VERSION ""

NS_ :

BS_:

BU_: CAM TESTER RS VCU GW ESC ACU TCM
VAL_TABLE_ RS_Sts_Failure 1 "Sensor Failure Occurred" 0 "No Sensor Failure Occured" ;

BO_ 482 PEPS_Message_Sts: 8 GW
 SG_ PEPS_PowerModeValidity : 1|2@0+ (1,0) [0|3] "bit"  RS
 SG_ PEPS_Message_Sts_Checksum : 63|8@0+ (1,0) [0|255] "bit"  RS
 SG_ PEPS_Message_Sts_AliveCounter : 51|4@0+ (1,0) [0|15] "bit"  RS
 SG_ PEPS_PowerMode : 4|3@0+ (1,0) [0|7] "bit"  RS

BO_ 644 BCM_StateUpdate: 8 GW
 SG_ BCM_ATWS_St : 31|3@0+ (1,0) [0|7] "bit"  RS

BO_ 646 BCM_RDoorWindowState: 8 GW
 SG_ BCM_DoorLockStatusRR : 35|2@0+ (1,0) [0|3] "bit"  RS
 SG_ BCM_DoorLockStatusPass : 37|2@0+ (1,0) [0|3] "bit"  RS
 SG_ BCM_RearRightDoorAjarStatus : 33|1@0+ (1,0) [0|1] "bit"  RS
 SG_ BCM_FrontRightDoorAjarStatus : 32|1@0+ (1,0) [0|1] "bit"  RS

BO_ 645 BCM_LDoorWindowState: 8 GW
 SG_ BCM_DoorLockStatusRL : 35|2@0+ (1,0) [0|3] "bit"  RS
 SG_ BCM_DoorLockStatusDrv : 37|2@0+ (1,0) [0|3] "bit"  RS
 SG_ BCM_RearLeftDoorAjarStatus : 33|1@0+ (1,0) [0|1] "bit"  RS
 SG_ BCM_FrontLeftDoorAjarStatus : 32|1@0+ (1,0) [0|1] "bit"  RS

BO_ 496 BCM_LightChimeReq: 8 GW
 SG_ BCM_LightChimeReq_AliveCounter : 51|4@0+ (1,0) [0|15] "bit"  RS
 SG_ BCM_LightChimeReq_CheckSum : 63|8@0+ (1,0) [0|255] "bit"  RS
 SG_ BCM_TurnLeverSts : 5|2@0+ (1,0) [0|3] "bit"  RS

BO_ 1518 RS_Detn_14_Part02: 8 RS
 SG_ RS_Detn14_Elev : 28|5@0+ (1,-15) [-15|15] "Deg"  CAM
 SG_ RS_Detn14_YVelRel : 39|11@0+ (0.1,-102.4) [-102.4|102.3] "m/s"  CAM
 SG_ RS_Detn14_XVelRel : 23|11@0+ (0.1,-102.4) [-102.4|102.3] "m/s"  CAM
 SG_ RS_Detn14_Msg02_CheckSum : 63|8@0+ (1,0) [0|255] "bit"  CAM
 SG_ RS_Detn14_Msg02_AliveCounter : 51|4@0+ (1,0) [0|15] "bit"  CAM
 SG_ RS_Detn14_Qly : 7|16@0+ (1,0) [0|65535] "bit"  CAM
 SG_ RS_Detn14_MotnSts : 55|2@0+ (1,0) [0|3] "bit"  CAM

BO_ 1501 RS_Detn_13_Part01: 8 RS
 SG_ RS_Detn13_Magn : 47|10@0+ (0.1,0) [0|102.3] "dB"  CAM
 SG_ RS_Detn13_Msg01_CheckSum : 63|8@0+ (1,0) [0|255] "bit"  CAM
 SG_ RS_Detn13_Msg01_AliveCounter : 51|4@0+ (1,0) [0|15] "bit"  CAM
 SG_ RS_Detn13_PosY : 31|14@0+ (0.02441,-200) [-200|199.90903] "m"  CAM
 SG_ RS_Detn13_ID : 7|8@0+ (1,0) [0|255] "bit"  CAM
 SG_ RS_Detn13_PosX : 15|14@0+ (0.02441,-200) [-200|199.90903] "m"  CAM

BO_ 1515 RS_Detn_11_Part02: 8 RS
 SG_ RS_Detn11_Elev : 28|5@0+ (1,-15) [-15|15] "Deg"  CAM
 SG_ RS_Detn11_YVelRel : 39|11@0+ (0.1,-102.4) [-102.4|102.3] "m/s"  CAM
 SG_ RS_Detn11_XVelRel : 23|11@0+ (0.1,-102.4) [-102.4|102.3] "m/s"  CAM
 SG_ RS_Detn11_Msg02_CheckSum : 63|8@0+ (1,0) [0|255] "bit"  CAM
 SG_ RS_Detn11_Msg02_AliveCounter : 51|4@0+ (1,0) [0|15] "bit"  CAM
 SG_ RS_Detn11_Qly : 7|16@0+ (1,0) [0|65535] "bit"  CAM
 SG_ RS_Detn11_MotnSts : 55|2@0+ (1,0) [0|3] "bit"  CAM

BO_ 1498 RS_Detn_10_Part01: 8 RS
 SG_ RS_Detn10_Magn : 47|10@0+ (0.1,0) [0|102.3] "dB"  CAM
 SG_ RS_Detn10_Msg01_CheckSum : 63|8@0+ (1,0) [0|255] "bit"  CAM
 SG_ RS_Detn10_Msg01_AliveCounter : 51|4@0+ (1,0) [0|15] "bit"  CAM
 SG_ RS_Detn10_PosY : 31|14@0+ (0.02441,-200) [-200|199.90903] "m"  CAM
 SG_ RS_Detn10_ID : 7|8@0+ (1,0) [0|255] "bit"  CAM
 SG_ RS_Detn10_PosX : 15|14@0+ (0.02441,-200) [-200|199.90903] "m"  CAM

BO_ 1512 RS_Detn_08_Part02: 8 RS
 SG_ RS_Detn08_Elev : 28|5@0+ (1,-15) [-15|15] "Deg"  CAM
 SG_ RS_Detn08_YVelRel : 39|11@0+ (0.1,-102.4) [-102.4|102.3] "m/s"  CAM
 SG_ RS_Detn08_XVelRel : 23|11@0+ (0.1,-102.4) [-102.4|102.3] "m/s"  CAM
 SG_ RS_Detn08_Msg02_CheckSum : 63|8@0+ (1,0) [0|255] "bit"  CAM
 SG_ RS_Detn08_Msg02_AliveCounter : 51|4@0+ (1,0) [0|15] "bit"  CAM
 SG_ RS_Detn08_Qly : 7|16@0+ (1,0) [0|65535] "bit"  CAM
 SG_ RS_Detn08_MotnSts : 55|2@0+ (1,0) [0|3] "bit"  CAM

BO_ 1495 RS_Detn_07_Part01: 8 RS
 SG_ RS_Detn07_Magn : 47|10@0+ (0.1,0) [0|102.3] "dB"  CAM
 SG_ RS_Detn07_Msg01_CheckSum : 63|8@0+ (1,0) [0|255] "bit"  CAM
 SG_ RS_Detn07_Msg01_AliveCounter : 51|4@0+ (1,0) [0|15] "bit"  CAM
 SG_ RS_Detn07_PosY : 15|14@0+ (0.02441,-200) [-200|199.90903] "m"  CAM
 SG_ RS_Detn07_ID : 7|8@0+ (1,0) [0|255] "bit"  CAM
 SG_ RS_Detn07_PosX : 31|14@0+ (0.02441,-200) [-200|199.90903] "m"  CAM

BO_ 1509 RS_Detn_05_Part02: 8 RS
 SG_ RS_Detn05_Elev : 28|5@0+ (1,-15) [-15|15] "Deg"  CAM
 SG_ RS_Detn05_YVelRel : 39|11@0+ (0.1,-102.4) [-102.4|102.3] "m/s"  CAM
 SG_ RS_Detn05_XVelRel : 23|11@0+ (0.1,-102.4) [-102.4|102.3] "m/s"  CAM
 SG_ RS_Detn05_Msg02_CheckSum : 63|8@0+ (1,0) [0|255] "bit"  CAM
 SG_ RS_Detn05_Msg02_AliveCounter : 51|4@0+ (1,0) [0|15] "bit"  CAM
 SG_ RS_Detn05_Qly : 7|16@0+ (1,0) [0|65535] "bit"  CAM
 SG_ RS_Detn05_MotnSts : 55|2@0+ (1,0) [0|3] "bit"  CAM

BO_ 1492 RS_Detn_04_Part01: 8 RS
 SG_ RS_Detn04_Magn : 47|10@0+ (0.1,0) [0|102.3] "dB"  CAM
 SG_ RS_Detn04_Msg01_CheckSum : 63|8@0+ (1,0) [0|255] "bit"  CAM
 SG_ RS_Detn04_Msg01_AliveCounter : 51|4@0+ (1,0) [0|15] "bit"  CAM
 SG_ RS_Detn04_PosY : 31|14@0+ (0.02441,-200) [-200|199.90903] "m"  CAM
 SG_ RS_Detn04_ID : 7|8@0+ (1,0) [0|255] "bit"  CAM
 SG_ RS_Detn04_PosX : 15|14@0+ (0.02441,-200) [-200|199.90903] "m"  CAM

BO_ 1506 RS_Detn_02_Part02: 8 RS
 SG_ RS_Detn02_Elev : 28|5@0+ (1,-15) [-15|15] "Deg"  CAM
 SG_ RS_Detn02_YVelRel : 39|11@0+ (0.1,-102.4) [-102.4|102.3] "m/s"  CAM
 SG_ RS_Detn02_XVelRel : 23|11@0+ (0.1,-102.4) [-102.4|102.3] "m/s"  CAM
 SG_ RS_Detn02_Msg02_CheckSum : 63|8@0+ (1,0) [0|255] "bit"  CAM
 SG_ RS_Detn02_Msg02_AliveCounter : 51|4@0+ (1,0) [0|15] "bit"  CAM
 SG_ RS_Detn02_Qly : 7|16@0+ (1,0) [0|65535] "bit"  CAM
 SG_ RS_Detn02_MotnSts : 55|2@0+ (1,0) [0|3] "bit"  CAM

BO_ 1489 RS_Detn_01_Part01: 8 RS
 SG_ RS_Detn01_Magn : 47|10@0+ (0.1,0) [0|102.3] "dB"  CAM
 SG_ RS_Detn01_Msg01_CheckSum : 63|8@0+ (1,0) [0|255] "bit"  CAM
 SG_ RS_Detn01_Msg01_AliveCounter : 51|4@0+ (1,0) [0|15] "bit"  CAM
 SG_ RS_Detn01_PosY : 31|14@0+ (0.02441,-200) [-200|199.90903] "m"  CAM
 SG_ RS_Detn01_ID : 7|8@0+ (1,0) [0|255] "bit"  CAM
 SG_ RS_Detn01_PosX : 15|14@0+ (0.02441,-200) [-200|199.90903] "m"  CAM

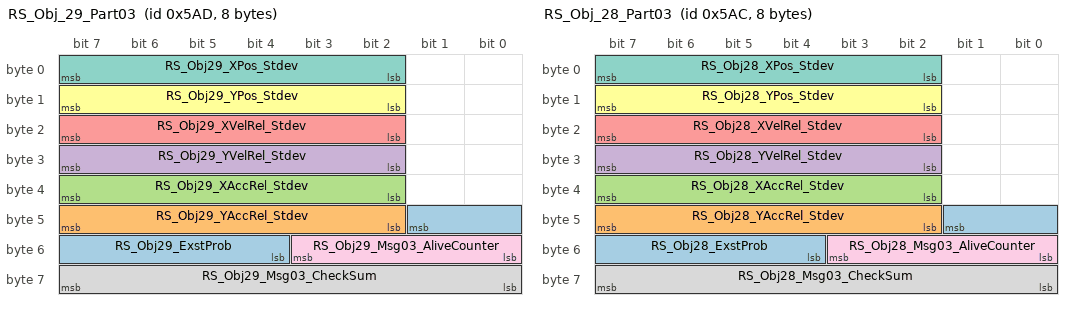
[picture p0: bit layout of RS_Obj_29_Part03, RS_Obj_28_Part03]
BO_ 1453 RS_Obj_29_Part03: 8 RS
 SG_ RS_Obj29_ExstProb : 41|6@0+ (1,0) [0|63] "bit"  CAM
 SG_ RS_Obj29_YAccRel_Stdev : 47|6@0+ (0.2,0) [0|12.6] "m/s2"  CAM
 SG_ RS_Obj29_XAccRel_Stdev : 39|6@0+ (0.2,0) [0|12.6] "m/s2"  CAM
 SG_ RS_Obj29_YVelRel_Stdev : 31|6@0+ (0.2,0) [0|12.6] "m/s"  CAM
 SG_ RS_Obj29_XVelRel_Stdev : 23|6@0+ (0.2,0) [0|12.6] "m/s"  CAM
 SG_ RS_Obj29_YPos_Stdev : 15|6@0+ (0.2,0) [0|12.6] "m"  CAM
 SG_ RS_Obj29_XPos_Stdev : 7|6@0+ (0.2,0) [0|12.6] "m"  CAM
 SG_ RS_Obj29_Msg03_CheckSum : 63|8@0+ (1,0) [0|255] "bit"  CAM
 SG_ RS_Obj29_Msg03_AliveCounter : 51|4@0+ (1,0) [0|15] "bit"  CAM

BO_ 1452 RS_Obj_28_Part03: 8 RS
 SG_ RS_Obj28_ExstProb : 41|6@0+ (1,0) [0|63] "bit"  CAM
 SG_ RS_Obj28_YAccRel_Stdev : 47|6@0+ (0.2,0) [0|12.6] "m/s2"  CAM
 SG_ RS_Obj28_XAccRel_Stdev : 39|6@0+ (0.2,0) [0|12.6] "m/s2"  CAM
 SG_ RS_Obj28_YVelRel_Stdev : 31|6@0+ (0.2,0) [0|12.6] "m/s"  CAM
 SG_ RS_Obj28_XVelRel_Stdev : 23|6@0+ (0.2,0) [0|12.6] "m/s"  CAM
 SG_ RS_Obj28_YPos_Stdev : 15|6@0+ (0.2,0) [0|12.6] "m"  CAM
 SG_ RS_Obj28_XPos_Stdev : 7|6@0+ (0.2,0) [0|12.6] "m"  CAM
 SG_ RS_Obj28_Msg03_CheckSum : 63|8@0+ (1,0) [0|255] "bit"  CAM
 SG_ RS_Obj28_Msg03_AliveCounter : 51|4@0+ (1,0) [0|15] "bit"  CAM

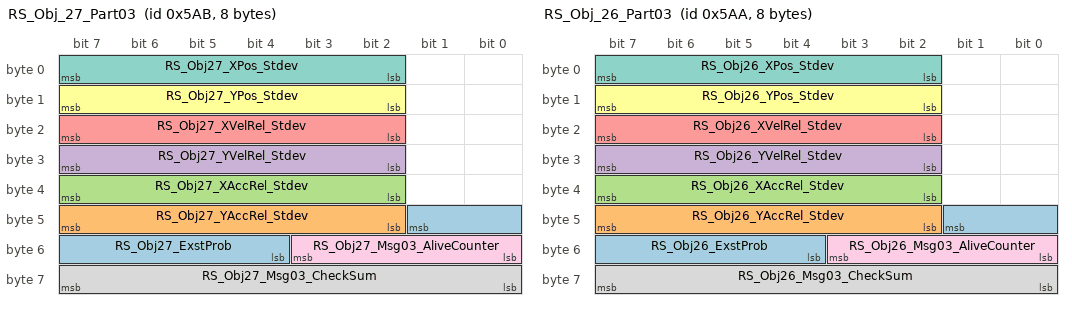
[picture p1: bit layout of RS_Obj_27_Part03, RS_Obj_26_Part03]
BO_ 1451 RS_Obj_27_Part03: 8 RS
 SG_ RS_Obj27_ExstProb : 41|6@0+ (1,0) [0|63] "bit"  CAM
 SG_ RS_Obj27_YAccRel_Stdev : 47|6@0+ (0.2,0) [0|12.6] "m/s2"  CAM
 SG_ RS_Obj27_XAccRel_Stdev : 39|6@0+ (0.2,0) [0|12.6] "m/s2"  CAM
 SG_ RS_Obj27_YVelRel_Stdev : 31|6@0+ (0.2,0) [0|12.6] "m/s"  CAM
 SG_ RS_Obj27_XVelRel_Stdev : 23|6@0+ (0.2,0) [0|12.6] "m/s"  CAM
 SG_ RS_Obj27_YPos_Stdev : 15|6@0+ (0.2,0) [0|12.6] "m"  CAM
 SG_ RS_Obj27_XPos_Stdev : 7|6@0+ (0.2,0) [0|12.6] "m"  CAM
 SG_ RS_Obj27_Msg03_CheckSum : 63|8@0+ (1,0) [0|255] "bit"  CAM
 SG_ RS_Obj27_Msg03_AliveCounter : 51|4@0+ (1,0) [0|15] "bit"  CAM

BO_ 1450 RS_Obj_26_Part03: 8 RS
 SG_ RS_Obj26_ExstProb : 41|6@0+ (1,0) [0|63] "bit"  CAM
 SG_ RS_Obj26_YAccRel_Stdev : 47|6@0+ (0.2,0) [0|12.6] "m/s2"  CAM
 SG_ RS_Obj26_XAccRel_Stdev : 39|6@0+ (0.2,0) [0|12.6] "m/s2"  CAM
 SG_ RS_Obj26_YVelRel_Stdev : 31|6@0+ (0.2,0) [0|12.6] "m/s"  CAM
 SG_ RS_Obj26_XVelRel_Stdev : 23|6@0+ (0.2,0) [0|12.6] "m/s"  CAM
 SG_ RS_Obj26_YPos_Stdev : 15|6@0+ (0.2,0) [0|12.6] "m"  CAM
 SG_ RS_Obj26_XPos_Stdev : 7|6@0+ (0.2,0) [0|12.6] "m"  CAM
 SG_ RS_Obj26_Msg03_CheckSum : 63|8@0+ (1,0) [0|255] "bit"  CAM
 SG_ RS_Obj26_Msg03_AliveCounter : 51|4@0+ (1,0) [0|15] "bit"  CAM

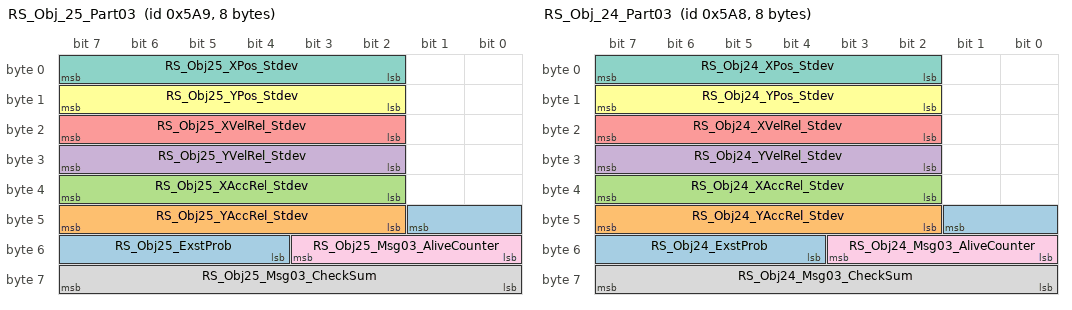
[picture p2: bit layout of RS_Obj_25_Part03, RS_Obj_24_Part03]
BO_ 1449 RS_Obj_25_Part03: 8 RS
 SG_ RS_Obj25_ExstProb : 41|6@0+ (1,0) [0|63] "bit"  CAM
 SG_ RS_Obj25_YAccRel_Stdev : 47|6@0+ (0.2,0) [0|12.6] "m/s2"  CAM
 SG_ RS_Obj25_XAccRel_Stdev : 39|6@0+ (0.2,0) [0|12.6] "m/s2"  CAM
 SG_ RS_Obj25_YVelRel_Stdev : 31|6@0+ (0.2,0) [0|12.6] "m/s"  CAM
 SG_ RS_Obj25_XVelRel_Stdev : 23|6@0+ (0.2,0) [0|12.6] "m/s"  CAM
 SG_ RS_Obj25_YPos_Stdev : 15|6@0+ (0.2,0) [0|12.6] "m"  CAM
 SG_ RS_Obj25_XPos_Stdev : 7|6@0+ (0.2,0) [0|12.6] "m"  CAM
 SG_ RS_Obj25_Msg03_CheckSum : 63|8@0+ (1,0) [0|255] "bit"  CAM
 SG_ RS_Obj25_Msg03_AliveCounter : 51|4@0+ (1,0) [0|15] "bit"  CAM

BO_ 1448 RS_Obj_24_Part03: 8 RS
 SG_ RS_Obj24_ExstProb : 41|6@0+ (1,0) [0|63] "bit"  CAM
 SG_ RS_Obj24_YAccRel_Stdev : 47|6@0+ (0.2,0) [0|12.6] "m/s2"  CAM
 SG_ RS_Obj24_XAccRel_Stdev : 39|6@0+ (0.2,0) [0|12.6] "m/s2"  CAM
 SG_ RS_Obj24_YVelRel_Stdev : 31|6@0+ (0.2,0) [0|12.6] "m/s"  CAM
 SG_ RS_Obj24_XVelRel_Stdev : 23|6@0+ (0.2,0) [0|12.6] "m/s"  CAM
 SG_ RS_Obj24_YPos_Stdev : 15|6@0+ (0.2,0) [0|12.6] "m"  CAM
 SG_ RS_Obj24_XPos_Stdev : 7|6@0+ (0.2,0) [0|12.6] "m"  CAM
 SG_ RS_Obj24_Msg03_CheckSum : 63|8@0+ (1,0) [0|255] "bit"  CAM
 SG_ RS_Obj24_Msg03_AliveCounter : 51|4@0+ (1,0) [0|15] "bit"  CAM

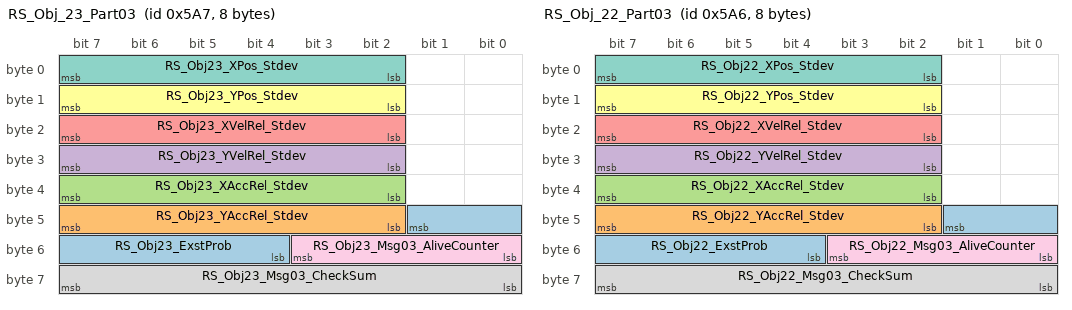
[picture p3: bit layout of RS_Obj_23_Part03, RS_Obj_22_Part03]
BO_ 1447 RS_Obj_23_Part03: 8 RS
 SG_ RS_Obj23_ExstProb : 41|6@0+ (1,0) [0|63] "bit"  CAM
 SG_ RS_Obj23_YAccRel_Stdev : 47|6@0+ (0.2,0) [0|12.6] "m/s2"  CAM
 SG_ RS_Obj23_XAccRel_Stdev : 39|6@0+ (0.2,0) [0|12.6] "m/s2"  CAM
 SG_ RS_Obj23_YVelRel_Stdev : 31|6@0+ (0.2,0) [0|12.6] "m/s"  CAM
 SG_ RS_Obj23_XVelRel_Stdev : 23|6@0+ (0.2,0) [0|12.6] "m/s"  CAM
 SG_ RS_Obj23_YPos_Stdev : 15|6@0+ (0.2,0) [0|12.6] "m"  CAM
 SG_ RS_Obj23_XPos_Stdev : 7|6@0+ (0.2,0) [0|12.6] "m"  CAM
 SG_ RS_Obj23_Msg03_CheckSum : 63|8@0+ (1,0) [0|255] "bit"  CAM
 SG_ RS_Obj23_Msg03_AliveCounter : 51|4@0+ (1,0) [0|15] "bit"  CAM

BO_ 1446 RS_Obj_22_Part03: 8 RS
 SG_ RS_Obj22_ExstProb : 41|6@0+ (1,0) [0|63] "bit"  CAM
 SG_ RS_Obj22_YAccRel_Stdev : 47|6@0+ (0.2,0) [0|12.6] "m/s2"  CAM
 SG_ RS_Obj22_XAccRel_Stdev : 39|6@0+ (0.2,0) [0|12.6] "m/s2"  CAM
 SG_ RS_Obj22_YVelRel_Stdev : 31|6@0+ (0.2,0) [0|12.6] "m/s"  CAM
 SG_ RS_Obj22_XVelRel_Stdev : 23|6@0+ (0.2,0) [0|12.6] "m/s"  CAM
 SG_ RS_Obj22_YPos_Stdev : 15|6@0+ (0.2,0) [0|12.6] "m"  CAM
 SG_ RS_Obj22_XPos_Stdev : 7|6@0+ (0.2,0) [0|12.6] "m"  CAM
 SG_ RS_Obj22_Msg03_CheckSum : 63|8@0+ (1,0) [0|255] "bit"  CAM
 SG_ RS_Obj22_Msg03_AliveCounter : 51|4@0+ (1,0) [0|15] "bit"  CAM

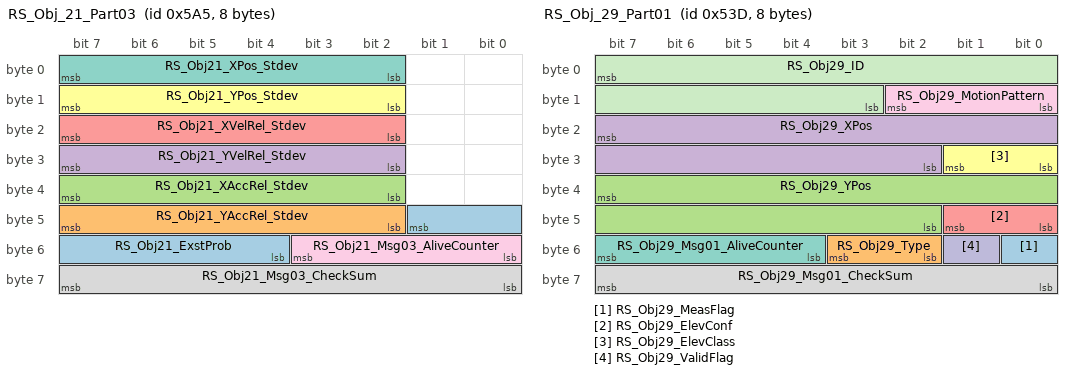
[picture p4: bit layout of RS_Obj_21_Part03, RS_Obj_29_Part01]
BO_ 1445 RS_Obj_21_Part03: 8 RS
 SG_ RS_Obj21_ExstProb : 41|6@0+ (1,0) [0|63] "bit"  CAM
 SG_ RS_Obj21_YAccRel_Stdev : 47|6@0+ (0.2,0) [0|12.6] "m/s2"  CAM
 SG_ RS_Obj21_XAccRel_Stdev : 39|6@0+ (0.2,0) [0|12.6] "m/s2"  CAM
 SG_ RS_Obj21_YVelRel_Stdev : 31|6@0+ (0.2,0) [0|12.6] "m/s"  CAM
 SG_ RS_Obj21_XVelRel_Stdev : 23|6@0+ (0.2,0) [0|12.6] "m/s"  CAM
 SG_ RS_Obj21_YPos_Stdev : 15|6@0+ (0.2,0) [0|12.6] "m"  CAM
 SG_ RS_Obj21_XPos_Stdev : 7|6@0+ (0.2,0) [0|12.6] "m"  CAM
 SG_ RS_Obj21_Msg03_CheckSum : 63|8@0+ (1,0) [0|255] "bit"  CAM
 SG_ RS_Obj21_Msg03_AliveCounter : 51|4@0+ (1,0) [0|15] "bit"  CAM

BO_ 1444 RS_Obj_20_Part03: 8 RS
 SG_ RS_Obj20_ExstProb : 41|6@0+ (1,0) [0|63] "bit"  CAM
 SG_ RS_Obj20_YAccRel_Stdev : 47|6@0+ (0.2,0) [0|12.6] "m/s2"  CAM
 SG_ RS_Obj20_XAccRel_Stdev : 39|6@0+ (0.2,0) [0|12.6] "m/s2"  CAM
 SG_ RS_Obj20_YVelRel_Stdev : 31|6@0+ (0.2,0) [0|12.6] "m/s"  CAM
 SG_ RS_Obj20_XVelRel_Stdev : 23|6@0+ (0.2,0) [0|12.6] "m/s"  CAM
 SG_ RS_Obj20_YPos_Stdev : 15|6@0+ (0.2,0) [0|12.6] "m"  CAM
 SG_ RS_Obj20_XPos_Stdev : 7|6@0+ (0.2,0) [0|12.6] "m"  CAM
 SG_ RS_Obj20_Msg03_CheckSum : 63|8@0+ (1,0) [0|255] "bit"  CAM
 SG_ RS_Obj20_Msg03_AliveCounter : 51|4@0+ (1,0) [0|15] "bit"  CAM

BO_ 1443 RS_Obj_19_Part03: 8 RS
 SG_ RS_Obj19_ExstProb : 41|6@0+ (1,0) [0|63] "bit"  CAM
 SG_ RS_Obj19_YAccRel_Stdev : 47|6@0+ (0.2,0) [0|12.6] "m/s2"  CAM
 SG_ RS_Obj19_XAccRel_Stdev : 39|6@0+ (0.2,0) [0|12.6] "m/s2"  CAM
 SG_ RS_Obj19_YVelRel_Stdev : 31|6@0+ (0.2,0) [0|12.6] "m/s"  CAM
 SG_ RS_Obj19_XVelRel_Stdev : 23|6@0+ (0.2,0) [0|12.6] "m/s"  CAM
 SG_ RS_Obj19_YPos_Stdev : 15|6@0+ (0.2,0) [0|12.6] "m"  CAM
 SG_ RS_Obj19_XPos_Stdev : 7|6@0+ (0.2,0) [0|12.6] "m"  CAM
 SG_ RS_Obj19_Msg03_CheckSum : 63|8@0+ (1,0) [0|255] "bit"  CAM
 SG_ RS_Obj19_Msg03_AliveCounter : 51|4@0+ (1,0) [0|15] "bit"  CAM

BO_ 1442 RS_Obj_18_Part03: 8 RS
 SG_ RS_Obj18_ExstProb : 41|6@0+ (1,0) [0|63] "bit"  CAM
 SG_ RS_Obj18_YAccRel_Stdev : 47|6@0+ (0.2,0) [0|12.6] "m/s2"  CAM
 SG_ RS_Obj18_XAccRel_Stdev : 39|6@0+ (0.2,0) [0|12.6] "m/s2"  CAM
 SG_ RS_Obj18_YVelRel_Stdev : 31|6@0+ (0.2,0) [0|12.6] "m/s"  CAM
 SG_ RS_Obj18_XVelRel_Stdev : 23|6@0+ (0.2,0) [0|12.6] "m/s"  CAM
 SG_ RS_Obj18_YPos_Stdev : 15|6@0+ (0.2,0) [0|12.6] "m"  CAM
 SG_ RS_Obj18_XPos_Stdev : 7|6@0+ (0.2,0) [0|12.6] "m"  CAM
 SG_ RS_Obj18_Msg03_CheckSum : 63|8@0+ (1,0) [0|255] "bit"  CAM
 SG_ RS_Obj18_Msg03_AliveCounter : 51|4@0+ (1,0) [0|15] "bit"  CAM

BO_ 1441 RS_Obj_17_Part03: 8 RS
 SG_ RS_Obj17_ExstProb : 41|6@0+ (1,0) [0|63] "bit"  CAM
 SG_ RS_Obj17_YAccRel_Stdev : 47|6@0+ (0.2,0) [0|12.6] "m/s2"  CAM
 SG_ RS_Obj17_XAccRel_Stdev : 39|6@0+ (0.2,0) [0|12.6] "m/s2"  CAM
 SG_ RS_Obj17_YVelRel_Stdev : 31|6@0+ (0.2,0) [0|12.6] "m/s"  CAM
 SG_ RS_Obj17_XVelRel_Stdev : 23|6@0+ (0.2,0) [0|12.6] "m/s"  CAM
 SG_ RS_Obj17_YPos_Stdev : 15|6@0+ (0.2,0) [0|12.6] "m"  CAM
 SG_ RS_Obj17_XPos_Stdev : 7|6@0+ (0.2,0) [0|12.6] "m"  CAM
 SG_ RS_Obj17_Msg03_CheckSum : 63|8@0+ (1,0) [0|255] "bit"  CAM
 SG_ RS_Obj17_Msg03_AliveCounter : 51|4@0+ (1,0) [0|15] "bit"  CAM

BO_ 1440 RS_Obj_16_Part03: 8 RS
 SG_ RS_Obj16_ExstProb : 41|6@0+ (1,0) [0|63] "bit"  CAM
 SG_ RS_Obj16_YAccRel_Stdev : 47|6@0+ (0.2,0) [0|12.6] "m/s2"  CAM
 SG_ RS_Obj16_XAccRel_Stdev : 39|6@0+ (0.2,0) [0|12.6] "m/s2"  CAM
 SG_ RS_Obj16_YVelRel_Stdev : 31|6@0+ (0.2,0) [0|12.6] "m/s"  CAM
 SG_ RS_Obj16_XVelRel_Stdev : 23|6@0+ (0.2,0) [0|12.6] "m/s"  CAM
 SG_ RS_Obj16_YPos_Stdev : 15|6@0+ (0.2,0) [0|12.6] "m"  CAM
 SG_ RS_Obj16_XPos_Stdev : 7|6@0+ (0.2,0) [0|12.6] "m"  CAM
 SG_ RS_Obj16_Msg03_CheckSum : 63|8@0+ (1,0) [0|255] "bit"  CAM
 SG_ RS_Obj16_Msg03_AliveCounter : 51|4@0+ (1,0) [0|15] "bit"  CAM

BO_ 1439 RS_Obj_15_Part03: 8 RS
 SG_ RS_Obj15_ExstProb : 41|6@0+ (1,0) [0|63] "bit"  CAM
 SG_ RS_Obj15_YAccRel_Stdev : 47|6@0+ (0.2,0) [0|12.6] "m/s2"  CAM
 SG_ RS_Obj15_XAccRel_Stdev : 39|6@0+ (0.2,0) [0|12.6] "m/s2"  CAM
 SG_ RS_Obj15_YVelRel_Stdev : 31|6@0+ (0.2,0) [0|12.6] "m/s"  CAM
 SG_ RS_Obj15_XVelRel_Stdev : 23|6@0+ (0.2,0) [0|12.6] "m/s"  CAM
 SG_ RS_Obj15_YPos_Stdev : 15|6@0+ (0.2,0) [0|12.6] "m"  CAM
 SG_ RS_Obj15_XPos_Stdev : 7|6@0+ (0.2,0) [0|12.6] "m"  CAM
 SG_ RS_Obj15_Msg03_CheckSum : 63|8@0+ (1,0) [0|255] "bit"  CAM
 SG_ RS_Obj15_Msg03_AliveCounter : 51|4@0+ (1,0) [0|15] "bit"  CAM

BO_ 1438 RS_Obj_14_Part03: 8 RS
 SG_ RS_Obj14_ExstProb : 41|6@0+ (1,0) [0|63] "bit"  CAM
 SG_ RS_Obj14_YAccRel_Stdev : 47|6@0+ (0.2,0) [0|12.6] "m/s2"  CAM
 SG_ RS_Obj14_XAccRel_Stdev : 39|6@0+ (0.2,0) [0|12.6] "m/s2"  CAM
 SG_ RS_Obj14_YVelRel_Stdev : 31|6@0+ (0.2,0) [0|12.6] "m/s"  CAM
 SG_ RS_Obj14_XVelRel_Stdev : 23|6@0+ (0.2,0) [0|12.6] "m/s"  CAM
 SG_ RS_Obj14_YPos_Stdev : 15|6@0+ (0.2,0) [0|12.6] "m"  CAM
 SG_ RS_Obj14_XPos_Stdev : 7|6@0+ (0.2,0) [0|12.6] "m"  CAM
 SG_ RS_Obj14_Msg03_CheckSum : 63|8@0+ (1,0) [0|255] "bit"  CAM
 SG_ RS_Obj14_Msg03_AliveCounter : 51|4@0+ (1,0) [0|15] "bit"  CAM

BO_ 1437 RS_Obj_13_Part03: 8 RS
 SG_ RS_Obj13_ExstProb : 41|6@0+ (1,0) [0|63] "bit"  CAM
 SG_ RS_Obj13_YAccRel_Stdev : 47|6@0+ (0.2,0) [0|12.6] "m/s2"  CAM
 SG_ RS_Obj13_XAccRel_Stdev : 39|6@0+ (0.2,0) [0|12.6] "m/s2"  CAM
 SG_ RS_Obj13_YVelRel_Stdev : 31|6@0+ (0.2,0) [0|12.6] "m/s"  CAM
 SG_ RS_Obj13_XVelRel_Stdev : 23|6@0+ (0.2,0) [0|12.6] "m/s"  CAM
 SG_ RS_Obj13_YPos_Stdev : 15|6@0+ (0.2,0) [0|12.6] "m"  CAM
 SG_ RS_Obj13_XPos_Stdev : 7|6@0+ (0.2,0) [0|12.6] "m"  CAM
 SG_ RS_Obj13_Msg03_CheckSum : 63|8@0+ (1,0) [0|255] "bit"  CAM
 SG_ RS_Obj13_Msg03_AliveCounter : 51|4@0+ (1,0) [0|15] "bit"  CAM

BO_ 1436 RS_Obj_12_Part03: 8 RS
 SG_ RS_Obj12_ExstProb : 41|6@0+ (1,0) [0|63] "bit"  CAM
 SG_ RS_Obj12_YAccRel_Stdev : 47|6@0+ (0.2,0) [0|12.6] "m/s2"  CAM
 SG_ RS_Obj12_XAccRel_Stdev : 39|6@0+ (0.2,0) [0|12.6] "m/s2"  CAM
 SG_ RS_Obj12_YVelRel_Stdev : 31|6@0+ (0.2,0) [0|12.6] "m/s"  CAM
 SG_ RS_Obj12_XVelRel_Stdev : 23|6@0+ (0.2,0) [0|12.6] "m/s"  CAM
 SG_ RS_Obj12_YPos_Stdev : 15|6@0+ (0.2,0) [0|12.6] "m"  CAM
 SG_ RS_Obj12_XPos_Stdev : 7|6@0+ (0.2,0) [0|12.6] "m"  CAM
 SG_ RS_Obj12_Msg03_CheckSum : 63|8@0+ (1,0) [0|255] "bit"  CAM
 SG_ RS_Obj12_Msg03_AliveCounter : 51|4@0+ (1,0) [0|15] "bit"  CAM

BO_ 1435 RS_Obj_11_Part03: 8 RS
 SG_ RS_Obj11_ExstProb : 41|6@0+ (1,0) [0|63] "bit"  CAM
 SG_ RS_Obj11_YAccRel_Stdev : 47|6@0+ (0.2,0) [0|12.6] "m/s2"  CAM
 SG_ RS_Obj11_XAccRel_Stdev : 39|6@0+ (0.2,0) [0|12.6] "m/s2"  CAM
 SG_ RS_Obj11_YVelRel_Stdev : 31|6@0+ (0.2,0) [0|12.6] "m/s"  CAM
 SG_ RS_Obj11_XVelRel_Stdev : 23|6@0+ (0.2,0) [0|12.6] "m/s"  CAM
 SG_ RS_Obj11_YPos_Stdev : 15|6@0+ (0.2,0) [0|12.6] "m"  CAM
 SG_ RS_Obj11_XPos_Stdev : 7|6@0+ (0.2,0) [0|12.6] "m"  CAM
 SG_ RS_Obj11_Msg03_CheckSum : 63|8@0+ (1,0) [0|255] "bit"  CAM
 SG_ RS_Obj11_Msg03_AliveCounter : 51|4@0+ (1,0) [0|15] "bit"  CAM

BO_ 1434 RS_Obj_10_Part03: 8 RS
 SG_ RS_Obj10_ExstProb : 41|6@0+ (1,0) [0|63] "bit"  CAM
 SG_ RS_Obj10_YAccRel_Stdev : 47|6@0+ (0.2,0) [0|12.6] "m/s2"  CAM
 SG_ RS_Obj10_XAccRel_Stdev : 39|6@0+ (0.2,0) [0|12.6] "m/s2"  CAM
 SG_ RS_Obj10_YVelRel_Stdev : 31|6@0+ (0.2,0) [0|12.6] "m/s"  CAM
 SG_ RS_Obj10_XVelRel_Stdev : 23|6@0+ (0.2,0) [0|12.6] "m/s"  CAM
 SG_ RS_Obj10_YPos_Stdev : 15|6@0+ (0.2,0) [0|12.6] "m"  CAM
 SG_ RS_Obj10_XPos_Stdev : 7|6@0+ (0.2,0) [0|12.6] "m"  CAM
 SG_ RS_Obj10_Msg03_CheckSum : 63|8@0+ (1,0) [0|255] "bit"  CAM
 SG_ RS_Obj10_Msg03_AliveCounter : 51|4@0+ (1,0) [0|15] "bit"  CAM

BO_ 1433 RS_Obj_09_Part03: 8 RS
 SG_ RS_Obj09_ExstProb : 41|6@0+ (1,0) [0|63] "bit"  CAM
 SG_ RS_Obj09_YAccRel_Stdev : 47|6@0+ (0.2,0) [0|12.6] "m/s2"  CAM
 SG_ RS_Obj09_XAccRel_Stdev : 39|6@0+ (0.2,0) [0|12.6] "m/s2"  CAM
 SG_ RS_Obj09_YVelRel_Stdev : 31|6@0+ (0.2,0) [0|12.6] "m/s"  CAM
 SG_ RS_Obj09_XVelRel_Stdev : 23|6@0+ (0.2,0) [0|12.6] "m/s"  CAM
 SG_ RS_Obj09_YPos_Stdev : 15|6@0+ (0.2,0) [0|12.6] "m"  CAM
 SG_ RS_Obj09_XPos_Stdev : 7|6@0+ (0.2,0) [0|12.6] "m"  CAM
 SG_ RS_Obj09_Msg03_CheckSum : 63|8@0+ (1,0) [0|255] "bit"  CAM
 SG_ RS_Obj09_Msg03_AliveCounter : 51|4@0+ (1,0) [0|15] "bit"  CAM

BO_ 1432 RS_Obj_08_Part03: 8 RS
 SG_ RS_Obj08_ExstProb : 41|6@0+ (1,0) [0|63] "bit"  CAM
 SG_ RS_Obj08_YAccRel_Stdev : 47|6@0+ (0.2,0) [0|12.6] "m/s2"  CAM
 SG_ RS_Obj08_XAccRel_Stdev : 39|6@0+ (0.2,0) [0|12.6] "m/s2"  CAM
 SG_ RS_Obj08_YVelRel_Stdev : 31|6@0+ (0.2,0) [0|12.6] "m/s"  CAM
 SG_ RS_Obj08_XVelRel_Stdev : 23|6@0+ (0.2,0) [0|12.6] "m/s"  CAM
 SG_ RS_Obj08_YPos_Stdev : 15|6@0+ (0.2,0) [0|12.6] "m"  CAM
 SG_ RS_Obj08_XPos_Stdev : 7|6@0+ (0.2,0) [0|12.6] "m"  CAM
 SG_ RS_Obj08_Msg03_CheckSum : 63|8@0+ (1,0) [0|255] "bit"  CAM
 SG_ RS_Obj08_Msg03_AliveCounter : 51|4@0+ (1,0) [0|15] "bit"  CAM

BO_ 1431 RS_Obj_07_Part03: 8 RS
 SG_ RS_Obj07_ExstProb : 41|6@0+ (1,0) [0|63] "bit"  CAM
 SG_ RS_Obj07_YAccRel_Stdev : 47|6@0+ (0.2,0) [0|12.6] "m/s2"  CAM
 SG_ RS_Obj07_XAccRel_Stdev : 39|6@0+ (0.2,0) [0|12.6] "m/s2"  CAM
 SG_ RS_Obj07_YVelRel_Stdev : 31|6@0+ (0.2,0) [0|12.6] "m/s"  CAM
 SG_ RS_Obj07_XVelRel_Stdev : 23|6@0+ (0.2,0) [0|12.6] "m/s"  CAM
 SG_ RS_Obj07_YPos_Stdev : 15|6@0+ (0.2,0) [0|12.6] "m"  CAM
 SG_ RS_Obj07_XPos_Stdev : 7|6@0+ (0.2,0) [0|12.6] "m"  CAM
 SG_ RS_Obj07_Msg03_CheckSum : 63|8@0+ (1,0) [0|255] "bit"  CAM
 SG_ RS_Obj07_Msg03_AliveCounter : 51|4@0+ (1,0) [0|15] "bit"  CAM

BO_ 1430 RS_Obj_06_Part03: 8 RS
 SG_ RS_Obj06_ExstProb : 41|6@0+ (1,0) [0|63] "bit"  CAM
 SG_ RS_Obj06_YAccRel_Stdev : 47|6@0+ (0.2,0) [0|12.6] "m/s2"  CAM
 SG_ RS_Obj06_XAccRel_Stdev : 39|6@0+ (0.2,0) [0|12.6] "m/s2"  CAM
 SG_ RS_Obj06_YVelRel_Stdev : 31|6@0+ (0.2,0) [0|12.6] "m/s"  CAM
 SG_ RS_Obj06_XVelRel_Stdev : 23|6@0+ (0.2,0) [0|12.6] "m/s"  CAM
 SG_ RS_Obj06_YPos_Stdev : 15|6@0+ (0.2,0) [0|12.6] "m"  CAM
 SG_ RS_Obj06_XPos_Stdev : 7|6@0+ (0.2,0) [0|12.6] "m"  CAM
 SG_ RS_Obj06_Msg03_CheckSum : 63|8@0+ (1,0) [0|255] "bit"  CAM
 SG_ RS_Obj06_Msg03_AliveCounter : 51|4@0+ (1,0) [0|15] "bit"  CAM

BO_ 1429 RS_Obj_05_Part03: 8 RS
 SG_ RS_Obj05_ExstProb : 41|6@0+ (1,0) [0|63] "bit"  CAM
 SG_ RS_Obj05_YAccRel_Stdev : 47|6@0+ (0.2,0) [0|12.6] "m/s2"  CAM
 SG_ RS_Obj05_XAccRel_Stdev : 39|6@0+ (0.2,0) [0|12.6] "m/s2"  CAM
 SG_ RS_Obj05_YVelRel_Stdev : 31|6@0+ (0.2,0) [0|12.6] "m/s"  CAM
 SG_ RS_Obj05_XVelRel_Stdev : 23|6@0+ (0.2,0) [0|12.6] "m/s"  CAM
 SG_ RS_Obj05_YPos_Stdev : 15|6@0+ (0.2,0) [0|12.6] "m"  CAM
 SG_ RS_Obj05_XPos_Stdev : 7|6@0+ (0.2,0) [0|12.6] "m"  CAM
 SG_ RS_Obj05_Msg03_CheckSum : 63|8@0+ (1,0) [0|255] "bit"  CAM
 SG_ RS_Obj05_Msg03_AliveCounter : 51|4@0+ (1,0) [0|15] "bit"  CAM

BO_ 1428 RS_Obj_04_Part03: 8 RS
 SG_ RS_Obj04_ExstProb : 41|6@0+ (1,0) [0|63] "bit"  CAM
 SG_ RS_Obj04_YAccRel_Stdev : 47|6@0+ (0.2,0) [0|12.6] "m/s2"  CAM
 SG_ RS_Obj04_XAccRel_Stdev : 39|6@0+ (0.2,0) [0|12.6] "m/s2"  CAM
 SG_ RS_Obj04_YVelRel_Stdev : 31|6@0+ (0.2,0) [0|12.6] "m/s"  CAM
 SG_ RS_Obj04_XVelRel_Stdev : 23|6@0+ (0.2,0) [0|12.6] "m/s"  CAM
 SG_ RS_Obj04_YPos_Stdev : 15|6@0+ (0.2,0) [0|12.6] "m"  CAM
 SG_ RS_Obj04_XPos_Stdev : 7|6@0+ (0.2,0) [0|12.6] "m"  CAM
 SG_ RS_Obj04_Msg03_CheckSum : 63|8@0+ (1,0) [0|255] "bit"  CAM
 SG_ RS_Obj04_Msg03_AliveCounter : 51|4@0+ (1,0) [0|15] "bit"  CAM

BO_ 1427 RS_Obj_03_Part03: 8 RS
 SG_ RS_Obj03_ExstProb : 41|6@0+ (1,0) [0|63] "bit"  CAM
 SG_ RS_Obj03_YAccRel_Stdev : 47|6@0+ (0.2,0) [0|12.6] "m/s2"  CAM
 SG_ RS_Obj03_XAccRel_Stdev : 39|6@0+ (0.2,0) [0|12.6] "m/s2"  CAM
 SG_ RS_Obj03_YVelRel_Stdev : 31|6@0+ (0.2,0) [0|12.6] "m/s"  CAM
 SG_ RS_Obj03_XVelRel_Stdev : 23|6@0+ (0.2,0) [0|12.6] "m/s"  CAM
 SG_ RS_Obj03_YPos_Stdev : 15|6@0+ (0.2,0) [0|12.6] "m"  CAM
 SG_ RS_Obj03_XPos_Stdev : 7|6@0+ (0.2,0) [0|12.6] "m"  CAM
 SG_ RS_Obj03_Msg03_CheckSum : 63|8@0+ (1,0) [0|255] "bit"  CAM
 SG_ RS_Obj03_Msg03_AliveCounter : 51|4@0+ (1,0) [0|15] "bit"  CAM

BO_ 1426 RS_Obj_02_Part03: 8 RS
 SG_ RS_Obj02_ExstProb : 41|6@0+ (1,0) [0|63] "bit"  CAM
 SG_ RS_Obj02_YAccRel_Stdev : 47|6@0+ (0.2,0) [0|12.6] "m/s2"  CAM
 SG_ RS_Obj02_XAccRel_Stdev : 39|6@0+ (0.2,0) [0|12.6] "m/s2"  CAM
 SG_ RS_Obj02_YVelRel_Stdev : 31|6@0+ (0.2,0) [0|12.6] "m/s"  CAM
 SG_ RS_Obj02_XVelRel_Stdev : 23|6@0+ (0.2,0) [0|12.6] "m/s"  CAM
 SG_ RS_Obj02_YPos_Stdev : 15|6@0+ (0.2,0) [0|12.6] "m"  CAM
 SG_ RS_Obj02_XPos_Stdev : 7|6@0+ (0.2,0) [0|12.6] "m"  CAM
 SG_ RS_Obj02_Msg03_CheckSum : 63|8@0+ (1,0) [0|255] "bit"  CAM
 SG_ RS_Obj02_Msg03_AliveCounter : 51|4@0+ (1,0) [0|15] "bit"  CAM

BO_ 1425 RS_Obj_01_Part03: 8 RS
 SG_ RS_Obj01_ExstProb : 41|6@0+ (1,0) [0|63] "bit"  CAM
 SG_ RS_Obj01_YAccRel_Stdev : 47|6@0+ (0.2,0) [0|12.6] "m/s2"  CAM
 SG_ RS_Obj01_XAccRel_Stdev : 39|6@0+ (0.2,0) [0|12.6] "m/s2"  CAM
 SG_ RS_Obj01_YVelRel_Stdev : 31|6@0+ (0.2,0) [0|12.6] "m/s"  CAM
 SG_ RS_Obj01_XVelRel_Stdev : 23|6@0+ (0.2,0) [0|12.6] "m/s"  CAM
 SG_ RS_Obj01_YPos_Stdev : 15|6@0+ (0.2,0) [0|12.6] "m"  CAM
 SG_ RS_Obj01_XPos_Stdev : 7|6@0+ (0.2,0) [0|12.6] "m"  CAM
 SG_ RS_Obj01_Msg03_CheckSum : 63|8@0+ (1,0) [0|255] "bit"  CAM
 SG_ RS_Obj01_Msg03_AliveCounter : 51|4@0+ (1,0) [0|15] "bit"  CAM

BO_ 1424 RS_Obj_00_Part03: 8 RS
 SG_ RS_Obj00_ExstProb : 41|6@0+ (1,0) [0|63] "bit"  CAM
 SG_ RS_Obj00_YAccRel_Stdev : 47|6@0+ (0.2,0) [0|12.6] "m/s2"  CAM
 SG_ RS_Obj00_XAccRel_Stdev : 39|6@0+ (0.2,0) [0|12.6] "m/s2"  CAM
 SG_ RS_Obj00_YVelRel_Stdev : 31|6@0+ (0.2,0) [0|12.6] "m/s"  CAM
 SG_ RS_Obj00_XVelRel_Stdev : 23|6@0+ (0.2,0) [0|12.6] "m/s"  CAM
 SG_ RS_Obj00_YPos_Stdev : 15|6@0+ (0.2,0) [0|12.6] "m"  CAM
 SG_ RS_Obj00_XPos_Stdev : 7|6@0+ (0.2,0) [0|12.6] "m"  CAM
 SG_ RS_Obj00_Msg03_CheckSum : 63|8@0+ (1,0) [0|255] "bit"  CAM
 SG_ RS_Obj00_Msg03_AliveCounter : 51|4@0+ (1,0) [0|15] "bit"  CAM

BO_ 1937 DiagReq: 8 Vector__XXX
 SG_ DiagReq_Byte7 : 63|8@0+ (1,0) [0|255] ""  RS
 SG_ DiagReq_Byte6 : 55|8@0+ (1,0) [0|255] ""  RS
 SG_ DiagReq_Byte5 : 47|8@0+ (1,0) [0|255] ""  RS
 SG_ DiagReq_Byte4 : 39|8@0+ (1,0) [0|255] ""  RS
 SG_ DiagReq_Byte3 : 31|8@0+ (1,0) [0|255] ""  RS
 SG_ DiagReq_Byte2 : 23|8@0+ (1,0) [0|255] ""  RS
 SG_ DiagReq_Byte1 : 15|8@0+ (1,0) [0|255] ""  RS
 SG_ DiagReq_Byte0 : 7|8@0+ (1,0) [0|255] ""  RS

BO_ 1945 DiagResp: 8 RS
 SG_ DiagResp_Byte7 : 63|8@0+ (1,0) [0|255] "" Vector__XXX
 SG_ DiagResp_Byte6 : 55|8@0+ (1,0) [0|255] "" Vector__XXX
 SG_ DiagResp_Byte5 : 47|8@0+ (1,0) [0|255] "" Vector__XXX
 SG_ DiagResp_Byte4 : 39|8@0+ (1,0) [0|255] "" Vector__XXX
 SG_ DiagResp_Byte3 : 31|8@0+ (1,0) [0|255] "" Vector__XXX
 SG_ DiagResp_Byte2 : 23|8@0+ (1,0) [0|255] "" Vector__XXX
 SG_ DiagResp_Byte1 : 15|8@0+ (1,0) [0|255] "" Vector__XXX
 SG_ DiagResp_Byte0 : 7|8@0+ (1,0) [0|255] "" Vector__XXX

BO_ 1502 RS_Detn_14_Part01: 8 RS
 SG_ RS_Detn14_Magn : 47|10@0+ (0.1,0) [0|102.3] "dB"  CAM
 SG_ RS_Detn14_Msg01_CheckSum : 63|8@0+ (1,0) [0|255] "bit"  CAM
 SG_ RS_Detn14_Msg01_AliveCounter : 51|4@0+ (1,0) [0|15] "bit"  CAM
 SG_ RS_Detn14_PosY : 31|14@0+ (0.02441,-200) [-200|199.90903] "m"  CAM
 SG_ RS_Detn14_ID : 7|8@0+ (1,0) [0|255] "bit"  CAM
 SG_ RS_Detn14_PosX : 15|14@0+ (0.02441,-200) [-200|199.90903] "m"  CAM

BO_ 1516 RS_Detn_12_Part02: 8 RS
 SG_ RS_Detn12_Elev : 28|5@0+ (1,-15) [-15|15] "Deg"  CAM
 SG_ RS_Detn12_YVelRel : 39|11@0+ (0.1,-102.4) [-102.4|102.3] "m/s"  CAM
 SG_ RS_Detn12_XVelRel : 23|11@0+ (0.1,-102.4) [-102.4|102.3] "m/s"  CAM
 SG_ RS_Detn12_Msg02_AliveCounter : 51|4@0+ (1,0) [0|15] "bit"  CAM
 SG_ RS_Detn12_Msg02_CheckSum : 63|8@0+ (1,0) [0|255] "bit"  CAM
 SG_ RS_Detn12_Qly : 7|16@0+ (1,0) [0|65535] "bit"  CAM
 SG_ RS_Detn12_MotnSts : 55|2@0+ (1,0) [0|3] "bit"  CAM

BO_ 1499 RS_Detn_11_Part01: 8 RS
 SG_ RS_Detn11_Magn : 47|10@0+ (0.1,0) [0|102.3] "dB"  CAM
 SG_ RS_Detn11_Msg01_CheckSum : 63|8@0+ (1,0) [0|255] "bit"  CAM
 SG_ RS_Detn11_Msg01_AliveCounter : 51|4@0+ (1,0) [0|15] "bit"  CAM
 SG_ RS_Detn11_PosY : 31|14@0+ (0.02441,-200) [-200|199.90903] "m"  CAM
 SG_ RS_Detn11_ID : 7|8@0+ (1,0) [0|255] "bit"  CAM
 SG_ RS_Detn11_PosX : 15|14@0+ (0.02441,-200) [-200|199.90903] "m"  CAM

BO_ 1513 RS_Detn_09_Part02: 8 RS
 SG_ RS_Detn09_Elev : 28|5@0+ (1,-15) [-15|15] "Deg"  CAM
 SG_ RS_Detn09_YVelRel : 39|11@0+ (0.1,-102.4) [-102.4|102.3] "m/s"  CAM
 SG_ RS_Detn09_XVelRel : 23|11@0+ (0.1,-102.4) [-102.4|102.3] "m/s"  CAM
 SG_ RS_Detn09_Msg02_CheckSum : 63|8@0+ (1,0) [0|255] "bit"  CAM
 SG_ RS_Detn09_Msg02_AliveCounter : 51|4@0+ (1,0) [0|15] "bit"  CAM
 SG_ RS_Detn09_Qly : 7|16@0+ (1,0) [0|65535] "bit"  CAM
 SG_ RS_Detn09_MotnSts : 55|2@0+ (1,0) [0|3] "bit"  CAM

BO_ 1496 RS_Detn_08_Part01: 8 RS
 SG_ RS_Detn08_Magn : 47|10@0+ (0.1,0) [0|102.3] "dB"  CAM
 SG_ RS_Detn08_Msg01_CheckSum : 63|8@0+ (1,0) [0|255] "bit"  CAM
 SG_ RS_Detn08_Msg01_AliveCounter : 51|4@0+ (1,0) [0|15] "bit"  CAM
 SG_ RS_Detn08_PosY : 31|14@0+ (0.02441,-200) [-200|199.90903] "m"  CAM
 SG_ RS_Detn08_ID : 7|8@0+ (1,0) [0|255] "bit"  CAM
 SG_ RS_Detn08_PosX : 15|14@0+ (0.02441,-200) [-200|199.90903] "m"  CAM

BO_ 1510 RS_Detn_06_Part02: 8 RS
 SG_ RS_Detn06_Elev : 28|5@0+ (1,-15) [-15|15] "Deg"  CAM
 SG_ RS_Detn06_YVelRel : 39|11@0+ (0.1,-102.4) [-102.4|102.3] "m/s"  CAM
 SG_ RS_Detn06_XVelRel : 23|11@0+ (0.1,-102.4) [-102.4|102.3] "m/s"  CAM
 SG_ RS_Detn06_Msg02_CheckSum : 63|8@0+ (1,0) [0|255] "bit"  CAM
 SG_ RS_Detn06_Msg02_AliveCounter : 51|4@0+ (1,0) [0|15] "bit"  CAM
 SG_ RS_Detn06_Qly : 7|16@0+ (1,0) [0|65535] "bit"  CAM
 SG_ RS_Detn06_MotnSts : 55|2@0+ (1,0) [0|3] "bit"  CAM

BO_ 1493 RS_Detn_05_Part01: 8 RS
 SG_ RS_Detn05_Magn : 47|10@0+ (0.1,0) [0|102.3] "dB"  CAM
 SG_ RS_Detn05_Msg01_CheckSum : 63|8@0+ (1,0) [0|255] "bit"  CAM
 SG_ RS_Detn05_Msg01_AliveCounter : 51|4@0+ (1,0) [0|15] "bit"  CAM
 SG_ RS_Detn05_PosY : 31|14@0+ (0.02441,-200) [-200|199.90903] "m"  CAM
 SG_ RS_Detn05_ID : 7|8@0+ (1,0) [0|255] "bit"  CAM
 SG_ RS_Detn05_PosX : 15|14@0+ (0.02441,-200) [-200|199.90903] "m"  CAM

BO_ 1507 RS_Detn_03_Part02: 8 RS
 SG_ RS_Detn03_Elev : 28|5@0+ (1,-15) [-15|15] "Deg"  CAM
 SG_ RS_Detn03_YVelRel : 39|11@0+ (0.1,-102.4) [-102.4|102.3] "m/s"  CAM
 SG_ RS_Detn03_XVelRel : 23|11@0+ (0.1,-102.4) [-102.4|102.3] "m/s"  CAM
 SG_ RS_Detn03_Msg02_CheckSum : 63|8@0+ (1,0) [0|255] "bit"  CAM
 SG_ RS_Detn03_Msg02_AliveCounter : 51|4@0+ (1,0) [0|15] "bit"  CAM
 SG_ RS_Detn03_Qly : 7|16@0+ (1,0) [0|65535] "bit"  CAM
 SG_ RS_Detn03_MotnSts : 55|2@0+ (1,0) [0|3] "bit"  CAM

BO_ 1490 RS_Detn_02_Part01: 8 RS
 SG_ RS_Detn02_Magn : 47|10@0+ (0.1,0) [0|102.3] "dB"  CAM
 SG_ RS_Detn02_Msg01_CheckSum : 63|8@0+ (1,0) [0|255] "bit"  CAM
 SG_ RS_Detn02_Msg01_AliveCounter : 51|4@0+ (1,0) [0|15] "bit"  CAM
 SG_ RS_Detn02_PosY : 31|14@0+ (0.02441,-200) [-200|199.90903] "m"  CAM
 SG_ RS_Detn02_ID : 7|8@0+ (1,0) [0|255] "bit"  CAM
 SG_ RS_Detn02_PosX : 15|14@0+ (0.02441,-200) [-200|199.90903] "m"  CAM

BO_ 1504 RS_Detn_00_Part02: 8 RS
 SG_ RS_Detn00_Elev : 28|5@0+ (1,-15) [-15|15] "Deg"  CAM
 SG_ RS_Detn00_XVelRel : 23|11@0+ (0.1,-102.4) [-102.4|102.3] "m/s"  CAM
 SG_ RS_Detn00_YVelRel : 39|11@0+ (0.1,-102.4) [-102.4|102.3] "m/s"  CAM
 SG_ RS_Detn00_MotnSts : 55|2@0+ (1,0) [0|3] "bit"  CAM
 SG_ RS_Detn00_Msg02_CheckSum : 63|8@0+ (1,0) [0|255] "bit"  CAM
 SG_ RS_Detn00_Msg02_AliveCounter : 51|4@0+ (1,0) [0|15] "bit"  CAM
 SG_ RS_Detn00_Qly : 7|16@0+ (1,0) [0|65535] "bit"  CAM

BO_ 1389 RS_Obj_29_Part02: 8 RS
 SG_ RS_Obj29_CtrkInd : 16|1@0+ (1,0) [0|1] "bit"  CAM
 SG_ RS_Obj29_YVelAbsolute : 36|11@0+ (0.1,-102.4) [-102.4|102.3] "m/s"  CAM
 SG_ RS_Obj29_XVelAbsolute : 31|11@0+ (0.1,-102.4) [-102.4|102.3] "m/s"  CAM
 SG_ RS_Obj29_heading : 23|7@0- (0.049087,0.049087) [-3.092481|3.141568] "rad"  CAM
 SG_ RS_Obj29_Classconf : 41|6@0+ (1.5873,0) [0|100] "%"  CAM
 SG_ RS_Obj29_YAccAbsolute : 15|8@0+ (0.2,-25.6) [-25.6|25.4] "m/s2"  CAM
 SG_ RS_Obj29_XAccAbsolute : 7|8@0+ (0.2,-25.6) [-25.6|25.4] "m/s2"  CAM
 SG_ RS_Obj29_Msg02_CheckSum : 63|8@0+ (1,0) [0|255] "bit"  CAM
 SG_ RS_Obj29_Msg02_AliveCounter : 51|4@0+ (1,0) [0|15] "bit"  CAM

BO_ 1388 RS_Obj_28_Part02: 8 RS
 SG_ RS_Obj28_CtrkInd : 16|1@0+ (1,0) [0|1] "bit"  CAM
 SG_ RS_Obj28_YVelAbsolute : 36|11@0+ (0.1,-102.4) [-102.4|102.3] "m/s"  CAM
 SG_ RS_Obj28_XVelAbsolute : 31|11@0+ (0.1,-102.4) [-102.4|102.3] "m/s"  CAM
 SG_ RS_Obj28_heading : 23|7@0- (0.049087,0.049087) [-3.092481|3.141568] "rad"  CAM
 SG_ RS_Obj28_Classconf : 41|6@0+ (1.5873,0) [0|100] "%"  CAM
 SG_ RS_Obj28_YAccAbsolute : 15|8@0+ (0.2,-25.6) [-25.6|25.4] "m/s2"  CAM
 SG_ RS_Obj28_XAccAbsolute : 7|8@0+ (0.2,-25.6) [-25.6|25.4] "m/s2"  CAM
 SG_ RS_Obj28_Msg02_CheckSum : 63|8@0+ (1,0) [0|255] "bit"  CAM
 SG_ RS_Obj28_Msg02_AliveCounter : 51|4@0+ (1,0) [0|15] "bit"  CAM

BO_ 1387 RS_Obj_27_Part02: 8 RS
 SG_ RS_Obj27_CtrkInd : 16|1@0+ (1,0) [0|1] "bit"  CAM
 SG_ RS_Obj27_YVelAbsolute : 36|11@0+ (0.1,-102.4) [-102.4|102.3] "m/s"  CAM
 SG_ RS_Obj27_XVelAbsolute : 31|11@0+ (0.1,-102.4) [-102.4|102.3] "m/s"  CAM
 SG_ RS_Obj27_heading : 23|7@0- (0.049087,0.049087) [-3.092481|3.141568] "rad"  CAM
 SG_ RS_Obj27_Classconf : 41|6@0+ (1.5873,0) [0|100] "%"  CAM
 SG_ RS_Obj27_YAccAbsolute : 15|8@0+ (0.2,-25.6) [-25.6|25.4] "m/s2"  CAM
 SG_ RS_Obj27_XAccAbsolute : 7|8@0+ (0.2,-25.6) [-25.6|25.4] "m/s2"  CAM
 SG_ RS_Obj27_Msg02_CheckSum : 63|8@0+ (1,0) [0|255] "bit"  CAM
 SG_ RS_Obj27_Msg02_AliveCounter : 51|4@0+ (1,0) [0|15] "bit"  CAM

BO_ 1386 RS_Obj_26_Part02: 8 RS
 SG_ RS_Obj26_CtrkInd : 16|1@0+ (1,0) [0|1] "bit"  CAM
 SG_ RS_Obj26_YVelAbsolute : 36|11@0+ (0.1,-102.4) [-102.4|102.3] "m/s"  CAM
 SG_ RS_Obj26_XVelAbsolute : 31|11@0+ (0.1,-102.4) [-102.4|102.3] "m/s"  CAM
 SG_ RS_Obj26_heading : 23|7@0- (0.049087,0.049087) [-3.092481|3.141568] "rad"  CAM
 SG_ RS_Obj26_Classconf : 41|6@0+ (1.5873,0) [0|100] "%"  CAM
 SG_ RS_Obj26_YAccAbsolute : 15|8@0+ (0.2,-25.6) [-25.6|25.4] "m/s2"  CAM
 SG_ RS_Obj26_XAccAbsolute : 7|8@0+ (0.2,-25.6) [-25.6|25.4] "m/s2"  CAM
 SG_ RS_Obj26_Msg02_CheckSum : 63|8@0+ (1,0) [0|255] "bit"  CAM
 SG_ RS_Obj26_Msg02_AliveCounter : 51|4@0+ (1,0) [0|15] "bit"  CAM

BO_ 1385 RS_Obj_25_Part02: 8 RS
 SG_ RS_Obj25_CtrkInd : 16|1@0+ (1,0) [0|1] "bit"  CAM
 SG_ RS_Obj25_YVelAbsolute : 36|11@0+ (0.1,-102.4) [-102.4|102.3] "m/s"  CAM
 SG_ RS_Obj25_XVelAbsolute : 31|11@0+ (0.1,-102.4) [-102.4|102.3] "m/s"  CAM
 SG_ RS_Obj25_heading : 23|7@0- (0.049087,0.049087) [-3.092481|3.141568] "rad"  CAM
 SG_ RS_Obj25_Classconf : 41|6@0+ (1.5873,0) [0|100] "%"  CAM
 SG_ RS_Obj25_YAccAbsolute : 15|8@0+ (0.2,-25.6) [-25.6|25.4] "m/s2"  CAM
 SG_ RS_Obj25_XAccAbsolute : 7|8@0+ (0.2,-25.6) [-25.6|25.4] "m/s2"  CAM
 SG_ RS_Obj25_Msg02_CheckSum : 63|8@0+ (1,0) [0|255] "bit"  CAM
 SG_ RS_Obj25_Msg02_AliveCounter : 51|4@0+ (1,0) [0|15] "bit"  CAM

BO_ 1384 RS_Obj_24_Part02: 8 RS
 SG_ RS_Obj24_CtrkInd : 16|1@0+ (1,0) [0|1] "bit"  CAM
 SG_ RS_Obj24_YVelAbsolute : 36|11@0+ (0.1,-102.4) [-102.4|102.3] "m/s"  CAM
 SG_ RS_Obj24_XVelAbsolute : 31|11@0+ (0.1,-102.4) [-102.4|102.3] "m/s"  CAM
 SG_ RS_Obj24_heading : 23|7@0- (0.049087,0.049087) [-3.092481|3.141568] "rad"  CAM
 SG_ RS_Obj24_Classconf : 41|6@0+ (1.5873,0) [0|100] "%"  CAM
 SG_ RS_Obj24_YAccAbsolute : 15|8@0+ (0.2,-25.6) [-25.6|25.4] "m/s2"  CAM
 SG_ RS_Obj24_XAccAbsolute : 7|8@0+ (0.2,-25.6) [-25.6|25.4] "m/s2"  CAM
 SG_ RS_Obj24_Msg02_CheckSum : 63|8@0+ (1,0) [0|255] "bit"  CAM
 SG_ RS_Obj24_Msg02_AliveCounter : 51|4@0+ (1,0) [0|15] "bit"  CAM

BO_ 1383 RS_Obj_23_Part02: 8 RS
 SG_ RS_Obj23_CtrkInd : 16|1@0+ (1,0) [0|1] "bit"  CAM
 SG_ RS_Obj23_YVelAbsolute : 36|11@0+ (0.1,-102.4) [-102.4|102.3] "m/s"  CAM
 SG_ RS_Obj23_XVelAbsolute : 31|11@0+ (0.1,-102.4) [-102.4|102.3] "m/s"  CAM
 SG_ RS_Obj23_heading : 23|7@0- (0.049087,0.049087) [-3.092481|3.141568] "rad"  CAM
 SG_ RS_Obj23_Classconf : 41|6@0+ (1.5873,0) [0|100] "%"  CAM
 SG_ RS_Obj23_YAccAbsolute : 15|8@0+ (0.2,-25.6) [-25.6|25.4] "m/s2"  CAM
 SG_ RS_Obj23_XAccAbsolute : 7|8@0+ (0.2,-25.6) [-25.6|25.4] "m/s2"  CAM
 SG_ RS_Obj23_Msg02_CheckSum : 63|8@0+ (1,0) [0|255] "bit"  CAM
 SG_ RS_Obj23_Msg02_AliveCounter : 51|4@0+ (1,0) [0|15] "bit"  CAM

BO_ 1382 RS_Obj_22_Part02: 8 RS
 SG_ RS_Obj22_CtrkInd : 16|1@0+ (1,0) [0|1] "bit"  CAM
 SG_ RS_Obj22_YVelAbsolute : 36|11@0+ (0.1,-102.4) [-102.4|102.3] "m/s"  CAM
 SG_ RS_Obj22_XVelAbsolute : 31|11@0+ (0.1,-102.4) [-102.4|102.3] "m/s"  CAM
 SG_ RS_Obj22_heading : 23|7@0- (0.049087,0.049087) [-3.092481|3.141568] "rad"  CAM
 SG_ RS_Obj22_Classconf : 41|6@0+ (1.5873,0) [0|100] "%"  CAM
 SG_ RS_Obj22_YAccAbsolute : 15|8@0+ (0.2,-25.6) [-25.6|25.4] "m/s2"  CAM
 SG_ RS_Obj22_XAccAbsolute : 7|8@0+ (0.2,-25.6) [-25.6|25.4] "m/s2"  CAM
 SG_ RS_Obj22_Msg02_CheckSum : 63|8@0+ (1,0) [0|255] "bit"  CAM
 SG_ RS_Obj22_Msg02_AliveCounter : 51|4@0+ (1,0) [0|15] "bit"  CAM

BO_ 1381 RS_Obj_21_Part02: 8 RS
 SG_ RS_Obj21_CtrkInd : 16|1@0+ (1,0) [0|1] "bit"  CAM
 SG_ RS_Obj21_YVelAbsolute : 36|11@0+ (0.1,-102.4) [-102.4|102.3] "m/s"  CAM
 SG_ RS_Obj21_XVelAbsolute : 31|11@0+ (0.1,-102.4) [-102.4|102.3] "m/s"  CAM
 SG_ RS_Obj21_heading : 23|7@0- (0.049087,0.049087) [-3.092481|3.141568] "rad"  CAM
 SG_ RS_Obj21_Classconf : 41|6@0+ (1.5873,0) [0|100] "%"  CAM
 SG_ RS_Obj21_YAccAbsolute : 15|8@0+ (0.2,-25.6) [-25.6|25.4] "m/s2"  CAM
 SG_ RS_Obj21_XAccAbsolute : 7|8@0+ (0.2,-25.6) [-25.6|25.4] "m/s2"  CAM
 SG_ RS_Obj21_Msg02_CheckSum : 63|8@0+ (1,0) [0|255] "bit"  CAM
 SG_ RS_Obj21_Msg02_AliveCounter : 51|4@0+ (1,0) [0|15] "bit"  CAM

BO_ 1380 RS_Obj_20_Part02: 8 RS
 SG_ RS_Obj20_CtrkInd : 16|1@0+ (1,0) [0|1] "bit"  CAM
 SG_ RS_Obj20_YVelAbsolute : 36|11@0+ (0.1,-102.4) [-102.4|102.3] "m/s"  CAM
 SG_ RS_Obj20_XVelAbsolute : 31|11@0+ (0.1,-102.4) [-102.4|102.3] "m/s"  CAM
 SG_ RS_Obj20_heading : 23|7@0- (0.049087,0.049087) [-3.092481|3.141568] "rad"  CAM
 SG_ RS_Obj20_Classconf : 41|6@0+ (1.5873,0) [0|100] "%"  CAM
 SG_ RS_Obj20_YAccAbsolute : 15|8@0+ (0.2,-25.6) [-25.6|25.4] "m/s2"  CAM
 SG_ RS_Obj20_XAccAbsolute : 7|8@0+ (0.2,-25.6) [-25.6|25.4] "m/s2"  CAM
 SG_ RS_Obj20_Msg02_CheckSum : 63|8@0+ (1,0) [0|255] "bit"  CAM
 SG_ RS_Obj20_Msg02_AliveCounter : 51|4@0+ (1,0) [0|15] "bit"  CAM

BO_ 1379 RS_Obj_19_Part02: 8 RS
 SG_ RS_Obj19_CtrkInd : 16|1@0+ (1,0) [0|1] "bit"  CAM
 SG_ RS_Obj19_YVelAbsolute : 36|11@0+ (0.1,-102.4) [-102.4|102.3] "m/s"  CAM
 SG_ RS_Obj19_XVelAbsolute : 31|11@0+ (0.1,-102.4) [-102.4|102.3] "m/s"  CAM
 SG_ RS_Obj19_heading : 23|7@0- (0.049087,0.049087) [-3.092481|3.141568] "rad"  CAM
 SG_ RS_Obj19_Classconf : 41|6@0+ (1.5873,0) [0|100] "%"  CAM
 SG_ RS_Obj19_YAccAbsolute : 15|8@0+ (0.2,-25.6) [-25.6|25.4] "m/s2"  CAM
 SG_ RS_Obj19_XAccAbsolute : 7|8@0+ (0.2,-25.6) [-25.6|25.4] "m/s2"  CAM
 SG_ RS_Obj19_Msg02_CheckSum : 63|8@0+ (1,0) [0|255] "bit"  CAM
 SG_ RS_Obj19_Msg02_AliveCounter : 51|4@0+ (1,0) [0|15] "bit"  CAM

BO_ 1378 RS_Obj_18_Part02: 8 RS
 SG_ RS_Obj18_CtrkInd : 16|1@0+ (1,0) [0|1] "bit"  CAM
 SG_ RS_Obj18_YVelAbsolute : 36|11@0+ (0.1,-102.4) [-102.4|102.3] "m/s"  CAM
 SG_ RS_Obj18_XVelAbsolute : 31|11@0+ (0.1,-102.4) [-102.4|102.3] "m/s"  CAM
 SG_ RS_Obj18_heading : 23|7@0- (0.049087,0.049087) [-3.092481|3.141568] "rad"  CAM
 SG_ RS_Obj18_Classconf : 41|6@0+ (1.5873,0) [0|100] "%"  CAM
 SG_ RS_Obj18_YAccAbsolute : 15|8@0+ (0.2,-25.6) [-25.6|25.4] "m/s2"  CAM
 SG_ RS_Obj18_XAccAbsolute : 7|8@0+ (0.2,-25.6) [-25.6|25.4] "m/s2"  CAM
 SG_ RS_Obj18_Msg02_CheckSum : 63|8@0+ (1,0) [0|255] "bit"  CAM
 SG_ RS_Obj18_Msg02_AliveCounter : 51|4@0+ (1,0) [0|15] "bit"  CAM

BO_ 1377 RS_Obj_17_Part02: 8 RS
 SG_ RS_Obj17_CtrkInd : 16|1@0+ (1,0) [0|1] "bit"  CAM
 SG_ RS_Obj17_YVelAbsolute : 36|11@0+ (0.1,-102.4) [-102.4|102.3] "m/s"  CAM
 SG_ RS_Obj17_XVelAbsolute : 31|11@0+ (0.1,-102.4) [-102.4|102.3] "m/s"  CAM
 SG_ RS_Obj17_heading : 23|7@0- (0.049087,0.049087) [-3.092481|3.141568] "rad"  CAM
 SG_ RS_Obj17_Classconf : 41|6@0+ (1.5873,0) [0|100] "%"  CAM
 SG_ RS_Obj17_YAccAbsolute : 15|8@0+ (0.2,-25.6) [-25.6|25.4] "m/s2"  CAM
 SG_ RS_Obj17_XAccAbsolute : 7|8@0+ (0.2,-25.6) [-25.6|25.4] "m/s2"  CAM
 SG_ RS_Obj17_Msg02_CheckSum : 63|8@0+ (1,0) [0|255] "bit"  CAM
 SG_ RS_Obj17_Msg02_AliveCounter : 51|4@0+ (1,0) [0|15] "bit"  CAM

BO_ 1376 RS_Obj_16_Part02: 8 RS
 SG_ RS_Obj16_CtrkInd : 16|1@0+ (1,0) [0|1] "bit"  CAM
 SG_ RS_Obj16_YVelAbsolute : 36|11@0+ (0.1,-102.4) [-102.4|102.3] "m/s"  CAM
 SG_ RS_Obj16_XVelAbsolute : 31|11@0+ (0.1,-102.4) [-102.4|102.3] "m/s"  CAM
 SG_ RS_Obj16_heading : 23|7@0- (0.049087,0.049087) [-3.092481|3.141568] "rad"  CAM
 SG_ RS_Obj16_Classconf : 41|6@0+ (1.5873,0) [0|100] "%"  CAM
 SG_ RS_Obj16_YAccAbsolute : 15|8@0+ (0.2,-25.6) [-25.6|25.4] "m/s2"  CAM
 SG_ RS_Obj16_XAccAbsolute : 7|8@0+ (0.2,-25.6) [-25.6|25.4] "m/s2"  CAM
 SG_ RS_Obj16_Msg02_CheckSum : 63|8@0+ (1,0) [0|255] "bit"  CAM
 SG_ RS_Obj16_Msg02_AliveCounter : 51|4@0+ (1,0) [0|15] "bit"  CAM

BO_ 1375 RS_Obj_15_Part02: 8 RS
 SG_ RS_Obj15_CtrkInd : 16|1@0+ (1,0) [0|1] "bit"  CAM
 SG_ RS_Obj15_YVelAbsolute : 36|11@0+ (0.1,-102.4) [-102.4|102.3] "m/s"  CAM
 SG_ RS_Obj15_XVelAbsolute : 31|11@0+ (0.1,-102.4) [-102.4|102.3] "m/s"  CAM
 SG_ RS_Obj15_heading : 23|7@0- (0.049087,0.049087) [-3.092481|3.141568] "rad"  CAM
 SG_ RS_Obj15_Classconf : 41|6@0+ (1.5873,0) [0|100] "%"  CAM
 SG_ RS_Obj15_YAccAbsolute : 15|8@0+ (0.2,-25.6) [-25.6|25.4] "m/s2"  CAM
 SG_ RS_Obj15_XAccAbsolute : 7|8@0+ (0.2,-25.6) [-25.6|25.4] "m/s2"  CAM
 SG_ RS_Obj15_Msg02_CheckSum : 63|8@0+ (1,0) [0|255] "bit"  CAM
 SG_ RS_Obj15_Msg02_AliveCounter : 51|4@0+ (1,0) [0|15] "bit"  CAM

BO_ 1374 RS_Obj_14_Part02: 8 RS
 SG_ RS_Obj14_CtrkInd : 16|1@0+ (1,0) [0|1] "bit"  CAM
 SG_ RS_Obj14_YVelAbsolute : 36|11@0+ (0.1,-102.4) [-102.4|102.3] "m/s"  CAM
 SG_ RS_Obj14_XVelAbsolute : 31|11@0+ (0.1,-102.4) [-102.4|102.3] "m/s"  CAM
 SG_ RS_Obj14_heading : 23|7@0- (0.049087,0.049087) [-3.092481|3.141568] "rad"  CAM
 SG_ RS_Obj14_Classconf : 41|6@0+ (1.5873,0) [0|100] "%"  CAM
 SG_ RS_Obj14_YAccAbsolute : 15|8@0+ (0.2,-25.6) [-25.6|25.4] "m/s2"  CAM
 SG_ RS_Obj14_XAccAbsolute : 7|8@0+ (0.2,-25.6) [-25.6|25.4] "m/s2"  CAM
 SG_ RS_Obj14_Msg02_CheckSum : 63|8@0+ (1,0) [0|255] "bit"  CAM
 SG_ RS_Obj14_Msg02_AliveCounter : 51|4@0+ (1,0) [0|15] "bit"  CAM

BO_ 1373 RS_Obj_13_Part02: 8 RS
 SG_ RS_Obj13_CtrkInd : 16|1@0+ (1,0) [0|1] "bit"  CAM
 SG_ RS_Obj13_YVelAbsolute : 36|11@0+ (0.1,-102.4) [-102.4|102.3] "m/s"  CAM
 SG_ RS_Obj13_XVelAbsolute : 31|11@0+ (0.1,-102.4) [-102.4|102.3] "m/s"  CAM
 SG_ RS_Obj13_heading : 23|7@0- (0.049087,0.049087) [-3.092481|3.141568] "rad"  CAM
 SG_ RS_Obj13_Classconf : 41|6@0+ (1.5873,0) [0|100] "%"  CAM
 SG_ RS_Obj13_YAccAbsolute : 15|8@0+ (0.2,-25.6) [-25.6|25.4] "m/s2"  CAM
 SG_ RS_Obj13_XAccAbsolute : 7|8@0+ (0.2,-25.6) [-25.6|25.4] "m/s2"  CAM
 SG_ RS_Obj13_Msg02_CheckSum : 63|8@0+ (1,0) [0|255] "bit"  CAM
 SG_ RS_Obj13_Msg02_AliveCounter : 51|4@0+ (1,0) [0|15] "bit"  CAM

BO_ 1372 RS_Obj_12_Part02: 8 RS
 SG_ RS_Obj12_CtrkInd : 16|1@0+ (1,0) [0|1] "bit"  CAM
 SG_ RS_Obj12_YVelAbsolute : 36|11@0+ (0.1,-102.4) [-102.4|102.3] "m/s"  CAM
 SG_ RS_Obj12_XVelAbsolute : 31|11@0+ (0.1,-102.4) [-102.4|102.3] "m/s"  CAM
 SG_ RS_Obj12_heading : 23|7@0- (0.049087,0.049087) [-3.092481|3.141568] "rad"  CAM
 SG_ RS_Obj12_Classconf : 41|6@0+ (1.5873,0) [0|100] "%"  CAM
 SG_ RS_Obj12_YAccAbsolute : 15|8@0+ (0.2,-25.6) [-25.6|25.4] "m/s2"  CAM
 SG_ RS_Obj12_XAccAbsolute : 7|8@0+ (0.2,-25.6) [-25.6|25.4] "m/s2"  CAM
 SG_ RS_Obj12_Msg02_CheckSum : 63|8@0+ (1,0) [0|255] "bit"  CAM
 SG_ RS_Obj12_Msg02_AliveCounter : 51|4@0+ (1,0) [0|15] "bit"  CAM

BO_ 1371 RS_Obj_11_Part02: 8 RS
 SG_ RS_Obj11_CtrkInd : 16|1@0+ (1,0) [0|1] "bit"  CAM
 SG_ RS_Obj11_YVelAbsolute : 36|11@0+ (0.1,-102.4) [-102.4|102.3] "m/s"  CAM
 SG_ RS_Obj11_XVelAbsolute : 31|11@0+ (0.1,-102.4) [-102.4|102.3] "m/s"  CAM
 SG_ RS_Obj11_heading : 23|7@0- (0.049087,0.049087) [-3.092481|3.141568] "rad"  CAM
 SG_ RS_Obj11_Classconf : 41|6@0+ (1.5873,0) [0|100] "%"  CAM
 SG_ RS_Obj11_YAccAbsolute : 15|8@0+ (0.2,-25.6) [-25.6|25.4] "m/s2"  CAM
 SG_ RS_Obj11_XAccAbsolute : 7|8@0+ (0.2,-25.6) [-25.6|25.4] "m/s2"  CAM
 SG_ RS_Obj11_Msg02_CheckSum : 63|8@0+ (1,0) [0|255] "bit"  CAM
 SG_ RS_Obj11_Msg02_AliveCounter : 51|4@0+ (1,0) [0|15] "bit"  CAM

BO_ 1370 RS_Obj_10_Part02: 8 RS
 SG_ RS_Obj10_CtrkInd : 16|1@0+ (1,0) [0|1] "bit"  CAM
 SG_ RS_Obj10_YVelAbsolute : 36|11@0+ (0.1,-102.4) [-102.4|102.3] "m/s"  CAM
 SG_ RS_Obj10_XVelAbsolute : 31|11@0+ (0.1,-102.4) [-102.4|102.3] "m/s"  CAM
 SG_ RS_Obj10_heading : 23|7@0- (0.049087,0.049087) [-3.092481|3.141568] "rad"  CAM
 SG_ RS_Obj10_Classconf : 41|6@0+ (1.5873,0) [0|100] "%"  CAM
 SG_ RS_Obj10_YAccAbsolute : 15|8@0+ (0.2,-25.6) [-25.6|25.4] "m/s2"  CAM
 SG_ RS_Obj10_XAccAbsolute : 7|8@0+ (0.2,-25.6) [-25.6|25.4] "m/s2"  CAM
 SG_ RS_Obj10_Msg02_CheckSum : 63|8@0+ (1,0) [0|255] "bit"  CAM
 SG_ RS_Obj10_Msg02_AliveCounter : 51|4@0+ (1,0) [0|15] "bit"  CAM

BO_ 1369 RS_Obj_09_Part02: 8 RS
 SG_ RS_Obj09_CtrkInd : 16|1@0+ (1,0) [0|1] "bit"  CAM
 SG_ RS_Obj09_YVelAbsolute : 36|11@0+ (0.1,-102.4) [-102.4|102.3] "m/s"  CAM
 SG_ RS_Obj09_XVelAbsolute : 31|11@0+ (0.1,-102.4) [-102.4|102.3] "m/s"  CAM
 SG_ RS_Obj09_heading : 23|7@0- (0.049087,0.049087) [-3.092481|3.141568] "rad"  CAM
 SG_ RS_Obj09_Classconf : 41|6@0+ (1.5873,0) [0|100] "%"  CAM
 SG_ RS_Obj09_YAccAbsolute : 15|8@0+ (0.2,-25.6) [-25.6|25.4] "m/s2"  CAM
 SG_ RS_Obj09_XAccAbsolute : 7|8@0+ (0.2,-25.6) [-25.6|25.4] "m/s2"  CAM
 SG_ RS_Obj09_Msg02_CheckSum : 63|8@0+ (1,0) [0|255] "bit"  CAM
 SG_ RS_Obj09_Msg02_AliveCounter : 51|4@0+ (1,0) [0|15] "bit"  CAM

BO_ 1368 RS_Obj_08_Part02: 8 RS
 SG_ RS_Obj08_CtrkInd : 16|1@0+ (1,0) [0|1] "bit"  CAM
 SG_ RS_Obj08_YVelAbsolute : 36|11@0+ (0.1,-102.4) [-102.4|102.3] "m/s"  CAM
 SG_ RS_Obj08_XVelAbsolute : 31|11@0+ (0.1,-102.4) [-102.4|102.3] "m/s"  CAM
 SG_ RS_Obj08_heading : 23|7@0- (0.049087,0.049087) [-3.092481|3.141568] "rad"  CAM
 SG_ RS_Obj08_Classconf : 41|6@0+ (1.5873,0) [0|100] "%"  CAM
 SG_ RS_Obj08_YAccAbsolute : 15|8@0+ (0.2,-25.6) [-25.6|25.4] "m/s2"  CAM
 SG_ RS_Obj08_XAccAbsolute : 7|8@0+ (0.2,-25.6) [-25.6|25.4] "m/s2"  CAM
 SG_ RS_Obj08_Msg02_CheckSum : 63|8@0+ (1,0) [0|255] "bit"  CAM
 SG_ RS_Obj08_Msg02_AliveCounter : 51|4@0+ (1,0) [0|15] "bit"  CAM

BO_ 1367 RS_Obj_07_Part02: 8 RS
 SG_ RS_Obj07_CtrkInd : 16|1@0+ (1,0) [0|1] "bit"  CAM
 SG_ RS_Obj07_YVelAbsolute : 36|11@0+ (0.1,-102.4) [-102.4|102.3] "m/s"  CAM
 SG_ RS_Obj07_XVelAbsolute : 31|11@0+ (0.1,-102.4) [-102.4|102.3] "m/s"  CAM
 SG_ RS_Obj07_heading : 23|7@0- (0.049087,0.049087) [-3.092481|3.141568] "rad"  CAM
 SG_ RS_Obj07_Classconf : 41|6@0+ (1.5873,0) [0|100] "%"  CAM
 SG_ RS_Obj07_YAccAbsolute : 15|8@0+ (0.2,-25.6) [-25.6|25.4] "m/s2"  CAM
 SG_ RS_Obj07_XAccAbsolute : 7|8@0+ (0.2,-25.6) [-25.6|25.4] "m/s2"  CAM
 SG_ RS_Obj07_Msg02_CheckSum : 63|8@0+ (1,0) [0|255] "bit"  CAM
 SG_ RS_Obj07_Msg02_AliveCounter : 51|4@0+ (1,0) [0|15] "bit"  CAM

BO_ 1366 RS_Obj_06_Part02: 8 RS
 SG_ RS_Obj06_CtrkInd : 16|1@0+ (1,0) [0|1] "bit"  CAM
 SG_ RS_Obj06_YVelAbsolute : 36|11@0+ (0.1,-102.4) [-102.4|102.3] "m/s"  CAM
 SG_ RS_Obj06_XVelAbsolute : 31|11@0+ (0.1,-102.4) [-102.4|102.3] "m/s"  CAM
 SG_ RS_Obj06_heading : 23|7@0- (0.049087,0.049087) [-3.092481|3.141568] "rad"  CAM
 SG_ RS_Obj06_Classconf : 41|6@0+ (1.5873,0) [0|100] "%"  CAM
 SG_ RS_Obj06_YAccAbsolute : 15|8@0+ (0.2,-25.6) [-25.6|25.4] "m/s2"  CAM
 SG_ RS_Obj06_XAccAbsolute : 7|8@0+ (0.2,-25.6) [-25.6|25.4] "m/s2"  CAM
 SG_ RS_Obj06_Msg02_CheckSum : 63|8@0+ (1,0) [0|255] "bit"  CAM
 SG_ RS_Obj06_Msg02_AliveCounter : 51|4@0+ (1,0) [0|15] "bit"  CAM

BO_ 1365 RS_Obj_05_Part02: 8 RS
 SG_ RS_Obj05_CtrkInd : 16|1@0+ (1,0) [0|1] "bit"  CAM
 SG_ RS_Obj05_YVelAbsolute : 36|11@0+ (0.1,-102.4) [-102.4|102.3] "m/s"  CAM
 SG_ RS_Obj05_XVelAbsolute : 31|11@0+ (0.1,-102.4) [-102.4|102.3] "m/s"  CAM
 SG_ RS_Obj05_heading : 23|7@0- (0.049087,0.049087) [-3.092481|3.141568] "rad"  CAM
 SG_ RS_Obj05_Classconf : 41|6@0+ (1.5873,0) [0|100] "%"  CAM
 SG_ RS_Obj05_YAccAbsolute : 15|8@0+ (0.2,-25.6) [-25.6|25.4] "m/s2"  CAM
 SG_ RS_Obj05_XAccAbsolute : 7|8@0+ (0.2,-25.6) [-25.6|25.4] "m/s2"  CAM
 SG_ RS_Obj05_Msg02_CheckSum : 63|8@0+ (1,0) [0|255] "bit"  CAM
 SG_ RS_Obj05_Msg02_AliveCounter : 51|4@0+ (1,0) [0|15] "bit"  CAM

BO_ 1364 RS_Obj_04_Part02: 8 RS
 SG_ RS_Obj04_CtrkInd : 16|1@0+ (1,0) [0|1] "bit"  CAM
 SG_ RS_Obj04_YVelAbsolute : 36|11@0+ (0.1,-102.4) [-102.4|102.3] "m/s"  CAM
 SG_ RS_Obj04_XVelAbsolute : 31|11@0+ (0.1,-102.4) [-102.4|102.3] "m/s"  CAM
 SG_ RS_Obj04_heading : 23|7@0- (0.049087,0.049087) [-3.092481|3.141568] "rad"  CAM
 SG_ RS_Obj04_Classconf : 41|6@0+ (1.5873,0) [0|100] "%"  CAM
 SG_ RS_Obj04_YAccAbsolute : 15|8@0+ (0.2,-25.6) [-25.6|25.4] "m/s2"  CAM
 SG_ RS_Obj04_XAccAbsolute : 7|8@0+ (0.2,-25.6) [-25.6|25.4] "m/s2"  CAM
 SG_ RS_Obj04_Msg02_CheckSum : 63|8@0+ (1,0) [0|255] "bit"  CAM
 SG_ RS_Obj04_Msg02_AliveCounter : 51|4@0+ (1,0) [0|15] "bit"  CAM

BO_ 1363 RS_Obj_03_Part02: 8 RS
 SG_ RS_Obj03_CtrkInd : 16|1@0+ (1,0) [0|1] "bit"  CAM
 SG_ RS_Obj03_YVelAbsolute : 36|11@0+ (0.1,-102.4) [-102.4|102.3] "m/s"  CAM
 SG_ RS_Obj03_XVelAbsolute : 31|11@0+ (0.1,-102.4) [-102.4|102.3] "m/s"  CAM
 SG_ RS_Obj03_heading : 23|7@0- (0.049087,0.049087) [-3.092481|3.141568] "rad"  CAM
 SG_ RS_Obj03_Classconf : 41|6@0+ (1.5873,0) [0|100] "%"  CAM
 SG_ RS_Obj03_YAccAbsolute : 15|8@0+ (0.2,-25.6) [-25.6|25.4] "m/s2"  CAM
 SG_ RS_Obj03_XAccAbsolute : 7|8@0+ (0.2,-25.6) [-25.6|25.4] "m/s2"  CAM
 SG_ RS_Obj03_Msg02_CheckSum : 63|8@0+ (1,0) [0|255] "bit"  CAM
 SG_ RS_Obj03_Msg02_AliveCounter : 51|4@0+ (1,0) [0|15] "bit"  CAM

BO_ 1362 RS_Obj_02_Part02: 8 RS
 SG_ RS_Obj02_CtrkInd : 16|1@0+ (1,0) [0|1] "bit"  CAM
 SG_ RS_Obj02_YVelAbsolute : 36|11@0+ (0.1,-102.4) [-102.4|102.3] "m/s"  CAM
 SG_ RS_Obj02_XVelAbsolute : 31|11@0+ (0.1,-102.4) [-102.4|102.3] "m/s"  CAM
 SG_ RS_Obj02_heading : 23|7@0- (0.049087,0.049087) [-3.092481|3.141568] "rad"  CAM
 SG_ RS_Obj02_Classconf : 41|6@0+ (1.5873,0) [0|100] "%"  CAM
 SG_ RS_Obj02_YAccAbsolute : 15|8@0+ (0.2,-25.6) [-25.6|25.4] "m/s2"  CAM
 SG_ RS_Obj02_XAccAbsolute : 7|8@0+ (0.2,-25.6) [-25.6|25.4] "m/s2"  CAM
 SG_ RS_Obj02_Msg02_CheckSum : 63|8@0+ (1,0) [0|255] "bit"  CAM
 SG_ RS_Obj02_Msg02_AliveCounter : 51|4@0+ (1,0) [0|15] "bit"  CAM

BO_ 1361 RS_Obj_01_Part02: 8 RS
 SG_ RS_Obj01_CtrkInd : 16|1@0+ (1,0) [0|1] "bit"  CAM
 SG_ RS_Obj01_YVelAbsolute : 36|11@0+ (0.1,-102.4) [-102.4|102.3] "m/s"  CAM
 SG_ RS_Obj01_XVelAbsolute : 31|11@0+ (0.1,-102.4) [-102.4|102.3] "m/s"  CAM
 SG_ RS_Obj01_heading : 23|7@0- (0.049087,0.049087) [-3.092481|3.141568] "rad"  CAM
 SG_ RS_Obj01_Classconf : 41|6@0+ (1.5873,0) [0|100] "%"  CAM
 SG_ RS_Obj01_YAccAbsolute : 15|8@0+ (0.2,-25.6) [-25.6|25.4] "m/s2"  CAM
 SG_ RS_Obj01_XAccAbsolute : 7|8@0+ (0.2,-25.6) [-25.6|25.4] "m/s2"  CAM
 SG_ RS_Obj01_Msg02_CheckSum : 63|8@0+ (1,0) [0|255] "bit"  CAM
 SG_ RS_Obj01_Msg02_AliveCounter : 51|4@0+ (1,0) [0|15] "bit"  CAM

BO_ 1517 RS_Detn_13_Part02: 8 RS
 SG_ RS_Detn13_Elev : 28|5@0+ (1,-15) [-15|15] "Deg"  CAM
 SG_ RS_Detn13_YVelRel : 39|11@0+ (0.1,-102.4) [-102.4|102.3] "m/s"  CAM
 SG_ RS_Detn13_XVelRel : 23|11@0+ (0.1,-102.4) [-102.4|102.3] "m/s"  CAM
 SG_ RS_Detn13_Msg02_CheckSum : 63|8@0+ (1,0) [0|255] "bit"  CAM
 SG_ RS_Detn13_Msg02_AliveCounter : 51|4@0+ (1,0) [0|15] "bit"  CAM
 SG_ RS_Detn13_Qly : 7|16@0+ (1,0) [0|65535] "bit"  CAM
 SG_ RS_Detn13_MotnSts : 55|2@0+ (1,0) [0|3] "bit"  CAM

BO_ 1500 RS_Detn_12_Part01: 8 RS
 SG_ RS_Detn12_Magn : 47|10@0+ (0.1,0) [0|102.3] "dB"  CAM
 SG_ RS_Detn12_Msg01_CheckSum : 63|8@0+ (1,0) [0|255] "bit"  CAM
 SG_ RS_Detn12_Msg01_AliveCounter : 51|4@0+ (1,0) [0|15] "bit"  CAM
 SG_ RS_Detn12_PosY : 31|14@0+ (0.02441,-200) [-200|199.90903] "m"  CAM
 SG_ RS_Detn12_ID : 7|8@0+ (1,0) [0|255] "bit"  CAM
 SG_ RS_Detn12_PosX : 15|14@0+ (0.02441,-200) [-200|199.90903] "m"  CAM

BO_ 1514 RS_Detn_10_Part02: 8 RS
 SG_ RS_Detn10_Elev : 28|5@0+ (1,-15) [-15|15] "Deg"  CAM
 SG_ RS_Detn10_YVelRel : 39|11@0+ (0.1,-102.4) [-102.4|102.3] "m/s"  CAM
 SG_ RS_Detn10_XVelRel : 23|11@0+ (0.1,-102.4) [-102.4|102.3] "m/s"  CAM
 SG_ RS_Detn10_Msg02_CheckSum : 63|8@0+ (1,0) [0|255] "bit"  CAM
 SG_ RS_Detn10_Msg02_AliveCounter : 51|4@0+ (1,0) [0|15] "bit"  CAM
 SG_ RS_Detn10_Qly : 7|16@0+ (1,0) [0|65535] "bit"  CAM
 SG_ RS_Detn10_MotnSts : 55|2@0+ (1,0) [0|3] "bit"  CAM

BO_ 1497 RS_Detn_09_Part01: 8 RS
 SG_ RS_Detn09_Magn : 47|10@0+ (0.1,0) [0|102.3] "dB"  CAM
 SG_ RS_Detn09_Msg01_CheckSum : 63|8@0+ (1,0) [0|255] "bit"  CAM
 SG_ RS_Detn09_Msg01_AliveCounter : 51|4@0+ (1,0) [0|15] "bit"  CAM
 SG_ RS_Detn09_PosY : 31|14@0+ (0.02441,-200) [-200|199.90903] "m"  CAM
 SG_ RS_Detn09_ID : 7|8@0+ (1,0) [0|255] "bit"  CAM
 SG_ RS_Detn09_PosX : 15|14@0+ (0.02441,-200) [-200|199.90903] "m"  CAM

BO_ 1511 RS_Detn_07_Part02: 8 RS
 SG_ RS_Detn07_Elev : 28|5@0+ (1,-15) [-15|15] "Deg"  CAM
 SG_ RS_Detn07_YVelRel : 39|11@0+ (0.1,-102.4) [-102.4|102.3] "m/s"  CAM
 SG_ RS_Detn07_XVelRel : 23|11@0+ (0.1,-102.4) [-102.4|102.3] "m/s"  CAM
 SG_ RS_Detn07_Msg02_CheckSum : 63|8@0+ (1,0) [0|255] "bit"  CAM
 SG_ RS_Detn07_Msg02_AliveCounter : 51|4@0+ (1,0) [0|15] "bit"  CAM
 SG_ RS_Detn07_Qly : 7|16@0+ (1,0) [0|65535] "bit"  CAM
 SG_ RS_Detn07_MotnSts : 55|2@0+ (1,0) [0|3] "bit"  CAM

BO_ 1494 RS_Detn_06_Part01: 8 RS
 SG_ RS_Detn06_Magn : 47|10@0+ (0.1,0) [0|102.3] "dB"  CAM
 SG_ RS_Detn06_Msg01_CheckSum : 63|8@0+ (1,0) [0|255] "bit"  CAM
 SG_ RS_Detn06_Msg01_AliveCounter : 51|4@0+ (1,0) [0|15] "bit"  CAM
 SG_ RS_Detn06_PosY : 31|14@0+ (0.02441,-200) [-200|199.90903] "m"  CAM
 SG_ RS_Detn06_ID : 7|8@0+ (1,0) [0|255] "bit"  CAM
 SG_ RS_Detn06_PosX : 15|14@0+ (0.02441,-200) [-200|199.90903] "m"  CAM

BO_ 1508 RS_Detn_04_Part02: 8 RS
 SG_ RS_Detn04_Elev : 28|5@0+ (1,-15) [-15|15] "Deg"  CAM
 SG_ RS_Detn04_YVelRel : 39|11@0+ (0.1,-102.4) [-102.4|102.3] "m/s"  CAM
 SG_ RS_Detn04_XVelRel : 23|11@0+ (0.1,-102.4) [-102.4|102.3] "m/s"  CAM
 SG_ RS_Detn04_Msg02_CheckSum : 63|8@0+ (1,0) [0|255] "bit"  CAM
 SG_ RS_Detn04_Msg02_AliveCounter : 51|4@0+ (1,0) [0|15] "bit"  CAM
 SG_ RS_Detn04_Qly : 7|16@0+ (1,0) [0|65535] "bit"  CAM
 SG_ RS_Detn04_MotnSts : 55|2@0+ (1,0) [0|3] "bit"  CAM

BO_ 1491 RS_Detn_03_Part01: 8 RS
 SG_ RS_Detn03_Magn : 47|10@0+ (0.1,0) [0|102.3] "dB"  CAM
 SG_ RS_Detn03_Msg01_CheckSum : 63|8@0+ (1,0) [0|255] "bit"  CAM
 SG_ RS_Detn03_Msg01_AliveCounter : 51|4@0+ (1,0) [0|15] "bit"  CAM
 SG_ RS_Detn03_PosY : 31|14@0+ (0.02441,-200) [-200|199.90903] "m"  CAM
 SG_ RS_Detn03_ID : 7|8@0+ (1,0) [0|255] "bit"  CAM
 SG_ RS_Detn03_PosX : 15|14@0+ (0.02441,-200) [-200|199.90903] "m"  CAM

BO_ 1505 RS_Detn_01_Part02: 8 RS
 SG_ RS_Detn01_Elev : 28|5@0+ (1,-15) [-15|15] "Deg"  CAM
 SG_ RS_Detn01_YVelRel : 39|11@0+ (0.1,-102.4) [-102.4|102.3] "m/s"  CAM
 SG_ RS_Detn01_XVelRel : 23|11@0+ (0.1,-102.4) [-102.4|102.3] "m/s"  CAM
 SG_ RS_Detn01_Msg02_CheckSum : 63|8@0+ (1,0) [0|255] "bit"  CAM
 SG_ RS_Detn01_Msg02_AliveCounter : 51|4@0+ (1,0) [0|15] "bit"  CAM
 SG_ RS_Detn01_Qly : 7|16@0+ (1,0) [0|65535] "bit"  CAM
 SG_ RS_Detn01_MotnSts : 55|2@0+ (1,0) [0|3] "bit"  CAM

BO_ 1488 RS_Detn_00_Part01: 8 RS
 SG_ RS_Detn00_Magn : 47|10@0+ (0.1,0) [0|102.3] "dB"  CAM
 SG_ RS_Detn00_Msg01_CheckSum : 63|8@0+ (1,0) [0|255] "bit"  CAM
 SG_ RS_Detn00_Msg01_AliveCounter : 51|4@0+ (1,0) [0|15] "bit"  CAM
 SG_ RS_Detn00_PosY : 31|14@0+ (0.02441,-200) [-200|199.90903] "m"  CAM
 SG_ RS_Detn00_ID : 7|8@0+ (1,0) [0|255] "bit"  CAM
 SG_ RS_Detn00_PosX : 15|14@0+ (0.02441,-200) [-200|199.90903] "m"  CAM

BO_ 1341 RS_Obj_29_Part01: 8 RS
 SG_ RS_Obj29_MeasFlag : 48|1@0+ (1,0) [0|1] "bit"  CAM
 SG_ RS_Obj29_Type : 51|2@0+ (1,0) [0|3] "bit"  CAM
 SG_ RS_Obj29_YPos : 39|14@0+ (0.02441,-200) [-200|199.90903] "m"  CAM
 SG_ RS_Obj29_XPos : 23|14@0+ (0.02441,-200) [-200|199.90903] "m"  CAM
 SG_ RS_Obj29_ElevConf : 41|2@0+ (1,0) [0|3] "bit"  CAM
 SG_ RS_Obj29_ElevClass : 25|2@0+ (1,0) [0|3] "bit"  CAM
 SG_ RS_Obj29_Msg01_AliveCounter : 55|4@0+ (1,0) [0|15] "bit"  CAM
 SG_ RS_Obj29_Msg01_CheckSum : 63|8@0+ (1,0) [0|255] "bit"  CAM
 SG_ RS_Obj29_MotionPattern : 10|3@0+ (1,0) [0|7] "bit"  CAM
 SG_ RS_Obj29_ValidFlag : 49|1@0+ (1,0) [0|1] "bit"  CAM
 SG_ RS_Obj29_ID : 7|13@0+ (1,0) [0|8191] "bit"  CAM

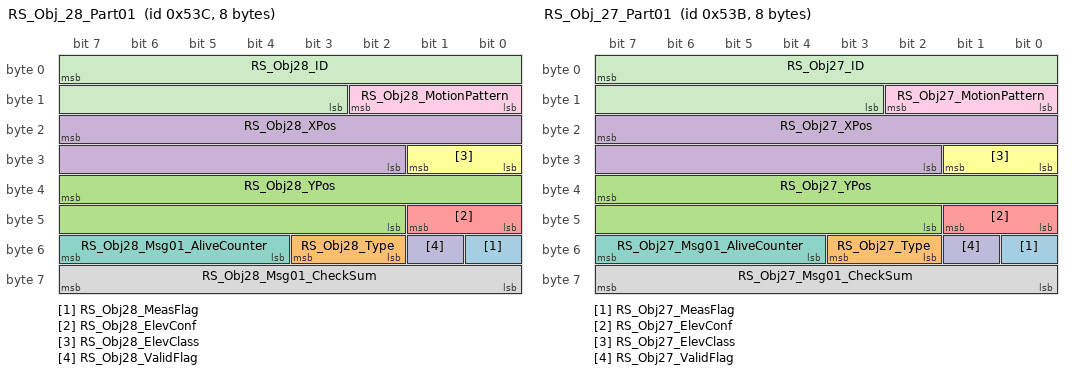
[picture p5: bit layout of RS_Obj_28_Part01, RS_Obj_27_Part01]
BO_ 1340 RS_Obj_28_Part01: 8 RS
 SG_ RS_Obj28_MeasFlag : 48|1@0+ (1,0) [0|1] "bit"  CAM
 SG_ RS_Obj28_Type : 51|2@0+ (1,0) [0|3] "bit"  CAM
 SG_ RS_Obj28_YPos : 39|14@0+ (0.02441,-200) [-200|199.90903] "m"  CAM
 SG_ RS_Obj28_XPos : 23|14@0+ (0.02441,-200) [-200|199.90903] "m"  CAM
 SG_ RS_Obj28_ElevConf : 41|2@0+ (1,0) [0|3] "bit"  CAM
 SG_ RS_Obj28_ElevClass : 25|2@0+ (1,0) [0|3] "bit"  CAM
 SG_ RS_Obj28_Msg01_AliveCounter : 55|4@0+ (1,0) [0|15] "bit"  CAM
 SG_ RS_Obj28_Msg01_CheckSum : 63|8@0+ (1,0) [0|255] "bit"  CAM
 SG_ RS_Obj28_MotionPattern : 10|3@0+ (1,0) [0|7] "bit"  CAM
 SG_ RS_Obj28_ValidFlag : 49|1@0+ (1,0) [0|1] "bit"  CAM
 SG_ RS_Obj28_ID : 7|13@0+ (1,0) [0|8191] "bit"  CAM

BO_ 1339 RS_Obj_27_Part01: 8 RS
 SG_ RS_Obj27_MeasFlag : 48|1@0+ (1,0) [0|1] "bit"  CAM
 SG_ RS_Obj27_Type : 51|2@0+ (1,0) [0|3] "bit"  CAM
 SG_ RS_Obj27_YPos : 39|14@0+ (0.02441,-200) [-200|199.90903] "m"  CAM
 SG_ RS_Obj27_XPos : 23|14@0+ (0.02441,-200) [-200|199.90903] "m"  CAM
 SG_ RS_Obj27_ElevConf : 41|2@0+ (1,0) [0|3] "bit"  CAM
 SG_ RS_Obj27_ElevClass : 25|2@0+ (1,0) [0|3] "bit"  CAM
 SG_ RS_Obj27_Msg01_AliveCounter : 55|4@0+ (1,0) [0|15] "bit"  CAM
 SG_ RS_Obj27_Msg01_CheckSum : 63|8@0+ (1,0) [0|255] "bit"  CAM
 SG_ RS_Obj27_MotionPattern : 10|3@0+ (1,0) [0|7] "bit"  CAM
 SG_ RS_Obj27_ValidFlag : 49|1@0+ (1,0) [0|1] "bit"  CAM
 SG_ RS_Obj27_ID : 7|13@0+ (1,0) [0|8191] "bit"  CAM

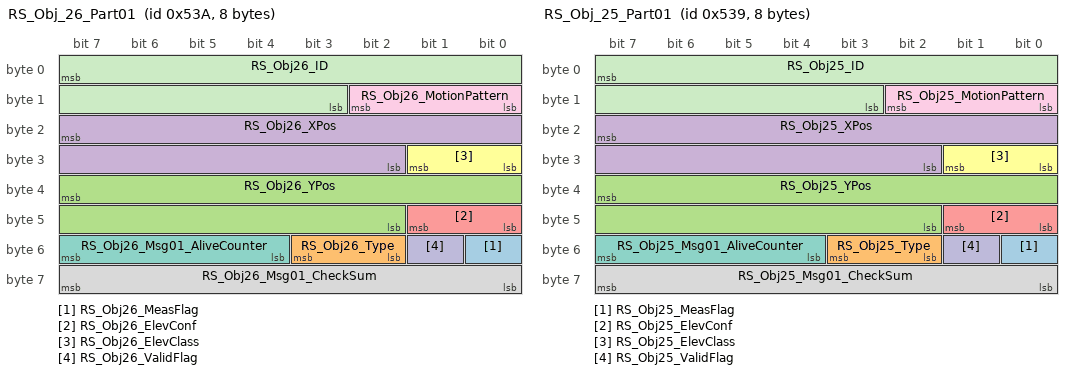
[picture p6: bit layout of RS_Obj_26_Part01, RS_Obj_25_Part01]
BO_ 1338 RS_Obj_26_Part01: 8 RS
 SG_ RS_Obj26_MeasFlag : 48|1@0+ (1,0) [0|1] "bit"  CAM
 SG_ RS_Obj26_Type : 51|2@0+ (1,0) [0|3] "bit"  CAM
 SG_ RS_Obj26_YPos : 39|14@0+ (0.02441,-200) [-200|199.90903] "m"  CAM
 SG_ RS_Obj26_XPos : 23|14@0+ (0.02441,-200) [-200|199.90903] "m"  CAM
 SG_ RS_Obj26_ElevConf : 41|2@0+ (1,0) [0|3] "bit"  CAM
 SG_ RS_Obj26_ElevClass : 25|2@0+ (1,0) [0|3] "bit"  CAM
 SG_ RS_Obj26_Msg01_AliveCounter : 55|4@0+ (1,0) [0|15] "bit"  CAM
 SG_ RS_Obj26_Msg01_CheckSum : 63|8@0+ (1,0) [0|255] "bit"  CAM
 SG_ RS_Obj26_MotionPattern : 10|3@0+ (1,0) [0|7] "bit"  CAM
 SG_ RS_Obj26_ValidFlag : 49|1@0+ (1,0) [0|1] "bit"  CAM
 SG_ RS_Obj26_ID : 7|13@0+ (1,0) [0|8191] "bit"  CAM

BO_ 1337 RS_Obj_25_Part01: 8 RS
 SG_ RS_Obj25_MeasFlag : 48|1@0+ (1,0) [0|1] "bit"  CAM
 SG_ RS_Obj25_Type : 51|2@0+ (1,0) [0|3] "bit"  CAM
 SG_ RS_Obj25_YPos : 39|14@0+ (0.02441,-200) [-200|199.90903] "m"  CAM
 SG_ RS_Obj25_XPos : 23|14@0+ (0.02441,-200) [-200|199.90903] "m"  CAM
 SG_ RS_Obj25_ElevConf : 41|2@0+ (1,0) [0|3] "bit"  CAM
 SG_ RS_Obj25_ElevClass : 25|2@0+ (1,0) [0|3] "bit"  CAM
 SG_ RS_Obj25_Msg01_AliveCounter : 55|4@0+ (1,0) [0|15] "bit"  CAM
 SG_ RS_Obj25_Msg01_CheckSum : 63|8@0+ (1,0) [0|255] "bit"  CAM
 SG_ RS_Obj25_MotionPattern : 10|3@0+ (1,0) [0|7] "bit"  CAM
 SG_ RS_Obj25_ValidFlag : 49|1@0+ (1,0) [0|1] "bit"  CAM
 SG_ RS_Obj25_ID : 7|13@0+ (1,0) [0|8191] "bit"  CAM

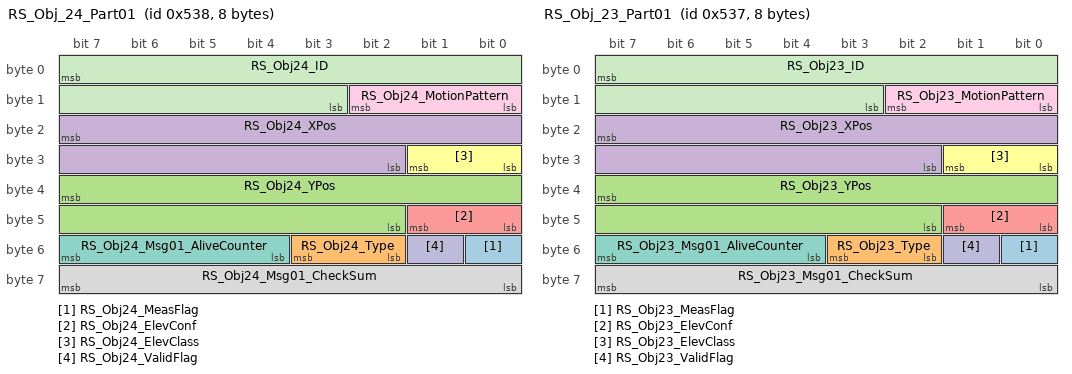
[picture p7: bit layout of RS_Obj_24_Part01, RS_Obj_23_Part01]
BO_ 1336 RS_Obj_24_Part01: 8 RS
 SG_ RS_Obj24_MeasFlag : 48|1@0+ (1,0) [0|1] "bit"  CAM
 SG_ RS_Obj24_Type : 51|2@0+ (1,0) [0|3] "bit"  CAM
 SG_ RS_Obj24_YPos : 39|14@0+ (0.02441,-200) [-200|199.90903] "m"  CAM
 SG_ RS_Obj24_XPos : 23|14@0+ (0.02441,-200) [-200|199.90903] "m"  CAM
 SG_ RS_Obj24_ElevConf : 41|2@0+ (1,0) [0|3] "bit"  CAM
 SG_ RS_Obj24_ElevClass : 25|2@0+ (1,0) [0|3] "bit"  CAM
 SG_ RS_Obj24_Msg01_AliveCounter : 55|4@0+ (1,0) [0|15] "bit"  CAM
 SG_ RS_Obj24_Msg01_CheckSum : 63|8@0+ (1,0) [0|255] "bit"  CAM
 SG_ RS_Obj24_MotionPattern : 10|3@0+ (1,0) [0|7] "bit"  CAM
 SG_ RS_Obj24_ValidFlag : 49|1@0+ (1,0) [0|1] "bit"  CAM
 SG_ RS_Obj24_ID : 7|13@0+ (1,0) [0|8191] "bit"  CAM

BO_ 1335 RS_Obj_23_Part01: 8 RS
 SG_ RS_Obj23_MeasFlag : 48|1@0+ (1,0) [0|1] "bit"  CAM
 SG_ RS_Obj23_Type : 51|2@0+ (1,0) [0|3] "bit"  CAM
 SG_ RS_Obj23_YPos : 39|14@0+ (0.02441,-200) [-200|199.90903] "m"  CAM
 SG_ RS_Obj23_XPos : 23|14@0+ (0.02441,-200) [-200|199.90903] "m"  CAM
 SG_ RS_Obj23_ElevConf : 41|2@0+ (1,0) [0|3] "bit"  CAM
 SG_ RS_Obj23_ElevClass : 25|2@0+ (1,0) [0|3] "bit"  CAM
 SG_ RS_Obj23_Msg01_AliveCounter : 55|4@0+ (1,0) [0|15] "bit"  CAM
 SG_ RS_Obj23_Msg01_CheckSum : 63|8@0+ (1,0) [0|255] "bit"  CAM
 SG_ RS_Obj23_MotionPattern : 10|3@0+ (1,0) [0|7] "bit"  CAM
 SG_ RS_Obj23_ValidFlag : 49|1@0+ (1,0) [0|1] "bit"  CAM
 SG_ RS_Obj23_ID : 7|13@0+ (1,0) [0|8191] "bit"  CAM

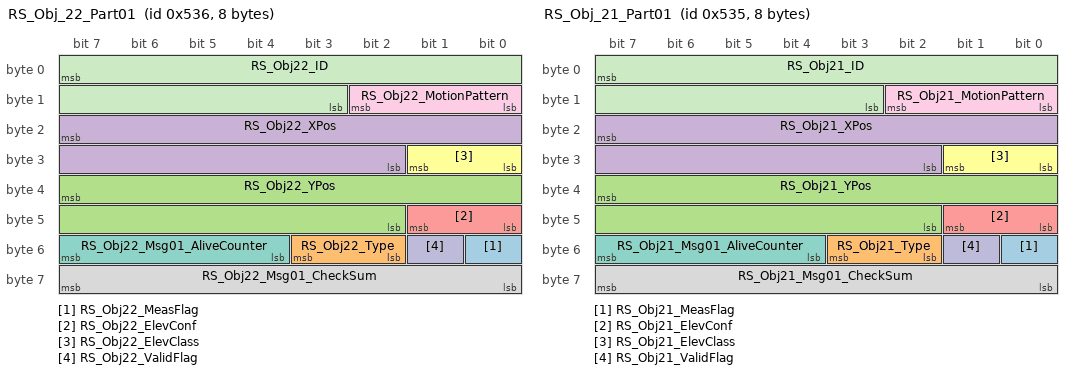
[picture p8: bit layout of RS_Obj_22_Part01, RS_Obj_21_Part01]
BO_ 1334 RS_Obj_22_Part01: 8 RS
 SG_ RS_Obj22_MeasFlag : 48|1@0+ (1,0) [0|1] "bit"  CAM
 SG_ RS_Obj22_Type : 51|2@0+ (1,0) [0|3] "bit"  CAM
 SG_ RS_Obj22_YPos : 39|14@0+ (0.02441,-200) [-200|199.90903] "m"  CAM
 SG_ RS_Obj22_XPos : 23|14@0+ (0.02441,-200) [-200|199.90903] "m"  CAM
 SG_ RS_Obj22_ElevConf : 41|2@0+ (1,0) [0|3] "bit"  CAM
 SG_ RS_Obj22_ElevClass : 25|2@0+ (1,0) [0|3] "bit"  CAM
 SG_ RS_Obj22_Msg01_AliveCounter : 55|4@0+ (1,0) [0|15] "bit"  CAM
 SG_ RS_Obj22_Msg01_CheckSum : 63|8@0+ (1,0) [0|255] "bit"  CAM
 SG_ RS_Obj22_MotionPattern : 10|3@0+ (1,0) [0|7] "bit"  CAM
 SG_ RS_Obj22_ValidFlag : 49|1@0+ (1,0) [0|1] "bit"  CAM
 SG_ RS_Obj22_ID : 7|13@0+ (1,0) [0|8191] "bit"  CAM

BO_ 1333 RS_Obj_21_Part01: 8 RS
 SG_ RS_Obj21_MeasFlag : 48|1@0+ (1,0) [0|1] "bit"  CAM
 SG_ RS_Obj21_Type : 51|2@0+ (1,0) [0|3] "bit"  CAM
 SG_ RS_Obj21_YPos : 39|14@0+ (0.02441,-200) [-200|199.90903] "m"  CAM
 SG_ RS_Obj21_XPos : 23|14@0+ (0.02441,-200) [-200|199.90903] "m"  CAM
 SG_ RS_Obj21_ElevConf : 41|2@0+ (1,0) [0|3] "bit"  CAM
 SG_ RS_Obj21_ElevClass : 25|2@0+ (1,0) [0|3] "bit"  CAM
 SG_ RS_Obj21_Msg01_AliveCounter : 55|4@0+ (1,0) [0|15] "bit"  CAM
 SG_ RS_Obj21_Msg01_CheckSum : 63|8@0+ (1,0) [0|255] "bit"  CAM
 SG_ RS_Obj21_MotionPattern : 10|3@0+ (1,0) [0|7] "bit"  CAM
 SG_ RS_Obj21_ValidFlag : 49|1@0+ (1,0) [0|1] "bit"  CAM
 SG_ RS_Obj21_ID : 7|13@0+ (1,0) [0|8191] "bit"  CAM

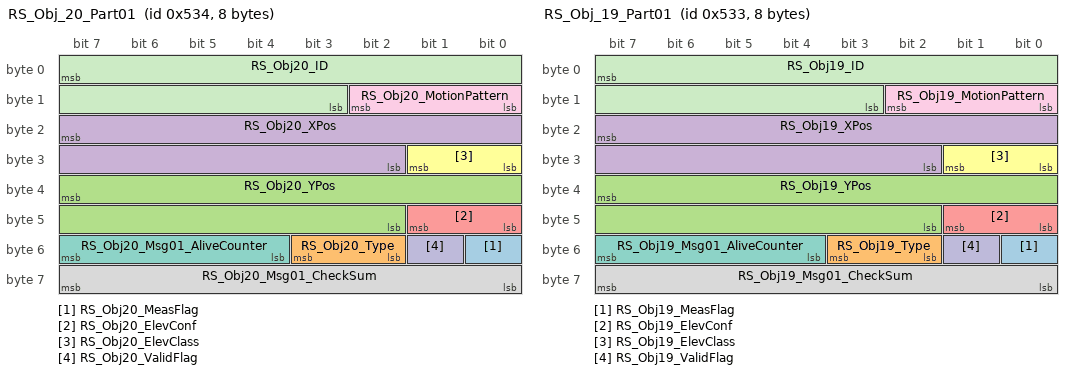
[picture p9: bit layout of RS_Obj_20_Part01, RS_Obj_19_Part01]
BO_ 1332 RS_Obj_20_Part01: 8 RS
 SG_ RS_Obj20_MeasFlag : 48|1@0+ (1,0) [0|1] "bit"  CAM
 SG_ RS_Obj20_Type : 51|2@0+ (1,0) [0|3] "bit"  CAM
 SG_ RS_Obj20_YPos : 39|14@0+ (0.02441,-200) [-200|199.90903] "m"  CAM
 SG_ RS_Obj20_XPos : 23|14@0+ (0.02441,-200) [-200|199.90903] "m"  CAM
 SG_ RS_Obj20_ElevConf : 41|2@0+ (1,0) [0|3] "bit"  CAM
 SG_ RS_Obj20_ElevClass : 25|2@0+ (1,0) [0|3] "bit"  CAM
 SG_ RS_Obj20_Msg01_AliveCounter : 55|4@0+ (1,0) [0|15] "bit"  CAM
 SG_ RS_Obj20_Msg01_CheckSum : 63|8@0+ (1,0) [0|255] "bit"  CAM
 SG_ RS_Obj20_MotionPattern : 10|3@0+ (1,0) [0|7] "bit"  CAM
 SG_ RS_Obj20_ValidFlag : 49|1@0+ (1,0) [0|1] "bit"  CAM
 SG_ RS_Obj20_ID : 7|13@0+ (1,0) [0|8191] "bit"  CAM

BO_ 1331 RS_Obj_19_Part01: 8 RS
 SG_ RS_Obj19_MeasFlag : 48|1@0+ (1,0) [0|1] "bit"  CAM
 SG_ RS_Obj19_Type : 51|2@0+ (1,0) [0|3] "bit"  CAM
 SG_ RS_Obj19_YPos : 39|14@0+ (0.02441,-200) [-200|199.90903] "m"  CAM
 SG_ RS_Obj19_XPos : 23|14@0+ (0.02441,-200) [-200|199.90903] "m"  CAM
 SG_ RS_Obj19_ElevConf : 41|2@0+ (1,0) [0|3] "bit"  CAM
 SG_ RS_Obj19_ElevClass : 25|2@0+ (1,0) [0|3] "bit"  CAM
 SG_ RS_Obj19_Msg01_AliveCounter : 55|4@0+ (1,0) [0|15] "bit"  CAM
 SG_ RS_Obj19_Msg01_CheckSum : 63|8@0+ (1,0) [0|255] "bit"  CAM
 SG_ RS_Obj19_MotionPattern : 10|3@0+ (1,0) [0|7] "bit"  CAM
 SG_ RS_Obj19_ValidFlag : 49|1@0+ (1,0) [0|1] "bit"  CAM
 SG_ RS_Obj19_ID : 7|13@0+ (1,0) [0|8191] "bit"  CAM

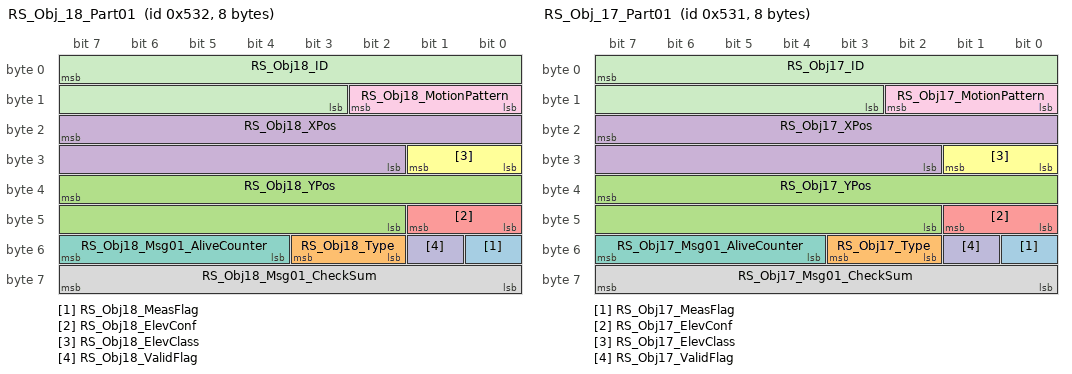
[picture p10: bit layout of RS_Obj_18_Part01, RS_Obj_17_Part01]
BO_ 1330 RS_Obj_18_Part01: 8 RS
 SG_ RS_Obj18_MeasFlag : 48|1@0+ (1,0) [0|1] "bit"  CAM
 SG_ RS_Obj18_Type : 51|2@0+ (1,0) [0|3] "bit"  CAM
 SG_ RS_Obj18_YPos : 39|14@0+ (0.02441,-200) [-200|199.90903] "m"  CAM
 SG_ RS_Obj18_XPos : 23|14@0+ (0.02441,-200) [-200|199.90903] "m"  CAM
 SG_ RS_Obj18_ElevConf : 41|2@0+ (1,0) [0|3] "bit"  CAM
 SG_ RS_Obj18_ElevClass : 25|2@0+ (1,0) [0|3] "bit"  CAM
 SG_ RS_Obj18_Msg01_AliveCounter : 55|4@0+ (1,0) [0|15] "bit"  CAM
 SG_ RS_Obj18_Msg01_CheckSum : 63|8@0+ (1,0) [0|255] "bit"  CAM
 SG_ RS_Obj18_MotionPattern : 10|3@0+ (1,0) [0|7] "bit"  CAM
 SG_ RS_Obj18_ValidFlag : 49|1@0+ (1,0) [0|1] "bit"  CAM
 SG_ RS_Obj18_ID : 7|13@0+ (1,0) [0|8191] "bit"  CAM

BO_ 1329 RS_Obj_17_Part01: 8 RS
 SG_ RS_Obj17_MeasFlag : 48|1@0+ (1,0) [0|1] "bit"  CAM
 SG_ RS_Obj17_Type : 51|2@0+ (1,0) [0|3] "bit"  CAM
 SG_ RS_Obj17_YPos : 39|14@0+ (0.02441,-200) [-200|199.90903] "m"  CAM
 SG_ RS_Obj17_XPos : 23|14@0+ (0.02441,-200) [-200|199.90903] "m"  CAM
 SG_ RS_Obj17_ElevConf : 41|2@0+ (1,0) [0|3] "bit"  CAM
 SG_ RS_Obj17_ElevClass : 25|2@0+ (1,0) [0|3] "bit"  CAM
 SG_ RS_Obj17_Msg01_AliveCounter : 55|4@0+ (1,0) [0|15] "bit"  CAM
 SG_ RS_Obj17_Msg01_CheckSum : 63|8@0+ (1,0) [0|255] "bit"  CAM
 SG_ RS_Obj17_MotionPattern : 10|3@0+ (1,0) [0|7] "bit"  CAM
 SG_ RS_Obj17_ValidFlag : 49|1@0+ (1,0) [0|1] "bit"  CAM
 SG_ RS_Obj17_ID : 7|13@0+ (1,0) [0|8191] "bit"  CAM

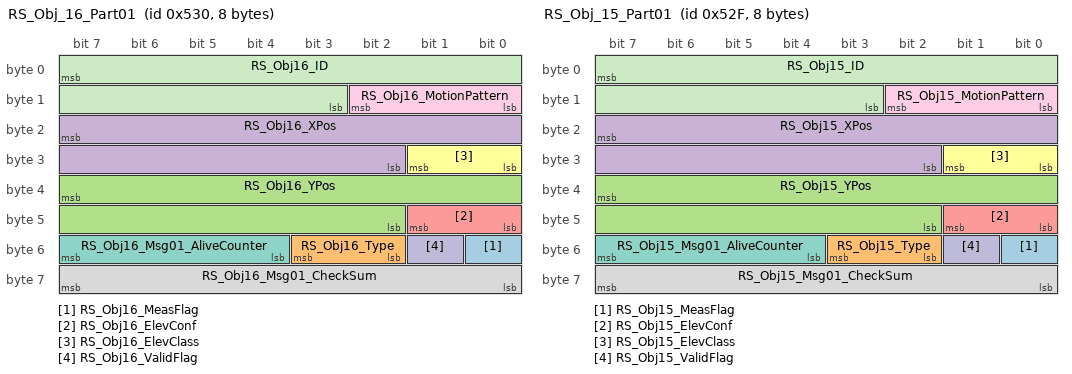
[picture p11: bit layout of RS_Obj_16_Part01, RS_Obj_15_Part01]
BO_ 1328 RS_Obj_16_Part01: 8 RS
 SG_ RS_Obj16_MeasFlag : 48|1@0+ (1,0) [0|1] "bit"  CAM
 SG_ RS_Obj16_Type : 51|2@0+ (1,0) [0|3] "bit"  CAM
 SG_ RS_Obj16_YPos : 39|14@0+ (0.02441,-200) [-200|199.90903] "m"  CAM
 SG_ RS_Obj16_XPos : 23|14@0+ (0.02441,-200) [-200|199.90903] "m"  CAM
 SG_ RS_Obj16_ElevConf : 41|2@0+ (1,0) [0|3] "bit"  CAM
 SG_ RS_Obj16_ElevClass : 25|2@0+ (1,0) [0|3] "bit"  CAM
 SG_ RS_Obj16_Msg01_AliveCounter : 55|4@0+ (1,0) [0|15] "bit"  CAM
 SG_ RS_Obj16_Msg01_CheckSum : 63|8@0+ (1,0) [0|255] "bit"  CAM
 SG_ RS_Obj16_MotionPattern : 10|3@0+ (1,0) [0|7] "bit"  CAM
 SG_ RS_Obj16_ValidFlag : 49|1@0+ (1,0) [0|1] "bit"  CAM
 SG_ RS_Obj16_ID : 7|13@0+ (1,0) [0|8191] "bit"  CAM

BO_ 1327 RS_Obj_15_Part01: 8 RS
 SG_ RS_Obj15_MeasFlag : 48|1@0+ (1,0) [0|1] "bit"  CAM
 SG_ RS_Obj15_Type : 51|2@0+ (1,0) [0|3] "bit"  CAM
 SG_ RS_Obj15_YPos : 39|14@0+ (0.02441,-200) [-200|199.90903] "m"  CAM
 SG_ RS_Obj15_XPos : 23|14@0+ (0.02441,-200) [-200|199.90903] "m"  CAM
 SG_ RS_Obj15_ElevConf : 41|2@0+ (1,0) [0|3] "bit"  CAM
 SG_ RS_Obj15_ElevClass : 25|2@0+ (1,0) [0|3] "bit"  CAM
 SG_ RS_Obj15_Msg01_AliveCounter : 55|4@0+ (1,0) [0|15] "bit"  CAM
 SG_ RS_Obj15_Msg01_CheckSum : 63|8@0+ (1,0) [0|255] "bit"  CAM
 SG_ RS_Obj15_MotionPattern : 10|3@0+ (1,0) [0|7] "bit"  CAM
 SG_ RS_Obj15_ValidFlag : 49|1@0+ (1,0) [0|1] "bit"  CAM
 SG_ RS_Obj15_ID : 7|13@0+ (1,0) [0|8191] "bit"  CAM

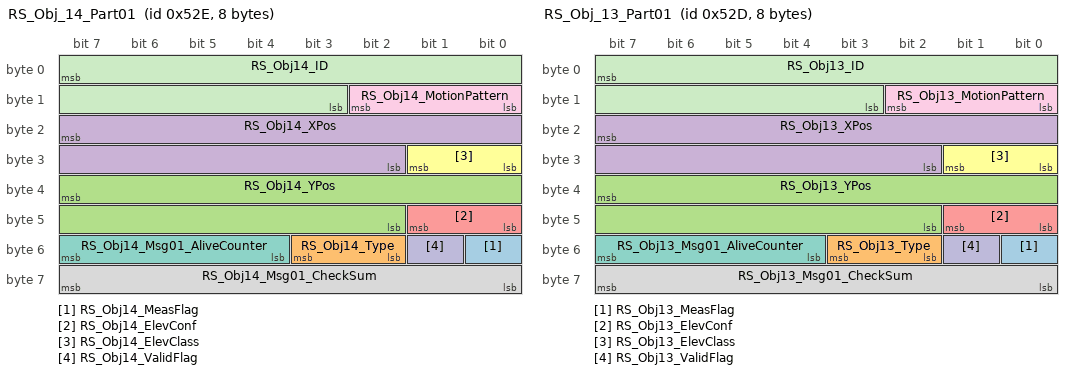
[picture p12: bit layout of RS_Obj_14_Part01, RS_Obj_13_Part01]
BO_ 1326 RS_Obj_14_Part01: 8 RS
 SG_ RS_Obj14_MeasFlag : 48|1@0+ (1,0) [0|1] "bit"  CAM
 SG_ RS_Obj14_Type : 51|2@0+ (1,0) [0|3] "bit"  CAM
 SG_ RS_Obj14_YPos : 39|14@0+ (0.02441,-200) [-200|199.90903] "m"  CAM
 SG_ RS_Obj14_XPos : 23|14@0+ (0.02441,-200) [-200|199.90903] "m"  CAM
 SG_ RS_Obj14_ElevConf : 41|2@0+ (1,0) [0|3] "bit"  CAM
 SG_ RS_Obj14_ElevClass : 25|2@0+ (1,0) [0|3] "bit"  CAM
 SG_ RS_Obj14_Msg01_AliveCounter : 55|4@0+ (1,0) [0|15] "bit"  CAM
 SG_ RS_Obj14_Msg01_CheckSum : 63|8@0+ (1,0) [0|255] "bit"  CAM
 SG_ RS_Obj14_MotionPattern : 10|3@0+ (1,0) [0|7] "bit"  CAM
 SG_ RS_Obj14_ValidFlag : 49|1@0+ (1,0) [0|1] "bit"  CAM
 SG_ RS_Obj14_ID : 7|13@0+ (1,0) [0|8191] "bit"  CAM

BO_ 1325 RS_Obj_13_Part01: 8 RS
 SG_ RS_Obj13_MeasFlag : 48|1@0+ (1,0) [0|1] "bit"  CAM
 SG_ RS_Obj13_Type : 51|2@0+ (1,0) [0|3] "bit"  CAM
 SG_ RS_Obj13_YPos : 39|14@0+ (0.02441,-200) [-200|199.90903] "m"  CAM
 SG_ RS_Obj13_XPos : 23|14@0+ (0.02441,-200) [-200|199.90903] "m"  CAM
 SG_ RS_Obj13_ElevConf : 41|2@0+ (1,0) [0|3] "bit"  CAM
 SG_ RS_Obj13_ElevClass : 25|2@0+ (1,0) [0|3] "bit"  CAM
 SG_ RS_Obj13_Msg01_AliveCounter : 55|4@0+ (1,0) [0|15] "bit"  CAM
 SG_ RS_Obj13_Msg01_CheckSum : 63|8@0+ (1,0) [0|255] "bit"  CAM
 SG_ RS_Obj13_MotionPattern : 10|3@0+ (1,0) [0|7] "bit"  CAM
 SG_ RS_Obj13_ValidFlag : 49|1@0+ (1,0) [0|1] "bit"  CAM
 SG_ RS_Obj13_ID : 7|13@0+ (1,0) [0|8191] "bit"  CAM

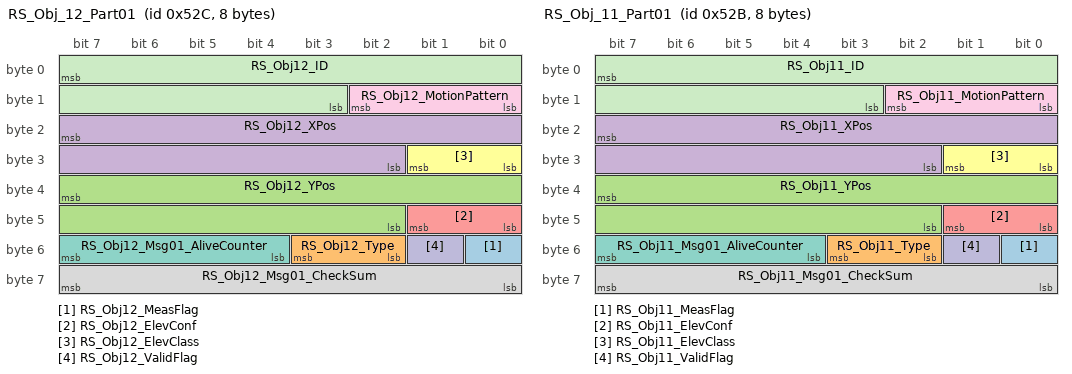
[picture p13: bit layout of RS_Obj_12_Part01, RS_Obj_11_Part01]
BO_ 1324 RS_Obj_12_Part01: 8 RS
 SG_ RS_Obj12_MeasFlag : 48|1@0+ (1,0) [0|1] "bit"  CAM
 SG_ RS_Obj12_Type : 51|2@0+ (1,0) [0|3] "bit"  CAM
 SG_ RS_Obj12_YPos : 39|14@0+ (0.02441,-200) [-200|199.90903] "m"  CAM
 SG_ RS_Obj12_XPos : 23|14@0+ (0.02441,-200) [-200|199.90903] "m"  CAM
 SG_ RS_Obj12_ElevConf : 41|2@0+ (1,0) [0|3] "bit"  CAM
 SG_ RS_Obj12_ElevClass : 25|2@0+ (1,0) [0|3] "bit"  CAM
 SG_ RS_Obj12_Msg01_AliveCounter : 55|4@0+ (1,0) [0|15] "bit"  CAM
 SG_ RS_Obj12_Msg01_CheckSum : 63|8@0+ (1,0) [0|255] "bit"  CAM
 SG_ RS_Obj12_MotionPattern : 10|3@0+ (1,0) [0|7] "bit"  CAM
 SG_ RS_Obj12_ValidFlag : 49|1@0+ (1,0) [0|1] "bit"  CAM
 SG_ RS_Obj12_ID : 7|13@0+ (1,0) [0|8191] "bit"  CAM

BO_ 1323 RS_Obj_11_Part01: 8 RS
 SG_ RS_Obj11_MeasFlag : 48|1@0+ (1,0) [0|1] "bit"  CAM
 SG_ RS_Obj11_Type : 51|2@0+ (1,0) [0|3] "bit"  CAM
 SG_ RS_Obj11_YPos : 39|14@0+ (0.02441,-200) [-200|199.90903] "m"  CAM
 SG_ RS_Obj11_XPos : 23|14@0+ (0.02441,-200) [-200|199.90903] "m"  CAM
 SG_ RS_Obj11_ElevConf : 41|2@0+ (1,0) [0|3] "bit"  CAM
 SG_ RS_Obj11_ElevClass : 25|2@0+ (1,0) [0|3] "bit"  CAM
 SG_ RS_Obj11_Msg01_AliveCounter : 55|4@0+ (1,0) [0|15] "bit"  CAM
 SG_ RS_Obj11_Msg01_CheckSum : 63|8@0+ (1,0) [0|255] "bit"  CAM
 SG_ RS_Obj11_MotionPattern : 10|3@0+ (1,0) [0|7] "bit"  CAM
 SG_ RS_Obj11_ValidFlag : 49|1@0+ (1,0) [0|1] "bit"  CAM
 SG_ RS_Obj11_ID : 7|13@0+ (1,0) [0|8191] "bit"  CAM

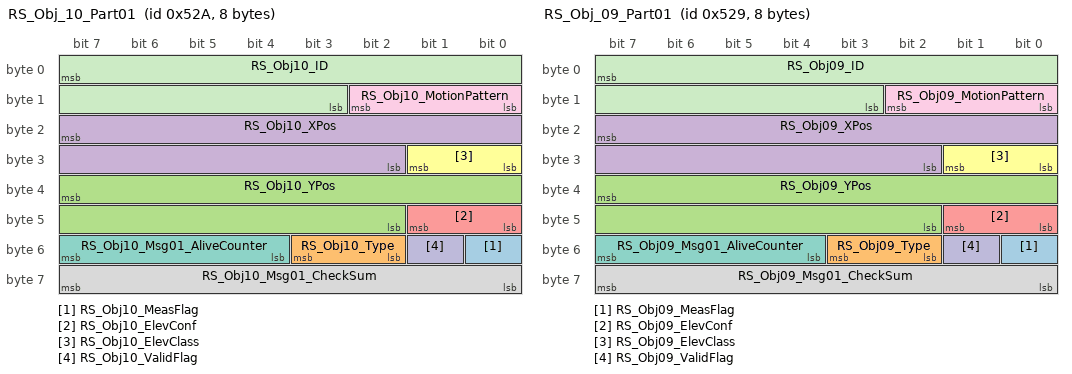
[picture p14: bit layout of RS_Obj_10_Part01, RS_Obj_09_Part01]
BO_ 1322 RS_Obj_10_Part01: 8 RS
 SG_ RS_Obj10_MeasFlag : 48|1@0+ (1,0) [0|1] "bit"  CAM
 SG_ RS_Obj10_Type : 51|2@0+ (1,0) [0|3] "bit"  CAM
 SG_ RS_Obj10_YPos : 39|14@0+ (0.02441,-200) [-200|199.90903] "m"  CAM
 SG_ RS_Obj10_XPos : 23|14@0+ (0.02441,-200) [-200|199.90903] "m"  CAM
 SG_ RS_Obj10_ElevConf : 41|2@0+ (1,0) [0|3] "bit"  CAM
 SG_ RS_Obj10_ElevClass : 25|2@0+ (1,0) [0|3] "bit"  CAM
 SG_ RS_Obj10_Msg01_AliveCounter : 55|4@0+ (1,0) [0|15] "bit"  CAM
 SG_ RS_Obj10_Msg01_CheckSum : 63|8@0+ (1,0) [0|255] "bit"  CAM
 SG_ RS_Obj10_MotionPattern : 10|3@0+ (1,0) [0|7] "bit"  CAM
 SG_ RS_Obj10_ValidFlag : 49|1@0+ (1,0) [0|1] "bit"  CAM
 SG_ RS_Obj10_ID : 7|13@0+ (1,0) [0|8191] "bit"  CAM

BO_ 1321 RS_Obj_09_Part01: 8 RS
 SG_ RS_Obj09_MeasFlag : 48|1@0+ (1,0) [0|1] "bit"  CAM
 SG_ RS_Obj09_Type : 51|2@0+ (1,0) [0|3] "bit"  CAM
 SG_ RS_Obj09_YPos : 39|14@0+ (0.02441,-200) [-200|199.90903] "m"  CAM
 SG_ RS_Obj09_XPos : 23|14@0+ (0.02441,-200) [-200|199.90903] "m"  CAM
 SG_ RS_Obj09_ElevConf : 41|2@0+ (1,0) [0|3] "bit"  CAM
 SG_ RS_Obj09_ElevClass : 25|2@0+ (1,0) [0|3] "bit"  CAM
 SG_ RS_Obj09_Msg01_AliveCounter : 55|4@0+ (1,0) [0|15] "bit"  CAM
 SG_ RS_Obj09_Msg01_CheckSum : 63|8@0+ (1,0) [0|255] "bit"  CAM
 SG_ RS_Obj09_MotionPattern : 10|3@0+ (1,0) [0|7] "bit"  CAM
 SG_ RS_Obj09_ValidFlag : 49|1@0+ (1,0) [0|1] "bit"  CAM
 SG_ RS_Obj09_ID : 7|13@0+ (1,0) [0|8191] "bit"  CAM

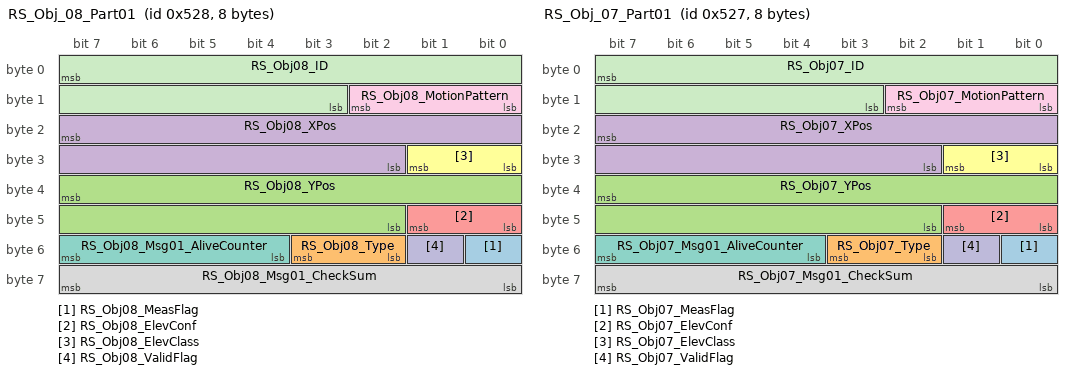
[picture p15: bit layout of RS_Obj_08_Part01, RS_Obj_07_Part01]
BO_ 1320 RS_Obj_08_Part01: 8 RS
 SG_ RS_Obj08_MeasFlag : 48|1@0+ (1,0) [0|1] "bit"  CAM
 SG_ RS_Obj08_Type : 51|2@0+ (1,0) [0|3] "bit"  CAM
 SG_ RS_Obj08_YPos : 39|14@0+ (0.02441,-200) [-200|199.90903] "m"  CAM
 SG_ RS_Obj08_XPos : 23|14@0+ (0.02441,-200) [-200|199.90903] "m"  CAM
 SG_ RS_Obj08_ElevConf : 41|2@0+ (1,0) [0|3] "bit"  CAM
 SG_ RS_Obj08_ElevClass : 25|2@0+ (1,0) [0|3] "bit"  CAM
 SG_ RS_Obj08_Msg01_AliveCounter : 55|4@0+ (1,0) [0|15] "bit"  CAM
 SG_ RS_Obj08_Msg01_CheckSum : 63|8@0+ (1,0) [0|255] "bit"  CAM
 SG_ RS_Obj08_MotionPattern : 10|3@0+ (1,0) [0|7] "bit"  CAM
 SG_ RS_Obj08_ValidFlag : 49|1@0+ (1,0) [0|1] "bit"  CAM
 SG_ RS_Obj08_ID : 7|13@0+ (1,0) [0|8191] "bit"  CAM

BO_ 1319 RS_Obj_07_Part01: 8 RS
 SG_ RS_Obj07_MeasFlag : 48|1@0+ (1,0) [0|1] "bit"  CAM
 SG_ RS_Obj07_Type : 51|2@0+ (1,0) [0|3] "bit"  CAM
 SG_ RS_Obj07_YPos : 39|14@0+ (0.02441,-200) [-200|199.90903] "m"  CAM
 SG_ RS_Obj07_XPos : 23|14@0+ (0.02441,-200) [-200|199.90903] "m"  CAM
 SG_ RS_Obj07_ElevConf : 41|2@0+ (1,0) [0|3] "bit"  CAM
 SG_ RS_Obj07_ElevClass : 25|2@0+ (1,0) [0|3] "bit"  CAM
 SG_ RS_Obj07_Msg01_AliveCounter : 55|4@0+ (1,0) [0|15] "bit"  CAM
 SG_ RS_Obj07_Msg01_CheckSum : 63|8@0+ (1,0) [0|255] "bit"  CAM
 SG_ RS_Obj07_MotionPattern : 10|3@0+ (1,0) [0|7] "bit"  CAM
 SG_ RS_Obj07_ValidFlag : 49|1@0+ (1,0) [0|1] "bit"  CAM
 SG_ RS_Obj07_ID : 7|13@0+ (1,0) [0|8191] "bit"  CAM

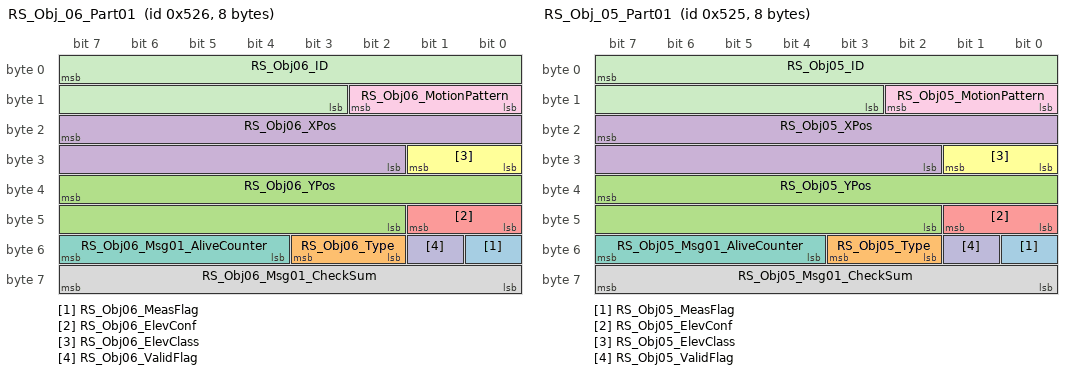
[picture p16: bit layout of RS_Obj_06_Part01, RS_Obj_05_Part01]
BO_ 1318 RS_Obj_06_Part01: 8 RS
 SG_ RS_Obj06_MeasFlag : 48|1@0+ (1,0) [0|1] "bit"  CAM
 SG_ RS_Obj06_Type : 51|2@0+ (1,0) [0|3] "bit"  CAM
 SG_ RS_Obj06_YPos : 39|14@0+ (0.02441,-200) [-200|199.90903] "m"  CAM
 SG_ RS_Obj06_XPos : 23|14@0+ (0.02441,-200) [-200|199.90903] "m"  CAM
 SG_ RS_Obj06_ElevConf : 41|2@0+ (1,0) [0|3] "bit"  CAM
 SG_ RS_Obj06_ElevClass : 25|2@0+ (1,0) [0|3] "bit"  CAM
 SG_ RS_Obj06_Msg01_AliveCounter : 55|4@0+ (1,0) [0|15] "bit"  CAM
 SG_ RS_Obj06_Msg01_CheckSum : 63|8@0+ (1,0) [0|255] "bit"  CAM
 SG_ RS_Obj06_MotionPattern : 10|3@0+ (1,0) [0|7] "bit"  CAM
 SG_ RS_Obj06_ValidFlag : 49|1@0+ (1,0) [0|1] "bit"  CAM
 SG_ RS_Obj06_ID : 7|13@0+ (1,0) [0|8191] "bit"  CAM

BO_ 1317 RS_Obj_05_Part01: 8 RS
 SG_ RS_Obj05_MeasFlag : 48|1@0+ (1,0) [0|1] "bit"  CAM
 SG_ RS_Obj05_Type : 51|2@0+ (1,0) [0|3] "bit"  CAM
 SG_ RS_Obj05_YPos : 39|14@0+ (0.02441,-200) [-200|199.90903] "m"  CAM
 SG_ RS_Obj05_XPos : 23|14@0+ (0.02441,-200) [-200|199.90903] "m"  CAM
 SG_ RS_Obj05_ElevConf : 41|2@0+ (1,0) [0|3] "bit"  CAM
 SG_ RS_Obj05_ElevClass : 25|2@0+ (1,0) [0|3] "bit"  CAM
 SG_ RS_Obj05_Msg01_AliveCounter : 55|4@0+ (1,0) [0|15] "bit"  CAM
 SG_ RS_Obj05_Msg01_CheckSum : 63|8@0+ (1,0) [0|255] "bit"  CAM
 SG_ RS_Obj05_MotionPattern : 10|3@0+ (1,0) [0|7] "bit"  CAM
 SG_ RS_Obj05_ValidFlag : 49|1@0+ (1,0) [0|1] "bit"  CAM
 SG_ RS_Obj05_ID : 7|13@0+ (1,0) [0|8191] "bit"  CAM

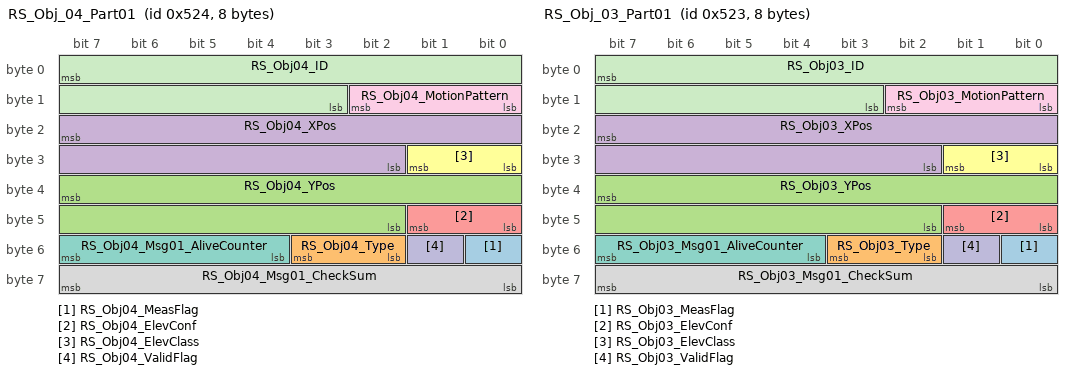
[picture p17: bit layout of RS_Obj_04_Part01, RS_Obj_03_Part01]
BO_ 1316 RS_Obj_04_Part01: 8 RS
 SG_ RS_Obj04_MeasFlag : 48|1@0+ (1,0) [0|1] "bit"  CAM
 SG_ RS_Obj04_Type : 51|2@0+ (1,0) [0|3] "bit"  CAM
 SG_ RS_Obj04_YPos : 39|14@0+ (0.02441,-200) [-200|199.90903] "m"  CAM
 SG_ RS_Obj04_XPos : 23|14@0+ (0.02441,-200) [-200|199.90903] "m"  CAM
 SG_ RS_Obj04_ElevConf : 41|2@0+ (1,0) [0|3] "bit"  CAM
 SG_ RS_Obj04_ElevClass : 25|2@0+ (1,0) [0|3] "bit"  CAM
 SG_ RS_Obj04_Msg01_AliveCounter : 55|4@0+ (1,0) [0|15] "bit"  CAM
 SG_ RS_Obj04_Msg01_CheckSum : 63|8@0+ (1,0) [0|255] "bit"  CAM
 SG_ RS_Obj04_MotionPattern : 10|3@0+ (1,0) [0|7] "bit"  CAM
 SG_ RS_Obj04_ValidFlag : 49|1@0+ (1,0) [0|1] "bit"  CAM
 SG_ RS_Obj04_ID : 7|13@0+ (1,0) [0|8191] "bit"  CAM

BO_ 1315 RS_Obj_03_Part01: 8 RS
 SG_ RS_Obj03_MeasFlag : 48|1@0+ (1,0) [0|1] "bit"  CAM
 SG_ RS_Obj03_Type : 51|2@0+ (1,0) [0|3] "bit"  CAM
 SG_ RS_Obj03_YPos : 39|14@0+ (0.02441,-200) [-200|199.90903] "m"  CAM
 SG_ RS_Obj03_XPos : 23|14@0+ (0.02441,-200) [-200|199.90903] "m"  CAM
 SG_ RS_Obj03_ElevConf : 41|2@0+ (1,0) [0|3] "bit"  CAM
 SG_ RS_Obj03_ElevClass : 25|2@0+ (1,0) [0|3] "bit"  CAM
 SG_ RS_Obj03_Msg01_AliveCounter : 55|4@0+ (1,0) [0|15] "bit"  CAM
 SG_ RS_Obj03_Msg01_CheckSum : 63|8@0+ (1,0) [0|255] "bit"  CAM
 SG_ RS_Obj03_MotionPattern : 10|3@0+ (1,0) [0|7] "bit"  CAM
 SG_ RS_Obj03_ValidFlag : 49|1@0+ (1,0) [0|1] "bit"  CAM
 SG_ RS_Obj03_ID : 7|13@0+ (1,0) [0|8191] "bit"  CAM

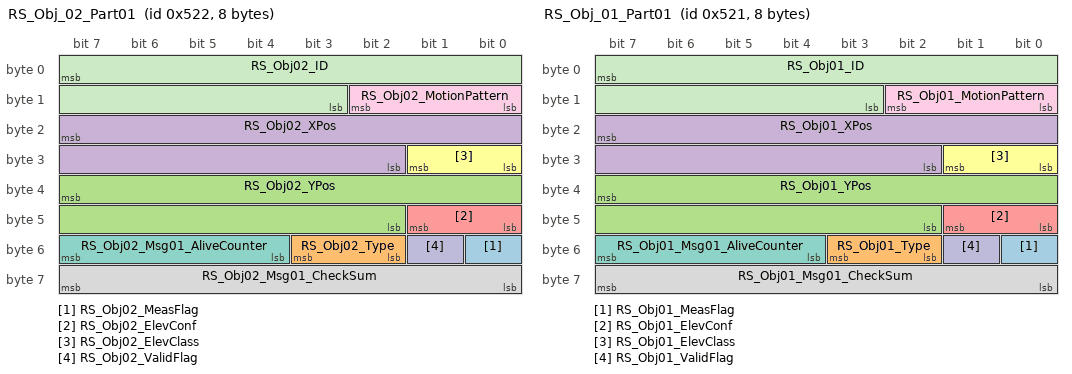
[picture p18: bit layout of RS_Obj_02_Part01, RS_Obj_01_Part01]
BO_ 1314 RS_Obj_02_Part01: 8 RS
 SG_ RS_Obj02_MeasFlag : 48|1@0+ (1,0) [0|1] "bit"  CAM
 SG_ RS_Obj02_Type : 51|2@0+ (1,0) [0|3] "bit"  CAM
 SG_ RS_Obj02_YPos : 39|14@0+ (0.02441,-200) [-200|199.90903] "m"  CAM
 SG_ RS_Obj02_XPos : 23|14@0+ (0.02441,-200) [-200|199.90903] "m"  CAM
 SG_ RS_Obj02_ElevConf : 41|2@0+ (1,0) [0|3] "bit"  CAM
 SG_ RS_Obj02_ElevClass : 25|2@0+ (1,0) [0|3] "bit"  CAM
 SG_ RS_Obj02_Msg01_AliveCounter : 55|4@0+ (1,0) [0|15] "bit"  CAM
 SG_ RS_Obj02_Msg01_CheckSum : 63|8@0+ (1,0) [0|255] "bit"  CAM
 SG_ RS_Obj02_MotionPattern : 10|3@0+ (1,0) [0|7] "bit"  CAM
 SG_ RS_Obj02_ValidFlag : 49|1@0+ (1,0) [0|1] "bit"  CAM
 SG_ RS_Obj02_ID : 7|13@0+ (1,0) [0|8191] "bit"  CAM

BO_ 1313 RS_Obj_01_Part01: 8 RS
 SG_ RS_Obj01_MeasFlag : 48|1@0+ (1,0) [0|1] "bit"  CAM
 SG_ RS_Obj01_Type : 51|2@0+ (1,0) [0|3] "bit"  CAM
 SG_ RS_Obj01_YPos : 39|14@0+ (0.02441,-200) [-200|199.90903] "m"  CAM
 SG_ RS_Obj01_XPos : 23|14@0+ (0.02441,-200) [-200|199.90903] "m"  CAM
 SG_ RS_Obj01_ElevConf : 41|2@0+ (1,0) [0|3] "bit"  CAM
 SG_ RS_Obj01_ElevClass : 25|2@0+ (1,0) [0|3] "bit"  CAM
 SG_ RS_Obj01_Msg01_AliveCounter : 55|4@0+ (1,0) [0|15] "bit"  CAM
 SG_ RS_Obj01_Msg01_CheckSum : 63|8@0+ (1,0) [0|255] "bit"  CAM
 SG_ RS_Obj01_MotionPattern : 10|3@0+ (1,0) [0|7] "bit"  CAM
 SG_ RS_Obj01_ValidFlag : 49|1@0+ (1,0) [0|1] "bit"  CAM
 SG_ RS_Obj01_ID : 7|13@0+ (1,0) [0|8191] "bit"  CAM

BO_ 1360 RS_Obj_00_Part02: 8 RS
 SG_ RS_Obj00_CtrkInd : 16|1@0+ (1,0) [0|1] "bit"  CAM
 SG_ RS_Obj00_YVelAbsolute : 36|11@0+ (0.1,-102.4) [-102.4|102.3] "m/s"  CAM
 SG_ RS_Obj00_XVelAbsolute : 31|11@0+ (0.1,-102.4) [-102.4|102.3] "m/s"  CAM
 SG_ RS_Obj00_heading : 23|7@0- (0.049087,0.049087) [-3.092481|3.141568] "rad"  CAM
 SG_ RS_Obj00_Classconf : 41|6@0+ (1.5873,0) [0|100] "%"  CAM
 SG_ RS_Obj00_YAccAbsolute : 15|8@0+ (0.2,-25.6) [-25.6|25.4] "m/s2"  CAM
 SG_ RS_Obj00_XAccAbsolute : 7|8@0+ (0.2,-25.6) [-25.6|25.4] "m/s2"  CAM
 SG_ RS_Obj00_Msg02_CheckSum : 63|8@0+ (1,0) [0|255] "bit"  CAM
 SG_ RS_Obj00_Msg02_AliveCounter : 51|4@0+ (1,0) [0|15] "bit"  CAM

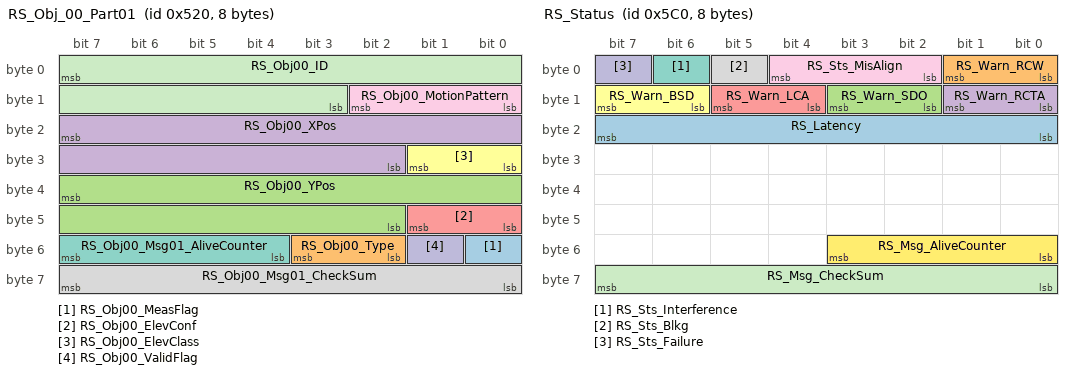
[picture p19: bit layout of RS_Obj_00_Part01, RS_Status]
BO_ 1312 RS_Obj_00_Part01: 8 RS
 SG_ RS_Obj00_MeasFlag : 48|1@0+ (1,0) [0|1] "bit"  CAM
 SG_ RS_Obj00_Type : 51|2@0+ (1,0) [0|3] "bit"  CAM
 SG_ RS_Obj00_YPos : 39|14@0+ (0.02441,-200) [-200|199.90903] "m"  CAM
 SG_ RS_Obj00_XPos : 23|14@0+ (0.02441,-200) [-200|199.90903] "m"  CAM
 SG_ RS_Obj00_ElevConf : 41|2@0+ (1,0) [0|3] "bit"  CAM
 SG_ RS_Obj00_ElevClass : 25|2@0+ (1,0) [0|3] "bit"  CAM
 SG_ RS_Obj00_Msg01_AliveCounter : 55|4@0+ (1,0) [0|15] "bit"  CAM
 SG_ RS_Obj00_Msg01_CheckSum : 63|8@0+ (1,0) [0|255] "bit"  CAM
 SG_ RS_Obj00_MotionPattern : 10|3@0+ (1,0) [0|7] "bit"  CAM
 SG_ RS_Obj00_ValidFlag : 49|1@0+ (1,0) [0|1] "bit"  CAM
 SG_ RS_Obj00_ID : 7|13@0+ (1,0) [0|8191] "bit"  CAM

BO_ 1472 RS_Status: 8 RS
 SG_ RS_Latency : 23|8@0+ (0.005,0) [0|1.275] "s"  CAM
 SG_ RS_Warn_RCW : 1|2@0+ (1,0) [0|3] "bit"  CAM
 SG_ RS_Warn_SDO : 11|2@0+ (1,0) [0|3] "bit"  CAM
 SG_ RS_Warn_RCTA : 9|2@0+ (1,0) [0|3] "bit"  CAM
 SG_ RS_Warn_LCA : 13|2@0+ (1,0) [0|3] "bit"  CAM
 SG_ RS_Warn_BSD : 15|2@0+ (1,0) [0|3] "bit"  CAM
 SG_ RS_Sts_Interference : 6|1@0+ (1,0) [0|1] "bit"  CAM
 SG_ RS_Sts_Blkg : 5|1@0+ (1,0) [0|1] "bit"  CAM
 SG_ RS_Sts_MisAlign : 4|3@0+ (1,0) [0|7] "bit"  CAM
 SG_ RS_Sts_Failure : 7|1@0+ (1,0) [0|1] "bit"  CAM
 SG_ RS_Msg_CheckSum : 63|8@0+ (1,0) [0|255] "bit"  CAM
 SG_ RS_Msg_AliveCounter : 51|4@0+ (1,0) [0|15] "bit"  CAM

BO_ 1074 NWM_RS: 8 RS
 SG_ RS_AWB : 12|1@0+ (1,0) [0|1] "bit" Vector__XXX
 SG_ RS_Address : 7|8@0+ (1,0) [0|127] "bit" Vector__XXX
 SG_ RS_RMR : 8|1@0+ (1,0) [0|1] "bit" Vector__XXX
 SG_ RS_NMSts : 24|1@0+ (1,0) [0|1] "bit" Vector__XXX
 SG_ RS_Stayawake_reasons : 39|32@0+ (1,0) [0|127] "bit" Vector__XXX
 SG_ RS_Wakeup_reasons : 23|8@0+ (1,0) [0|255] "bit" Vector__XXX

BO_ 2015 Func_DiagReq: 8 GW
 SG_ Func_DiagReq_Byte7 : 63|8@0+ (1,0) [0|255] "" Vector__XXX
 SG_ Func_DiagReq_Byte6 : 55|8@0+ (1,0) [0|255] "" Vector__XXX
 SG_ Func_DiagReq_Byte5 : 47|8@0+ (1,0) [0|255] "" Vector__XXX
 SG_ Func_DiagReq_Byte4 : 39|8@0+ (1,0) [0|255] "" Vector__XXX
 SG_ Func_DiagReq_Byte3 : 31|8@0+ (1,0) [0|255] "" Vector__XXX
 SG_ Func_DiagReq_Byte2 : 23|8@0+ (1,0) [0|255] ""  RS
 SG_ Func_DiagReq_Byte0 : 7|8@0+ (1,0) [0|255] "" Vector__XXX

BO_ 357 VCU_ModeControl: 8 VCU
 SG_ VCU_ModeControl_CheckSum : 63|8@0+ (1,0) [0|255] "bit"  RS
 SG_ VCU_ModeControl_AliveCounter : 51|4@0+ (1,0) [0|15] "bit"  RS
 SG_ VCU_CurrentGearPosition : 23|4@0+ (1,0) [0|15] "bit"  RS

BO_ 304 YRS1: 8 ACU
 SG_ YRS_LateralSensorState : 12|2@0+ (1,0) [0|3] "bit"  RS
 SG_ YRS1_CheckSum : 7|8@0+ (1,0) [0|255] "bit"  RS
 SG_ YRS_LateralAcce : 23|16@0+ (0.001,-2) [-2|2] "g"  RS
 SG_ YRS_YawRate : 39|16@0+ (0.01,-180) [-180|180] "degree/s"  RS
 SG_ YRS1_AliveCounter : 59|4@0+ (1,0) [0|15] "bit"  RS
 SG_ YRS_YawRateSensorState : 10|2@0+ (1,0) [0|3] "bit"  RS

BO_ 305 YRS2: 8 ACU
 SG_ YRS_LongitSensorState : 15|2@0+ (1,0) [0|3] "bit"  RS
 SG_ YRS2_CheckSum : 7|8@0+ (1,0) [0|255] "bit"  RS
 SG_ YRS_LongitAcce : 23|16@0+ (0.001,-2) [-2|2] "g"  RS
 SG_ YRS2_AliveCounter : 59|4@0+ (1,0) [0|15] "bit"  RS

BO_ 224 SAS_Status: 8 TCM
 SG_ SAS_FailureSts : 31|1@0+ (1,0) [0|1] "bit"  RS
 SG_ SAS_Status_AliveCounter : 39|4@0+ (1,0) [0|15] "bit"  RS
 SG_ SAS_Status_CheckSum : 47|8@0+ (1,0) [0|255] "bit"  RS
 SG_ SAS_SteerWheelAngle : 7|16@0- (0.1,0) [-780|779.9] "degree/bit"  RS

BO_ 293 ESC_Status: 8 ESC
 SG_ ESC_VehicleSpeedInvalid : 18|1@0+ (1,0) [0|1] "bit"  RS
 SG_ ESC_VehicleSpeed : 15|13@0+ (0.05625,0) [0|460.63125] "KPH"  RS
 SG_ ESC_Status_AliveCounter : 51|4@0+ (1,0) [0|15] "bit"  RS
 SG_ ESC_Status_CheckSum : 63|8@0+ (1,0) [0|255] "bit"  RS

BO_ 133 EMS_EngineRPM: 8 GW
 SG_ EMS_EngineRPM_AliveCounter : 63|4@0+ (1,0) [0|15] "bit"  RS
 SG_ EMS_EngineRPM_CheckSum : 39|8@0+ (1,0) [0|255] "bit"  RS
 SG_ EMS_EngStatus : 47|3@0+ (1,0) [0|7] "bit"  RS

BO_ 275 TCU_Status: 8 GW
 SG_ TCU_Status_AliveCounter : 51|4@0+ (1,0) [0|15] "bit"  RS
 SG_ TCU_CurrentGearPosition : 39|4@0+ (1,0) [0|15] "bit"  RS
 SG_ TCU_Status_CheckSum : 63|8@0+ (1,0) [0|255] "bit"  RS

BO_ 1009 IPK_TotalOdometer: 8 GW
 SG_ IPK_IPKTotalOdometer : 7|24@0+ (0.1,0) [0|999999] "KM"  RS

CM_ " ";
CM_ BO_ 304 "Transmitted by ACU , including ACU YRS signals";
CM_ SG_ 304 YRS1_CheckSum "YRS1_Checksum";
CM_ SG_ 304 YRS_LateralAcce "Indicates Lateral Acceleration
0x0FA1~0xFFFF: Invalid";
CM_ SG_ 304 YRS_YawRate "Indicates Yaw Rate
0x8CA1~0xFFFF: Invalid";
CM_ SG_ 304 YRS1_AliveCounter "Indicates the message sending number";
CM_ SG_ 304 YRS_YawRateSensorState "Indicates YawRate Sensor State";
CM_ BO_ 305 "Transmitted by ACU , including ACU YRS signals";
CM_ SG_ 305 YRS2_CheckSum "YRS2_CheckSum";
CM_ SG_ 305 YRS_LongitAcce "Indicates Longitudinal Acceleration
0x0FA1~0xFFFF: Invalid";
CM_ SG_ 305 YRS2_AliveCounter "Indicates the message sending number";
CM_ BO_ 224 "Transmitted by SAS, including SAS sensor status singals";
CM_ SG_ 224 SAS_FailureSts "SAS failure status";
CM_ SG_ 224 SAS_Status_AliveCounter "Message counter";
CM_ SG_ 224 SAS_Status_CheckSum "SAS_Status checksum ";
CM_ SG_ 224 SAS_SteerWheelAngle "Actual steering wheel angle";
CM_ BO_ 293 "Transmitted by ESC, including ESC status ,Vehicle Speed and Brake switch status";
CM_ SG_ 293 ESC_VehicleSpeedInvalid "Signal from ABS_ESC to indicate if VehicleSpeed is valid";
CM_ SG_ 293 ESC_VehicleSpeed "Vehicle Speed";
CM_ SG_ 293 ESC_Status_AliveCounter "Message Rolling counter";
CM_ SG_ 293 ESC_Status_CheckSum "ESC_Status checksum ";
CM_ BO_ 133 "Transmitted by EMS, including RPM and accel. padel position status";
CM_ SG_ 133 EMS_EngStatus "Engine running status";
CM_ BO_ 275 "Transmitted by TCU, including TCU req and states";
CM_ SG_ 275 TCU_CurrentGearPosition "TCU current Gear status";
CM_ SG_ 275 TCU_Status_CheckSum "TCU_Status checksum ";
CM_ BO_ 1009 "Transmitted by IPK , including Total Odometer";
CM_ SG_ 1009 IPK_IPKTotalOdometer "The total odometer displayed in IPK";
BA_DEF_ SG_  "CustomizedSignalType" ENUM  "Norm","CRC","ALC","vector_leerstring";
BA_DEF_  "NmAsrWaitBusSleepTime" INT 0 65535;
BA_DEF_  "NmAsrTimeoutTime" INT 0 65535;
BA_DEF_  "NmAsrRepeatMessageTime" INT 0 65535;
BA_DEF_ BU_  "NmAsrNodeIdentifier" INT 0 255;
BA_DEF_ BU_  "NmAsrNode" ENUM  "no","yes";
BA_DEF_  "NmAsrMessageCount" INT 0 256;
BA_DEF_ BO_  "NmAsrMessage" ENUM  "no","yes";
BA_DEF_ BU_  "NmAsrCanMsgReducedTime" INT 0 65535;
BA_DEF_  "NmAsrCanMsgCycleTime" INT 0 65535;
BA_DEF_  "NmAsrBaseAddress" HEX 0 65535;
BA_DEF_ BO_  "DiagState" ENUM  "No","Yes";
BA_DEF_ BO_  "DiagRequest" ENUM  "No","Yes";
BA_DEF_ BO_  "DiagResponse" ENUM  "No","Yes";
BA_DEF_ BO_  "GenMsgSendType" ENUM  "Cyclic","NotUsed","NotUsed","NotUsed","NotUsed","NotUsed","NotUsed","NotUsed","NoMsgSendType";
BA_DEF_ BO_  "GenMsgCycleTime" INT 0 0;
BA_DEF_ SG_  "GenSigSendType" ENUM  "Cyclic","OnWrite","NotUsed","OnChange","NotUsed","NotUsed","NotUsed","NoSigSendType";
BA_DEF_ SG_  "GenSigStartValue" INT 0 0;
BA_DEF_ SG_  "GenSigInactiveValue" INT 0 0;
BA_DEF_  "DBName" STRING ;
BA_DEF_ BU_  "NodeLayerModules" STRING ;
BA_DEF_ BU_  "ILUsed" ENUM  "No","Yes";
BA_DEF_  "Manufacturer" STRING ;
BA_DEF_  "NmType" STRING ;
BA_DEF_ BO_  "GenMsgILSupport" ENUM  "No","Yes";
BA_DEF_ BO_  "GenMsgStartDelayTime" INT 0 65535;
BA_DEF_  "BusType" STRING ;
BA_DEF_DEF_  "CustomizedSignalType" "Norm";
BA_DEF_DEF_  "NmAsrWaitBusSleepTime" 750;
BA_DEF_DEF_  "NmAsrTimeoutTime" 1000;
BA_DEF_DEF_  "NmAsrRepeatMessageTime" 400;
BA_DEF_DEF_  "NmAsrNodeIdentifier" 0;
BA_DEF_DEF_  "NmAsrNode" "yes";
BA_DEF_DEF_  "NmAsrMessageCount" 64;
BA_DEF_DEF_  "NmAsrMessage" "no";
BA_DEF_DEF_  "NmAsrCanMsgReducedTime" 50;
BA_DEF_DEF_  "NmAsrCanMsgCycleTime" 100;
BA_DEF_DEF_  "NmAsrBaseAddress" 1024;
BA_DEF_DEF_  "DiagState" "No";
BA_DEF_DEF_  "DiagRequest" "No";
BA_DEF_DEF_  "DiagResponse" "No";
BA_DEF_DEF_  "GenMsgSendType" "NoMsgSendType";
BA_DEF_DEF_  "GenMsgCycleTime" 0;
BA_DEF_DEF_  "GenSigSendType" "Cyclic";
BA_DEF_DEF_  "GenSigStartValue" 0;
BA_DEF_DEF_  "GenSigInactiveValue" 0;
BA_DEF_DEF_  "DBName" "";
BA_DEF_DEF_  "NodeLayerModules" "CANoeILNLVector.dll";
BA_DEF_DEF_  "ILUsed" "Yes";
BA_DEF_DEF_  "Manufacturer" "";
BA_DEF_DEF_  "NmType" "";
BA_DEF_DEF_  "GenMsgILSupport" "Yes";
BA_DEF_DEF_  "GenMsgStartDelayTime" 0;
BA_DEF_DEF_  "BusType" "CAN";
BA_ "NmAsrMessageCount" 128;
BA_ "NmAsrCanMsgCycleTime" 500;
BA_ "NmAsrRepeatMessageTime" 1600;
BA_ "NmAsrTimeoutTime" 2000;
BA_ "NmAsrWaitBusSleepTime" 2000;
BA_ "NmType" "NmAsr";
BA_ "Manufacturer" "vector";
BA_ "DBName" "ChassisCAN";
BA_ "NmAsrNodeIdentifier" BU_ RS 40;
BA_ "NmAsrCanMsgReducedTime" BU_ RS 250;
BA_ "GenMsgCycleTime" BO_ 482 20;
BA_ "GenMsgSendType" BO_ 482 0;
BA_ "GenMsgCycleTime" BO_ 644 100;
BA_ "GenMsgSendType" BO_ 644 0;
BA_ "GenMsgCycleTime" BO_ 646 100;
BA_ "GenMsgSendType" BO_ 646 0;
BA_ "GenMsgSendType" BO_ 645 0;
BA_ "GenMsgCycleTime" BO_ 645 100;
BA_ "GenMsgCycleTime" BO_ 496 200;
BA_ "GenMsgSendType" BO_ 496 0;
BA_ "GenMsgStartDelayTime" BO_ 1518 45;
BA_ "GenMsgSendType" BO_ 1518 0;
BA_ "GenMsgCycleTime" BO_ 1518 50;
BA_ "GenMsgStartDelayTime" BO_ 1501 40;
BA_ "GenMsgSendType" BO_ 1501 0;
BA_ "GenMsgCycleTime" BO_ 1501 50;
BA_ "GenMsgStartDelayTime" BO_ 1515 35;
BA_ "GenMsgSendType" BO_ 1515 0;
BA_ "GenMsgCycleTime" BO_ 1515 50;
BA_ "GenMsgStartDelayTime" BO_ 1498 30;
BA_ "GenMsgSendType" BO_ 1498 0;
BA_ "GenMsgCycleTime" BO_ 1498 50;
BA_ "GenMsgStartDelayTime" BO_ 1512 25;
BA_ "GenMsgSendType" BO_ 1512 0;
BA_ "GenMsgCycleTime" BO_ 1512 50;
BA_ "GenMsgStartDelayTime" BO_ 1495 20;
BA_ "GenMsgSendType" BO_ 1495 0;
BA_ "GenMsgCycleTime" BO_ 1495 50;
BA_ "GenMsgStartDelayTime" BO_ 1509 15;
BA_ "GenMsgSendType" BO_ 1509 0;
BA_ "GenMsgCycleTime" BO_ 1509 50;
BA_ "GenMsgStartDelayTime" BO_ 1492 10;
BA_ "GenMsgSendType" BO_ 1492 0;
BA_ "GenMsgCycleTime" BO_ 1492 50;
BA_ "GenMsgStartDelayTime" BO_ 1506 5;
BA_ "GenMsgSendType" BO_ 1506 0;
BA_ "GenMsgCycleTime" BO_ 1506 50;
BA_ "GenMsgSendType" BO_ 1489 0;
BA_ "GenMsgCycleTime" BO_ 1489 50;
BA_ "GenMsgStartDelayTime" BO_ 1453 45;
BA_ "GenMsgSendType" BO_ 1453 0;
BA_ "GenMsgCycleTime" BO_ 1453 50;
BA_ "GenMsgStartDelayTime" BO_ 1452 45;
BA_ "GenMsgSendType" BO_ 1452 0;
BA_ "GenMsgCycleTime" BO_ 1452 50;
BA_ "GenMsgStartDelayTime" BO_ 1451 45;
BA_ "GenMsgSendType" BO_ 1451 0;
BA_ "GenMsgCycleTime" BO_ 1451 50;
BA_ "GenMsgStartDelayTime" BO_ 1450 40;
BA_ "GenMsgSendType" BO_ 1450 0;
BA_ "GenMsgCycleTime" BO_ 1450 50;
BA_ "GenMsgStartDelayTime" BO_ 1449 40;
BA_ "GenMsgSendType" BO_ 1449 0;
BA_ "GenMsgCycleTime" BO_ 1449 50;
BA_ "GenMsgStartDelayTime" BO_ 1448 40;
BA_ "GenMsgSendType" BO_ 1448 0;
BA_ "GenMsgCycleTime" BO_ 1448 50;
BA_ "GenMsgStartDelayTime" BO_ 1447 35;
BA_ "GenMsgSendType" BO_ 1447 0;
BA_ "GenMsgCycleTime" BO_ 1447 50;
BA_ "GenMsgStartDelayTime" BO_ 1446 35;
BA_ "GenMsgSendType" BO_ 1446 0;
BA_ "GenMsgCycleTime" BO_ 1446 50;
BA_ "GenMsgStartDelayTime" BO_ 1445 35;
BA_ "GenMsgSendType" BO_ 1445 0;
BA_ "GenMsgCycleTime" BO_ 1445 50;
BA_ "GenMsgStartDelayTime" BO_ 1444 30;
BA_ "GenMsgSendType" BO_ 1444 0;
BA_ "GenMsgCycleTime" BO_ 1444 50;
BA_ "GenMsgStartDelayTime" BO_ 1443 30;
BA_ "GenMsgSendType" BO_ 1443 0;
BA_ "GenMsgCycleTime" BO_ 1443 50;
BA_ "GenMsgStartDelayTime" BO_ 1442 30;
BA_ "GenMsgSendType" BO_ 1442 0;
BA_ "GenMsgCycleTime" BO_ 1442 50;
BA_ "GenMsgStartDelayTime" BO_ 1441 25;
BA_ "GenMsgSendType" BO_ 1441 0;
BA_ "GenMsgCycleTime" BO_ 1441 50;
BA_ "GenMsgStartDelayTime" BO_ 1440 25;
BA_ "GenMsgSendType" BO_ 1440 0;
BA_ "GenMsgCycleTime" BO_ 1440 50;
BA_ "GenMsgStartDelayTime" BO_ 1439 25;
BA_ "GenMsgSendType" BO_ 1439 0;
BA_ "GenMsgCycleTime" BO_ 1439 50;
BA_ "GenMsgStartDelayTime" BO_ 1438 20;
BA_ "GenMsgSendType" BO_ 1438 0;
BA_ "GenMsgCycleTime" BO_ 1438 50;
BA_ "GenMsgStartDelayTime" BO_ 1437 20;
BA_ "GenMsgSendType" BO_ 1437 0;
BA_ "GenMsgCycleTime" BO_ 1437 50;
BA_ "GenMsgStartDelayTime" BO_ 1436 20;
BA_ "GenMsgSendType" BO_ 1436 0;
BA_ "GenMsgCycleTime" BO_ 1436 50;
BA_ "GenMsgStartDelayTime" BO_ 1435 15;
BA_ "GenMsgSendType" BO_ 1435 0;
BA_ "GenMsgCycleTime" BO_ 1435 50;
BA_ "GenMsgStartDelayTime" BO_ 1434 15;
BA_ "GenMsgSendType" BO_ 1434 0;
BA_ "GenMsgCycleTime" BO_ 1434 50;
BA_ "GenMsgStartDelayTime" BO_ 1433 15;
BA_ "GenMsgSendType" BO_ 1433 0;
BA_ "GenMsgCycleTime" BO_ 1433 50;
BA_ "GenMsgStartDelayTime" BO_ 1432 10;
BA_ "GenMsgSendType" BO_ 1432 0;
BA_ "GenMsgCycleTime" BO_ 1432 50;
BA_ "GenMsgStartDelayTime" BO_ 1431 10;
BA_ "GenMsgSendType" BO_ 1431 0;
BA_ "GenMsgCycleTime" BO_ 1431 50;
BA_ "GenMsgStartDelayTime" BO_ 1430 10;
BA_ "GenMsgSendType" BO_ 1430 0;
BA_ "GenMsgCycleTime" BO_ 1430 50;
BA_ "GenMsgStartDelayTime" BO_ 1429 5;
BA_ "GenMsgSendType" BO_ 1429 0;
BA_ "GenMsgCycleTime" BO_ 1429 50;
BA_ "GenMsgStartDelayTime" BO_ 1428 5;
BA_ "GenMsgSendType" BO_ 1428 0;
BA_ "GenMsgCycleTime" BO_ 1428 50;
BA_ "GenMsgStartDelayTime" BO_ 1427 5;
BA_ "GenMsgSendType" BO_ 1427 0;
BA_ "GenMsgCycleTime" BO_ 1427 50;
BA_ "GenMsgSendType" BO_ 1426 0;
BA_ "GenMsgCycleTime" BO_ 1426 50;
BA_ "GenMsgSendType" BO_ 1425 0;
BA_ "GenMsgCycleTime" BO_ 1425 50;
BA_ "GenMsgSendType" BO_ 1424 0;
BA_ "GenMsgCycleTime" BO_ 1424 50;
BA_ "DiagRequest" BO_ 1937 1;
BA_ "DiagResponse" BO_ 1945 1;
BA_ "GenMsgStartDelayTime" BO_ 1502 45;
BA_ "GenMsgCycleTime" BO_ 1502 50;
BA_ "GenMsgSendType" BO_ 1502 0;
BA_ "GenMsgStartDelayTime" BO_ 1516 40;
BA_ "GenMsgCycleTime" BO_ 1516 50;
BA_ "GenMsgSendType" BO_ 1516 0;
BA_ "GenMsgStartDelayTime" BO_ 1499 35;
BA_ "GenMsgCycleTime" BO_ 1499 50;
BA_ "GenMsgSendType" BO_ 1499 0;
BA_ "GenMsgStartDelayTime" BO_ 1513 30;
BA_ "GenMsgCycleTime" BO_ 1513 50;
BA_ "GenMsgSendType" BO_ 1513 0;
BA_ "GenMsgStartDelayTime" BO_ 1496 25;
BA_ "GenMsgCycleTime" BO_ 1496 50;
BA_ "GenMsgSendType" BO_ 1496 0;
BA_ "GenMsgStartDelayTime" BO_ 1510 20;
BA_ "GenMsgCycleTime" BO_ 1510 50;
BA_ "GenMsgSendType" BO_ 1510 0;
BA_ "GenMsgStartDelayTime" BO_ 1493 15;
BA_ "GenMsgCycleTime" BO_ 1493 50;
BA_ "GenMsgSendType" BO_ 1493 0;
BA_ "GenMsgStartDelayTime" BO_ 1507 10;
BA_ "GenMsgCycleTime" BO_ 1507 50;
BA_ "GenMsgSendType" BO_ 1507 0;
BA_ "GenMsgStartDelayTime" BO_ 1490 5;
BA_ "GenMsgCycleTime" BO_ 1490 50;
BA_ "GenMsgSendType" BO_ 1490 0;
BA_ "GenMsgCycleTime" BO_ 1504 50;
BA_ "GenMsgSendType" BO_ 1504 0;
BA_ "GenMsgStartDelayTime" BO_ 1389 45;
BA_ "GenMsgCycleTime" BO_ 1389 50;
BA_ "GenMsgSendType" BO_ 1389 0;
BA_ "GenMsgStartDelayTime" BO_ 1388 45;
BA_ "GenMsgCycleTime" BO_ 1388 50;
BA_ "GenMsgSendType" BO_ 1388 0;
BA_ "GenMsgStartDelayTime" BO_ 1387 45;
BA_ "GenMsgCycleTime" BO_ 1387 50;
BA_ "GenMsgSendType" BO_ 1387 0;
BA_ "GenMsgStartDelayTime" BO_ 1386 40;
BA_ "GenMsgCycleTime" BO_ 1386 50;
BA_ "GenMsgSendType" BO_ 1386 0;
BA_ "GenMsgStartDelayTime" BO_ 1385 40;
BA_ "GenMsgCycleTime" BO_ 1385 50;
BA_ "GenMsgSendType" BO_ 1385 0;
BA_ "GenMsgStartDelayTime" BO_ 1384 40;
BA_ "GenMsgCycleTime" BO_ 1384 50;
BA_ "GenMsgSendType" BO_ 1384 0;
BA_ "GenMsgStartDelayTime" BO_ 1383 35;
BA_ "GenMsgCycleTime" BO_ 1383 50;
BA_ "GenMsgSendType" BO_ 1383 0;
BA_ "GenMsgStartDelayTime" BO_ 1382 35;
BA_ "GenMsgCycleTime" BO_ 1382 50;
BA_ "GenMsgSendType" BO_ 1382 0;
BA_ "GenMsgStartDelayTime" BO_ 1381 35;
BA_ "GenMsgCycleTime" BO_ 1381 50;
BA_ "GenMsgSendType" BO_ 1381 0;
BA_ "GenMsgStartDelayTime" BO_ 1380 30;
BA_ "GenMsgCycleTime" BO_ 1380 50;
BA_ "GenMsgSendType" BO_ 1380 0;
BA_ "GenMsgStartDelayTime" BO_ 1379 30;
BA_ "GenMsgCycleTime" BO_ 1379 50;
BA_ "GenMsgSendType" BO_ 1379 0;
BA_ "GenMsgStartDelayTime" BO_ 1378 30;
BA_ "GenMsgCycleTime" BO_ 1378 50;
BA_ "GenMsgSendType" BO_ 1378 0;
BA_ "GenMsgStartDelayTime" BO_ 1377 25;
BA_ "GenMsgCycleTime" BO_ 1377 50;
BA_ "GenMsgSendType" BO_ 1377 0;
BA_ "GenMsgStartDelayTime" BO_ 1376 25;
BA_ "GenMsgCycleTime" BO_ 1376 50;
BA_ "GenMsgSendType" BO_ 1376 0;
BA_ "GenMsgStartDelayTime" BO_ 1375 25;
BA_ "GenMsgCycleTime" BO_ 1375 50;
BA_ "GenMsgSendType" BO_ 1375 0;
BA_ "GenMsgStartDelayTime" BO_ 1374 20;
BA_ "GenMsgCycleTime" BO_ 1374 50;
BA_ "GenMsgSendType" BO_ 1374 0;
BA_ "GenMsgStartDelayTime" BO_ 1373 20;
BA_ "GenMsgCycleTime" BO_ 1373 50;
BA_ "GenMsgSendType" BO_ 1373 0;
BA_ "GenMsgStartDelayTime" BO_ 1372 20;
BA_ "GenMsgCycleTime" BO_ 1372 50;
BA_ "GenMsgSendType" BO_ 1372 0;
BA_ "GenMsgStartDelayTime" BO_ 1371 15;
BA_ "GenMsgCycleTime" BO_ 1371 50;
BA_ "GenMsgSendType" BO_ 1371 0;
BA_ "GenMsgStartDelayTime" BO_ 1370 15;
BA_ "GenMsgCycleTime" BO_ 1370 50;
BA_ "GenMsgSendType" BO_ 1370 0;
BA_ "GenMsgStartDelayTime" BO_ 1369 15;
BA_ "GenMsgCycleTime" BO_ 1369 50;
BA_ "GenMsgSendType" BO_ 1369 0;
BA_ "GenMsgStartDelayTime" BO_ 1368 10;
BA_ "GenMsgCycleTime" BO_ 1368 50;
BA_ "GenMsgSendType" BO_ 1368 0;
BA_ "GenMsgStartDelayTime" BO_ 1367 10;
BA_ "GenMsgCycleTime" BO_ 1367 50;
BA_ "GenMsgSendType" BO_ 1367 0;
BA_ "GenMsgStartDelayTime" BO_ 1366 10;
BA_ "GenMsgCycleTime" BO_ 1366 50;
BA_ "GenMsgSendType" BO_ 1366 0;
BA_ "GenMsgStartDelayTime" BO_ 1365 5;
BA_ "GenMsgCycleTime" BO_ 1365 50;
BA_ "GenMsgSendType" BO_ 1365 0;
BA_ "GenMsgStartDelayTime" BO_ 1364 5;
BA_ "GenMsgCycleTime" BO_ 1364 50;
BA_ "GenMsgSendType" BO_ 1364 0;
BA_ "GenMsgStartDelayTime" BO_ 1363 5;
BA_ "GenMsgCycleTime" BO_ 1363 50;
BA_ "GenMsgSendType" BO_ 1363 0;
BA_ "GenMsgCycleTime" BO_ 1362 50;
BA_ "GenMsgSendType" BO_ 1362 0;
BA_ "GenMsgCycleTime" BO_ 1361 50;
BA_ "GenMsgSendType" BO_ 1361 0;
BA_ "GenMsgStartDelayTime" BO_ 1517 45;
BA_ "GenMsgSendType" BO_ 1517 0;
BA_ "GenMsgCycleTime" BO_ 1517 50;
BA_ "GenMsgStartDelayTime" BO_ 1500 40;
BA_ "GenMsgSendType" BO_ 1500 0;
BA_ "GenMsgCycleTime" BO_ 1500 50;
BA_ "GenMsgStartDelayTime" BO_ 1514 35;
BA_ "GenMsgSendType" BO_ 1514 0;
BA_ "GenMsgCycleTime" BO_ 1514 50;
BA_ "GenMsgStartDelayTime" BO_ 1497 30;
BA_ "GenMsgSendType" BO_ 1497 0;
BA_ "GenMsgCycleTime" BO_ 1497 50;
BA_ "GenMsgStartDelayTime" BO_ 1511 25;
BA_ "GenMsgSendType" BO_ 1511 0;
BA_ "GenMsgCycleTime" BO_ 1511 50;
BA_ "GenMsgStartDelayTime" BO_ 1494 20;
BA_ "GenMsgSendType" BO_ 1494 0;
BA_ "GenMsgCycleTime" BO_ 1494 50;
BA_ "GenMsgStartDelayTime" BO_ 1508 15;
BA_ "GenMsgSendType" BO_ 1508 0;
BA_ "GenMsgCycleTime" BO_ 1508 50;
BA_ "GenMsgStartDelayTime" BO_ 1491 10;
BA_ "GenMsgSendType" BO_ 1491 0;
BA_ "GenMsgCycleTime" BO_ 1491 50;
BA_ "GenMsgStartDelayTime" BO_ 1505 5;
BA_ "GenMsgSendType" BO_ 1505 0;
BA_ "GenMsgCycleTime" BO_ 1505 50;
BA_ "GenMsgSendType" BO_ 1488 0;
BA_ "GenMsgCycleTime" BO_ 1488 50;
BA_ "GenMsgStartDelayTime" BO_ 1341 45;
BA_ "GenMsgSendType" BO_ 1341 0;
BA_ "GenMsgCycleTime" BO_ 1341 50;
BA_ "GenMsgStartDelayTime" BO_ 1340 45;
BA_ "GenMsgSendType" BO_ 1340 0;
BA_ "GenMsgCycleTime" BO_ 1340 50;
BA_ "GenMsgStartDelayTime" BO_ 1339 45;
BA_ "GenMsgSendType" BO_ 1339 0;
BA_ "GenMsgCycleTime" BO_ 1339 50;
BA_ "GenMsgStartDelayTime" BO_ 1338 40;
BA_ "GenMsgSendType" BO_ 1338 0;
BA_ "GenMsgCycleTime" BO_ 1338 50;
BA_ "GenMsgStartDelayTime" BO_ 1337 40;
BA_ "GenMsgSendType" BO_ 1337 0;
BA_ "GenMsgCycleTime" BO_ 1337 50;
BA_ "GenMsgStartDelayTime" BO_ 1336 40;
BA_ "GenMsgSendType" BO_ 1336 0;
BA_ "GenMsgCycleTime" BO_ 1336 50;
BA_ "GenMsgStartDelayTime" BO_ 1335 35;
BA_ "GenMsgSendType" BO_ 1335 0;
BA_ "GenMsgCycleTime" BO_ 1335 50;
BA_ "GenMsgStartDelayTime" BO_ 1334 35;
BA_ "GenMsgSendType" BO_ 1334 0;
BA_ "GenMsgCycleTime" BO_ 1334 50;
BA_ "GenMsgStartDelayTime" BO_ 1333 35;
BA_ "GenMsgSendType" BO_ 1333 0;
BA_ "GenMsgCycleTime" BO_ 1333 50;
BA_ "GenMsgStartDelayTime" BO_ 1332 30;
BA_ "GenMsgSendType" BO_ 1332 0;
BA_ "GenMsgCycleTime" BO_ 1332 50;
BA_ "GenMsgStartDelayTime" BO_ 1331 30;
BA_ "GenMsgSendType" BO_ 1331 0;
BA_ "GenMsgCycleTime" BO_ 1331 50;
BA_ "GenMsgStartDelayTime" BO_ 1330 30;
BA_ "GenMsgSendType" BO_ 1330 0;
BA_ "GenMsgCycleTime" BO_ 1330 50;
BA_ "GenMsgStartDelayTime" BO_ 1329 25;
BA_ "GenMsgSendType" BO_ 1329 0;
BA_ "GenMsgCycleTime" BO_ 1329 50;
BA_ "GenMsgStartDelayTime" BO_ 1328 25;
BA_ "GenMsgSendType" BO_ 1328 0;
BA_ "GenMsgCycleTime" BO_ 1328 50;
BA_ "GenMsgStartDelayTime" BO_ 1327 25;
BA_ "GenMsgSendType" BO_ 1327 0;
BA_ "GenMsgCycleTime" BO_ 1327 50;
BA_ "GenMsgStartDelayTime" BO_ 1326 20;
BA_ "GenMsgSendType" BO_ 1326 0;
BA_ "GenMsgCycleTime" BO_ 1326 50;
BA_ "GenMsgStartDelayTime" BO_ 1325 20;
BA_ "GenMsgSendType" BO_ 1325 0;
BA_ "GenMsgCycleTime" BO_ 1325 50;
BA_ "GenMsgStartDelayTime" BO_ 1324 20;
BA_ "GenMsgSendType" BO_ 1324 0;
BA_ "GenMsgCycleTime" BO_ 1324 50;
BA_ "GenMsgStartDelayTime" BO_ 1323 15;
BA_ "GenMsgSendType" BO_ 1323 0;
BA_ "GenMsgCycleTime" BO_ 1323 50;
BA_ "GenMsgStartDelayTime" BO_ 1322 15;
BA_ "GenMsgSendType" BO_ 1322 0;
BA_ "GenMsgCycleTime" BO_ 1322 50;
BA_ "GenMsgStartDelayTime" BO_ 1321 15;
BA_ "GenMsgSendType" BO_ 1321 0;
BA_ "GenMsgCycleTime" BO_ 1321 50;
BA_ "GenMsgStartDelayTime" BO_ 1320 10;
BA_ "GenMsgSendType" BO_ 1320 0;
BA_ "GenMsgCycleTime" BO_ 1320 50;
BA_ "GenMsgStartDelayTime" BO_ 1319 10;
BA_ "GenMsgSendType" BO_ 1319 0;
BA_ "GenMsgCycleTime" BO_ 1319 50;
BA_ "GenMsgStartDelayTime" BO_ 1318 10;
BA_ "GenMsgSendType" BO_ 1318 0;
BA_ "GenMsgCycleTime" BO_ 1318 50;
BA_ "GenMsgStartDelayTime" BO_ 1317 5;
BA_ "GenMsgSendType" BO_ 1317 0;
BA_ "GenMsgCycleTime" BO_ 1317 50;
BA_ "GenMsgStartDelayTime" BO_ 1316 5;
BA_ "GenMsgSendType" BO_ 1316 0;
BA_ "GenMsgCycleTime" BO_ 1316 50;
BA_ "GenMsgStartDelayTime" BO_ 1315 5;
BA_ "GenMsgSendType" BO_ 1315 0;
BA_ "GenMsgCycleTime" BO_ 1315 50;
BA_ "GenMsgSendType" BO_ 1314 0;
BA_ "GenMsgCycleTime" BO_ 1314 50;
BA_ "GenMsgSendType" BO_ 1313 0;
BA_ "GenMsgCycleTime" BO_ 1313 50;
BA_ "GenMsgSendType" BO_ 1360 0;
BA_ "GenMsgCycleTime" BO_ 1360 50;
BA_ "GenMsgSendType" BO_ 1312 0;
BA_ "GenMsgCycleTime" BO_ 1312 50;
BA_ "GenMsgSendType" BO_ 1472 0;
BA_ "GenMsgCycleTime" BO_ 1472 50;
BA_ "GenMsgILSupport" BO_ 1074 0;
BA_ "NmAsrMessage" BO_ 1074 1;
BA_ "GenMsgILSupport" BO_ 2015 0;
BA_ "DiagRequest" BO_ 2015 1;
BA_ "DiagState" BO_ 2015 1;
BA_ "GenMsgSendType" BO_ 357 0;
BA_ "GenMsgCycleTime" BO_ 357 20;
BA_ "GenMsgSendType" BO_ 304 0;
BA_ "GenMsgCycleTime" BO_ 304 20;
BA_ "GenMsgSendType" BO_ 305 0;
BA_ "GenMsgCycleTime" BO_ 305 20;
BA_ "GenMsgSendType" BO_ 224 0;
BA_ "GenMsgCycleTime" BO_ 224 10;
BA_ "GenMsgSendType" BO_ 293 0;
BA_ "GenMsgCycleTime" BO_ 293 20;
BA_ "GenMsgSendType" BO_ 133 0;
BA_ "GenMsgCycleTime" BO_ 133 10;
BA_ "GenMsgSendType" BO_ 275 0;
BA_ "GenMsgCycleTime" BO_ 275 20;
BA_ "GenMsgSendType" BO_ 1009 0;
BA_ "GenMsgCycleTime" BO_ 1009 1000;
BA_ "CustomizedSignalType" SG_ 482 PEPS_Message_Sts_Checksum 1;
BA_ "CustomizedSignalType" SG_ 482 PEPS_Message_Sts_AliveCounter 2;
BA_ "CustomizedSignalType" SG_ 496 BCM_LightChimeReq_AliveCounter 2;
BA_ "CustomizedSignalType" SG_ 496 BCM_LightChimeReq_CheckSum 1;
BA_ "GenSigStartValue" SG_ 1518 RS_Detn14_Elev 15;
BA_ "CustomizedSignalType" SG_ 1518 RS_Detn14_Msg02_CheckSum 1;
BA_ "CustomizedSignalType" SG_ 1518 RS_Detn14_Msg02_AliveCounter 2;
BA_ "GenSigStartValue" SG_ 1518 RS_Detn14_MotnSts 3;
BA_ "CustomizedSignalType" SG_ 1501 RS_Detn13_Msg01_CheckSum 1;
BA_ "CustomizedSignalType" SG_ 1501 RS_Detn13_Msg01_AliveCounter 2;
BA_ "GenSigStartValue" SG_ 1501 RS_Detn13_PosY 8193.36337566571;
BA_ "GenSigStartValue" SG_ 1501 RS_Detn13_PosX 8193.36337566571;
BA_ "GenSigStartValue" SG_ 1515 RS_Detn11_Elev 15;
BA_ "CustomizedSignalType" SG_ 1515 RS_Detn11_Msg02_CheckSum 1;
BA_ "CustomizedSignalType" SG_ 1515 RS_Detn11_Msg02_AliveCounter 2;
BA_ "GenSigStartValue" SG_ 1515 RS_Detn11_MotnSts 3;
BA_ "CustomizedSignalType" SG_ 1498 RS_Detn10_Msg01_CheckSum 1;
BA_ "CustomizedSignalType" SG_ 1498 RS_Detn10_Msg01_AliveCounter 2;
BA_ "GenSigStartValue" SG_ 1498 RS_Detn10_PosY 8193.36337566571;
BA_ "GenSigStartValue" SG_ 1498 RS_Detn10_PosX 8193.36337566571;
BA_ "GenSigStartValue" SG_ 1512 RS_Detn08_Elev 15;
BA_ "CustomizedSignalType" SG_ 1512 RS_Detn08_Msg02_CheckSum 1;
BA_ "CustomizedSignalType" SG_ 1512 RS_Detn08_Msg02_AliveCounter 2;
BA_ "GenSigStartValue" SG_ 1512 RS_Detn08_MotnSts 3;
BA_ "CustomizedSignalType" SG_ 1495 RS_Detn07_Msg01_CheckSum 1;
BA_ "CustomizedSignalType" SG_ 1495 RS_Detn07_Msg01_AliveCounter 2;
BA_ "GenSigStartValue" SG_ 1495 RS_Detn07_PosY 8193.36337566571;
BA_ "GenSigStartValue" SG_ 1495 RS_Detn07_PosX 8193.36337566571;
BA_ "GenSigStartValue" SG_ 1509 RS_Detn05_Elev 15;
BA_ "CustomizedSignalType" SG_ 1509 RS_Detn05_Msg02_CheckSum 1;
BA_ "CustomizedSignalType" SG_ 1509 RS_Detn05_Msg02_AliveCounter 2;
BA_ "GenSigStartValue" SG_ 1509 RS_Detn05_MotnSts 3;
BA_ "CustomizedSignalType" SG_ 1492 RS_Detn04_Msg01_CheckSum 1;
BA_ "CustomizedSignalType" SG_ 1492 RS_Detn04_Msg01_AliveCounter 2;
BA_ "GenSigStartValue" SG_ 1492 RS_Detn04_PosY 8193.36337566571;
BA_ "GenSigStartValue" SG_ 1492 RS_Detn04_PosX 8193.36337566571;
BA_ "GenSigStartValue" SG_ 1506 RS_Detn02_Elev 15;
BA_ "CustomizedSignalType" SG_ 1506 RS_Detn02_Msg02_CheckSum 1;
BA_ "CustomizedSignalType" SG_ 1506 RS_Detn02_Msg02_AliveCounter 2;
BA_ "GenSigStartValue" SG_ 1506 RS_Detn02_MotnSts 3;
BA_ "CustomizedSignalType" SG_ 1489 RS_Detn01_Msg01_CheckSum 1;
BA_ "CustomizedSignalType" SG_ 1489 RS_Detn01_Msg01_AliveCounter 2;
BA_ "GenSigStartValue" SG_ 1489 RS_Detn01_PosY 8193.36337566571;
BA_ "GenSigStartValue" SG_ 1489 RS_Detn01_PosX 8193.36337566571;
BA_ "CustomizedSignalType" SG_ 1453 RS_Obj29_Msg03_CheckSum 1;
BA_ "CustomizedSignalType" SG_ 1453 RS_Obj29_Msg03_AliveCounter 2;
BA_ "CustomizedSignalType" SG_ 1452 RS_Obj28_Msg03_CheckSum 1;
BA_ "CustomizedSignalType" SG_ 1452 RS_Obj28_Msg03_AliveCounter 2;
BA_ "CustomizedSignalType" SG_ 1451 RS_Obj27_Msg03_CheckSum 1;
BA_ "CustomizedSignalType" SG_ 1451 RS_Obj27_Msg03_AliveCounter 2;
BA_ "CustomizedSignalType" SG_ 1450 RS_Obj26_Msg03_CheckSum 1;
BA_ "CustomizedSignalType" SG_ 1450 RS_Obj26_Msg03_AliveCounter 2;
BA_ "CustomizedSignalType" SG_ 1449 RS_Obj25_Msg03_CheckSum 1;
BA_ "CustomizedSignalType" SG_ 1449 RS_Obj25_Msg03_AliveCounter 2;
BA_ "CustomizedSignalType" SG_ 1448 RS_Obj24_Msg03_CheckSum 1;
BA_ "CustomizedSignalType" SG_ 1448 RS_Obj24_Msg03_AliveCounter 2;
BA_ "CustomizedSignalType" SG_ 1447 RS_Obj23_Msg03_CheckSum 1;
BA_ "CustomizedSignalType" SG_ 1447 RS_Obj23_Msg03_AliveCounter 2;
BA_ "CustomizedSignalType" SG_ 1446 RS_Obj22_Msg03_CheckSum 1;
BA_ "CustomizedSignalType" SG_ 1446 RS_Obj22_Msg03_AliveCounter 2;
BA_ "CustomizedSignalType" SG_ 1445 RS_Obj21_Msg03_CheckSum 1;
BA_ "CustomizedSignalType" SG_ 1445 RS_Obj21_Msg03_AliveCounter 2;
BA_ "CustomizedSignalType" SG_ 1444 RS_Obj20_Msg03_CheckSum 1;
BA_ "CustomizedSignalType" SG_ 1444 RS_Obj20_Msg03_AliveCounter 2;
BA_ "CustomizedSignalType" SG_ 1443 RS_Obj19_Msg03_CheckSum 1;
BA_ "CustomizedSignalType" SG_ 1443 RS_Obj19_Msg03_AliveCounter 2;
BA_ "CustomizedSignalType" SG_ 1442 RS_Obj18_Msg03_CheckSum 1;
BA_ "CustomizedSignalType" SG_ 1442 RS_Obj18_Msg03_AliveCounter 2;
BA_ "CustomizedSignalType" SG_ 1441 RS_Obj17_Msg03_CheckSum 1;
BA_ "CustomizedSignalType" SG_ 1441 RS_Obj17_Msg03_AliveCounter 2;
BA_ "CustomizedSignalType" SG_ 1440 RS_Obj16_Msg03_CheckSum 1;
BA_ "CustomizedSignalType" SG_ 1440 RS_Obj16_Msg03_AliveCounter 2;
BA_ "CustomizedSignalType" SG_ 1439 RS_Obj15_Msg03_CheckSum 1;
BA_ "CustomizedSignalType" SG_ 1439 RS_Obj15_Msg03_AliveCounter 2;
BA_ "CustomizedSignalType" SG_ 1438 RS_Obj14_Msg03_CheckSum 1;
BA_ "CustomizedSignalType" SG_ 1438 RS_Obj14_Msg03_AliveCounter 2;
BA_ "CustomizedSignalType" SG_ 1437 RS_Obj13_Msg03_CheckSum 1;
BA_ "CustomizedSignalType" SG_ 1437 RS_Obj13_Msg03_AliveCounter 2;
BA_ "CustomizedSignalType" SG_ 1436 RS_Obj12_Msg03_CheckSum 1;
BA_ "CustomizedSignalType" SG_ 1436 RS_Obj12_Msg03_AliveCounter 2;
BA_ "CustomizedSignalType" SG_ 1435 RS_Obj11_Msg03_CheckSum 1;
BA_ "CustomizedSignalType" SG_ 1435 RS_Obj11_Msg03_AliveCounter 2;
BA_ "CustomizedSignalType" SG_ 1434 RS_Obj10_Msg03_CheckSum 1;
BA_ "CustomizedSignalType" SG_ 1434 RS_Obj10_Msg03_AliveCounter 2;
BA_ "CustomizedSignalType" SG_ 1433 RS_Obj09_Msg03_CheckSum 1;
BA_ "CustomizedSignalType" SG_ 1433 RS_Obj09_Msg03_AliveCounter 2;
BA_ "CustomizedSignalType" SG_ 1432 RS_Obj08_Msg03_CheckSum 1;
BA_ "CustomizedSignalType" SG_ 1432 RS_Obj08_Msg03_AliveCounter 2;
BA_ "CustomizedSignalType" SG_ 1431 RS_Obj07_Msg03_CheckSum 1;
BA_ "CustomizedSignalType" SG_ 1431 RS_Obj07_Msg03_AliveCounter 2;
BA_ "CustomizedSignalType" SG_ 1430 RS_Obj06_Msg03_CheckSum 1;
BA_ "CustomizedSignalType" SG_ 1430 RS_Obj06_Msg03_AliveCounter 2;
BA_ "CustomizedSignalType" SG_ 1429 RS_Obj05_Msg03_CheckSum 1;
BA_ "CustomizedSignalType" SG_ 1429 RS_Obj05_Msg03_AliveCounter 2;
BA_ "CustomizedSignalType" SG_ 1428 RS_Obj04_Msg03_CheckSum 1;
BA_ "CustomizedSignalType" SG_ 1428 RS_Obj04_Msg03_AliveCounter 2;
BA_ "CustomizedSignalType" SG_ 1427 RS_Obj03_Msg03_CheckSum 1;
BA_ "CustomizedSignalType" SG_ 1427 RS_Obj03_Msg03_AliveCounter 2;
BA_ "CustomizedSignalType" SG_ 1426 RS_Obj02_Msg03_CheckSum 1;
BA_ "CustomizedSignalType" SG_ 1426 RS_Obj02_Msg03_AliveCounter 2;
BA_ "CustomizedSignalType" SG_ 1425 RS_Obj01_Msg03_CheckSum 1;
BA_ "CustomizedSignalType" SG_ 1425 RS_Obj01_Msg03_AliveCounter 2;
BA_ "CustomizedSignalType" SG_ 1424 RS_Obj00_Msg03_CheckSum 1;
BA_ "CustomizedSignalType" SG_ 1424 RS_Obj00_Msg03_AliveCounter 2;
BA_ "GenSigSendType" SG_ 1937 DiagReq_Byte7 2;
BA_ "GenSigSendType" SG_ 1937 DiagReq_Byte6 2;
BA_ "GenSigSendType" SG_ 1937 DiagReq_Byte5 2;
BA_ "GenSigSendType" SG_ 1937 DiagReq_Byte4 2;
BA_ "GenSigSendType" SG_ 1937 DiagReq_Byte3 2;
BA_ "GenSigSendType" SG_ 1937 DiagReq_Byte2 2;
BA_ "GenSigSendType" SG_ 1937 DiagReq_Byte1 2;
BA_ "GenSigSendType" SG_ 1937 DiagReq_Byte0 2;
BA_ "GenSigSendType" SG_ 1945 DiagResp_Byte7 2;
BA_ "GenSigSendType" SG_ 1945 DiagResp_Byte6 2;
BA_ "GenSigSendType" SG_ 1945 DiagResp_Byte5 2;
BA_ "GenSigSendType" SG_ 1945 DiagResp_Byte4 2;
BA_ "GenSigSendType" SG_ 1945 DiagResp_Byte3 2;
BA_ "GenSigSendType" SG_ 1945 DiagResp_Byte2 2;
BA_ "GenSigSendType" SG_ 1945 DiagResp_Byte1 2;
BA_ "GenSigSendType" SG_ 1945 DiagResp_Byte0 2;
BA_ "CustomizedSignalType" SG_ 1502 RS_Detn14_Msg01_CheckSum 1;
BA_ "CustomizedSignalType" SG_ 1502 RS_Detn14_Msg01_AliveCounter 2;
BA_ "GenSigStartValue" SG_ 1502 RS_Detn14_PosY 8193.36337566571;
BA_ "GenSigStartValue" SG_ 1502 RS_Detn14_PosX 8193.36337566571;
BA_ "GenSigStartValue" SG_ 1516 RS_Detn12_Elev 15;
BA_ "CustomizedSignalType" SG_ 1516 RS_Detn12_Msg02_AliveCounter 2;
BA_ "CustomizedSignalType" SG_ 1516 RS_Detn12_Msg02_CheckSum 1;
BA_ "GenSigStartValue" SG_ 1516 RS_Detn12_MotnSts 3;
BA_ "CustomizedSignalType" SG_ 1499 RS_Detn11_Msg01_CheckSum 1;
BA_ "CustomizedSignalType" SG_ 1499 RS_Detn11_Msg01_AliveCounter 2;
BA_ "GenSigStartValue" SG_ 1499 RS_Detn11_PosY 8193.36337566571;
BA_ "GenSigStartValue" SG_ 1499 RS_Detn11_PosX 8193.36337566571;
BA_ "GenSigStartValue" SG_ 1513 RS_Detn09_Elev 15;
BA_ "CustomizedSignalType" SG_ 1513 RS_Detn09_Msg02_CheckSum 1;
BA_ "CustomizedSignalType" SG_ 1513 RS_Detn09_Msg02_AliveCounter 2;
BA_ "GenSigStartValue" SG_ 1513 RS_Detn09_MotnSts 3;
BA_ "CustomizedSignalType" SG_ 1496 RS_Detn08_Msg01_CheckSum 1;
BA_ "CustomizedSignalType" SG_ 1496 RS_Detn08_Msg01_AliveCounter 2;
BA_ "GenSigStartValue" SG_ 1496 RS_Detn08_PosY 8193.36337566571;
BA_ "GenSigStartValue" SG_ 1496 RS_Detn08_PosX 8193.36337566571;
BA_ "GenSigStartValue" SG_ 1510 RS_Detn06_Elev 15;
BA_ "CustomizedSignalType" SG_ 1510 RS_Detn06_Msg02_CheckSum 1;
BA_ "CustomizedSignalType" SG_ 1510 RS_Detn06_Msg02_AliveCounter 2;
BA_ "GenSigStartValue" SG_ 1510 RS_Detn06_MotnSts 3;
BA_ "CustomizedSignalType" SG_ 1493 RS_Detn05_Msg01_CheckSum 1;
BA_ "CustomizedSignalType" SG_ 1493 RS_Detn05_Msg01_AliveCounter 2;
BA_ "GenSigStartValue" SG_ 1493 RS_Detn05_PosY 8193.36337566571;
BA_ "GenSigStartValue" SG_ 1493 RS_Detn05_PosX 8193.36337566571;
BA_ "GenSigStartValue" SG_ 1507 RS_Detn03_Elev 15;
BA_ "CustomizedSignalType" SG_ 1507 RS_Detn03_Msg02_CheckSum 1;
BA_ "CustomizedSignalType" SG_ 1507 RS_Detn03_Msg02_AliveCounter 2;
BA_ "GenSigStartValue" SG_ 1507 RS_Detn03_MotnSts 3;
BA_ "CustomizedSignalType" SG_ 1490 RS_Detn02_Msg01_CheckSum 1;
BA_ "CustomizedSignalType" SG_ 1490 RS_Detn02_Msg01_AliveCounter 2;
BA_ "GenSigStartValue" SG_ 1490 RS_Detn02_PosY 8193.36337566571;
BA_ "GenSigStartValue" SG_ 1490 RS_Detn02_PosX 8193.36337566571;
BA_ "GenSigStartValue" SG_ 1504 RS_Detn00_Elev 15;
BA_ "GenSigStartValue" SG_ 1504 RS_Detn00_MotnSts 3;
BA_ "CustomizedSignalType" SG_ 1504 RS_Detn00_Msg02_CheckSum 1;
BA_ "CustomizedSignalType" SG_ 1504 RS_Detn00_Msg02_AliveCounter 2;
BA_ "GenSigStartValue" SG_ 1389 RS_Obj29_heading -1;
BA_ "CustomizedSignalType" SG_ 1389 RS_Obj29_Msg02_CheckSum 1;
BA_ "CustomizedSignalType" SG_ 1389 RS_Obj29_Msg02_AliveCounter 2;
BA_ "GenSigStartValue" SG_ 1388 RS_Obj28_heading -1;
BA_ "CustomizedSignalType" SG_ 1388 RS_Obj28_Msg02_CheckSum 1;
BA_ "CustomizedSignalType" SG_ 1388 RS_Obj28_Msg02_AliveCounter 2;
BA_ "GenSigStartValue" SG_ 1387 RS_Obj27_heading -1;
BA_ "CustomizedSignalType" SG_ 1387 RS_Obj27_Msg02_CheckSum 1;
BA_ "CustomizedSignalType" SG_ 1387 RS_Obj27_Msg02_AliveCounter 2;
BA_ "GenSigStartValue" SG_ 1386 RS_Obj26_heading -1;
BA_ "CustomizedSignalType" SG_ 1386 RS_Obj26_Msg02_CheckSum 1;
BA_ "CustomizedSignalType" SG_ 1386 RS_Obj26_Msg02_AliveCounter 2;
BA_ "GenSigStartValue" SG_ 1385 RS_Obj25_heading -1;
BA_ "CustomizedSignalType" SG_ 1385 RS_Obj25_Msg02_CheckSum 1;
BA_ "CustomizedSignalType" SG_ 1385 RS_Obj25_Msg02_AliveCounter 2;
BA_ "GenSigStartValue" SG_ 1384 RS_Obj24_heading -1;
BA_ "CustomizedSignalType" SG_ 1384 RS_Obj24_Msg02_CheckSum 1;
BA_ "CustomizedSignalType" SG_ 1384 RS_Obj24_Msg02_AliveCounter 2;
BA_ "GenSigStartValue" SG_ 1383 RS_Obj23_heading -1;
BA_ "CustomizedSignalType" SG_ 1383 RS_Obj23_Msg02_CheckSum 1;
BA_ "CustomizedSignalType" SG_ 1383 RS_Obj23_Msg02_AliveCounter 2;
BA_ "GenSigStartValue" SG_ 1382 RS_Obj22_heading -1;
BA_ "CustomizedSignalType" SG_ 1382 RS_Obj22_Msg02_CheckSum 1;
BA_ "CustomizedSignalType" SG_ 1382 RS_Obj22_Msg02_AliveCounter 2;
BA_ "GenSigStartValue" SG_ 1381 RS_Obj21_heading -1;
BA_ "CustomizedSignalType" SG_ 1381 RS_Obj21_Msg02_CheckSum 1;
BA_ "CustomizedSignalType" SG_ 1381 RS_Obj21_Msg02_AliveCounter 2;
BA_ "GenSigStartValue" SG_ 1380 RS_Obj20_heading -1;
BA_ "CustomizedSignalType" SG_ 1380 RS_Obj20_Msg02_CheckSum 1;
BA_ "CustomizedSignalType" SG_ 1380 RS_Obj20_Msg02_AliveCounter 2;
BA_ "GenSigStartValue" SG_ 1379 RS_Obj19_heading -1;
BA_ "CustomizedSignalType" SG_ 1379 RS_Obj19_Msg02_CheckSum 1;
BA_ "CustomizedSignalType" SG_ 1379 RS_Obj19_Msg02_AliveCounter 2;
BA_ "GenSigStartValue" SG_ 1378 RS_Obj18_heading -1;
BA_ "CustomizedSignalType" SG_ 1378 RS_Obj18_Msg02_CheckSum 1;
BA_ "CustomizedSignalType" SG_ 1378 RS_Obj18_Msg02_AliveCounter 2;
BA_ "GenSigStartValue" SG_ 1377 RS_Obj17_heading -1;
BA_ "CustomizedSignalType" SG_ 1377 RS_Obj17_Msg02_CheckSum 1;
BA_ "CustomizedSignalType" SG_ 1377 RS_Obj17_Msg02_AliveCounter 2;
BA_ "GenSigStartValue" SG_ 1376 RS_Obj16_heading -1;
BA_ "CustomizedSignalType" SG_ 1376 RS_Obj16_Msg02_CheckSum 1;
BA_ "CustomizedSignalType" SG_ 1376 RS_Obj16_Msg02_AliveCounter 2;
BA_ "GenSigStartValue" SG_ 1375 RS_Obj15_heading -1;
BA_ "CustomizedSignalType" SG_ 1375 RS_Obj15_Msg02_CheckSum 1;
BA_ "CustomizedSignalType" SG_ 1375 RS_Obj15_Msg02_AliveCounter 2;
BA_ "GenSigStartValue" SG_ 1374 RS_Obj14_heading -1;
BA_ "CustomizedSignalType" SG_ 1374 RS_Obj14_Msg02_CheckSum 1;
BA_ "CustomizedSignalType" SG_ 1374 RS_Obj14_Msg02_AliveCounter 2;
BA_ "GenSigStartValue" SG_ 1373 RS_Obj13_heading -1;
BA_ "CustomizedSignalType" SG_ 1373 RS_Obj13_Msg02_CheckSum 1;
BA_ "CustomizedSignalType" SG_ 1373 RS_Obj13_Msg02_AliveCounter 2;
BA_ "GenSigStartValue" SG_ 1372 RS_Obj12_heading -1;
BA_ "CustomizedSignalType" SG_ 1372 RS_Obj12_Msg02_CheckSum 1;
BA_ "CustomizedSignalType" SG_ 1372 RS_Obj12_Msg02_AliveCounter 2;
BA_ "GenSigStartValue" SG_ 1371 RS_Obj11_heading -1;
BA_ "CustomizedSignalType" SG_ 1371 RS_Obj11_Msg02_CheckSum 1;
BA_ "CustomizedSignalType" SG_ 1371 RS_Obj11_Msg02_AliveCounter 2;
BA_ "GenSigStartValue" SG_ 1370 RS_Obj10_heading -1;
BA_ "CustomizedSignalType" SG_ 1370 RS_Obj10_Msg02_CheckSum 1;
BA_ "CustomizedSignalType" SG_ 1370 RS_Obj10_Msg02_AliveCounter 2;
BA_ "GenSigStartValue" SG_ 1369 RS_Obj09_heading -1;
BA_ "CustomizedSignalType" SG_ 1369 RS_Obj09_Msg02_CheckSum 1;
BA_ "CustomizedSignalType" SG_ 1369 RS_Obj09_Msg02_AliveCounter 2;
BA_ "GenSigStartValue" SG_ 1368 RS_Obj08_heading -1;
BA_ "CustomizedSignalType" SG_ 1368 RS_Obj08_Msg02_CheckSum 1;
BA_ "CustomizedSignalType" SG_ 1368 RS_Obj08_Msg02_AliveCounter 2;
BA_ "GenSigStartValue" SG_ 1367 RS_Obj07_heading -1;
BA_ "CustomizedSignalType" SG_ 1367 RS_Obj07_Msg02_CheckSum 1;
BA_ "CustomizedSignalType" SG_ 1367 RS_Obj07_Msg02_AliveCounter 2;
BA_ "GenSigStartValue" SG_ 1366 RS_Obj06_heading -1;
BA_ "CustomizedSignalType" SG_ 1366 RS_Obj06_Msg02_CheckSum 1;
BA_ "CustomizedSignalType" SG_ 1366 RS_Obj06_Msg02_AliveCounter 2;
BA_ "GenSigStartValue" SG_ 1365 RS_Obj05_heading -1;
BA_ "CustomizedSignalType" SG_ 1365 RS_Obj05_Msg02_CheckSum 1;
BA_ "CustomizedSignalType" SG_ 1365 RS_Obj05_Msg02_AliveCounter 2;
BA_ "GenSigStartValue" SG_ 1364 RS_Obj04_heading -1;
BA_ "CustomizedSignalType" SG_ 1364 RS_Obj04_Msg02_CheckSum 1;
BA_ "CustomizedSignalType" SG_ 1364 RS_Obj04_Msg02_AliveCounter 2;
BA_ "GenSigStartValue" SG_ 1363 RS_Obj03_heading -1;
BA_ "CustomizedSignalType" SG_ 1363 RS_Obj03_Msg02_CheckSum 1;
BA_ "CustomizedSignalType" SG_ 1363 RS_Obj03_Msg02_AliveCounter 2;
BA_ "GenSigStartValue" SG_ 1362 RS_Obj02_heading -1;
BA_ "CustomizedSignalType" SG_ 1362 RS_Obj02_Msg02_CheckSum 1;
BA_ "CustomizedSignalType" SG_ 1362 RS_Obj02_Msg02_AliveCounter 2;
BA_ "GenSigStartValue" SG_ 1361 RS_Obj01_heading -1;
BA_ "CustomizedSignalType" SG_ 1361 RS_Obj01_Msg02_CheckSum 1;
BA_ "CustomizedSignalType" SG_ 1361 RS_Obj01_Msg02_AliveCounter 2;
BA_ "GenSigStartValue" SG_ 1517 RS_Detn13_Elev 15;
BA_ "CustomizedSignalType" SG_ 1517 RS_Detn13_Msg02_CheckSum 1;
BA_ "CustomizedSignalType" SG_ 1517 RS_Detn13_Msg02_AliveCounter 2;
BA_ "GenSigStartValue" SG_ 1517 RS_Detn13_MotnSts 3;
BA_ "CustomizedSignalType" SG_ 1500 RS_Detn12_Msg01_CheckSum 1;
BA_ "CustomizedSignalType" SG_ 1500 RS_Detn12_Msg01_AliveCounter 2;
BA_ "GenSigStartValue" SG_ 1500 RS_Detn12_PosY 8193.36337566571;
BA_ "GenSigStartValue" SG_ 1500 RS_Detn12_PosX 8193.36337566571;
BA_ "GenSigStartValue" SG_ 1514 RS_Detn10_Elev 15;
BA_ "CustomizedSignalType" SG_ 1514 RS_Detn10_Msg02_CheckSum 1;
BA_ "CustomizedSignalType" SG_ 1514 RS_Detn10_Msg02_AliveCounter 2;
BA_ "GenSigStartValue" SG_ 1514 RS_Detn10_MotnSts 3;
BA_ "CustomizedSignalType" SG_ 1497 RS_Detn09_Msg01_CheckSum 1;
BA_ "CustomizedSignalType" SG_ 1497 RS_Detn09_Msg01_AliveCounter 2;
BA_ "GenSigStartValue" SG_ 1497 RS_Detn09_PosY 8193.36337566571;
BA_ "GenSigStartValue" SG_ 1497 RS_Detn09_PosX 8193.36337566571;
BA_ "GenSigStartValue" SG_ 1511 RS_Detn07_Elev 15;
BA_ "CustomizedSignalType" SG_ 1511 RS_Detn07_Msg02_CheckSum 1;
BA_ "CustomizedSignalType" SG_ 1511 RS_Detn07_Msg02_AliveCounter 2;
BA_ "GenSigStartValue" SG_ 1511 RS_Detn07_MotnSts 3;
BA_ "CustomizedSignalType" SG_ 1494 RS_Detn06_Msg01_CheckSum 1;
BA_ "CustomizedSignalType" SG_ 1494 RS_Detn06_Msg01_AliveCounter 2;
BA_ "GenSigStartValue" SG_ 1494 RS_Detn06_PosY 8193.36337566571;
BA_ "GenSigStartValue" SG_ 1494 RS_Detn06_PosX 8193.36337566571;
BA_ "GenSigStartValue" SG_ 1508 RS_Detn04_Elev 15;
BA_ "CustomizedSignalType" SG_ 1508 RS_Detn04_Msg02_CheckSum 1;
BA_ "CustomizedSignalType" SG_ 1508 RS_Detn04_Msg02_AliveCounter 2;
BA_ "GenSigStartValue" SG_ 1508 RS_Detn04_MotnSts 3;
BA_ "CustomizedSignalType" SG_ 1491 RS_Detn03_Msg01_CheckSum 1;
BA_ "CustomizedSignalType" SG_ 1491 RS_Detn03_Msg01_AliveCounter 2;
BA_ "GenSigStartValue" SG_ 1491 RS_Detn03_PosY 8193.36337566571;
BA_ "GenSigStartValue" SG_ 1491 RS_Detn03_PosX 8193.36337566571;
BA_ "GenSigStartValue" SG_ 1505 RS_Detn01_Elev 15;
BA_ "CustomizedSignalType" SG_ 1505 RS_Detn01_Msg02_CheckSum 1;
BA_ "CustomizedSignalType" SG_ 1505 RS_Detn01_Msg02_AliveCounter 2;
BA_ "GenSigStartValue" SG_ 1505 RS_Detn01_MotnSts 3;
BA_ "CustomizedSignalType" SG_ 1488 RS_Detn00_Msg01_CheckSum 1;
BA_ "CustomizedSignalType" SG_ 1488 RS_Detn00_Msg01_AliveCounter 2;
BA_ "GenSigStartValue" SG_ 1488 RS_Detn00_PosY 8193.36337566571;
BA_ "GenSigStartValue" SG_ 1488 RS_Detn00_PosX 8193.36337566571;
BA_ "GenSigStartValue" SG_ 1341 RS_Obj29_MeasFlag 1;
BA_ "GenSigStartValue" SG_ 1341 RS_Obj29_YPos 8193.36337566571;
BA_ "GenSigStartValue" SG_ 1341 RS_Obj29_XPos 8193.36337566571;
BA_ "CustomizedSignalType" SG_ 1341 RS_Obj29_Msg01_AliveCounter 2;
BA_ "CustomizedSignalType" SG_ 1341 RS_Obj29_Msg01_CheckSum 1;
BA_ "GenSigStartValue" SG_ 1341 RS_Obj29_ID 8191;
BA_ "GenSigStartValue" SG_ 1340 RS_Obj28_MeasFlag 1;
BA_ "GenSigStartValue" SG_ 1340 RS_Obj28_YPos 8193.36337566571;
BA_ "GenSigStartValue" SG_ 1340 RS_Obj28_XPos 8193.36337566571;
BA_ "CustomizedSignalType" SG_ 1340 RS_Obj28_Msg01_AliveCounter 2;
BA_ "CustomizedSignalType" SG_ 1340 RS_Obj28_Msg01_CheckSum 1;
BA_ "GenSigStartValue" SG_ 1340 RS_Obj28_ID 8191;
BA_ "GenSigStartValue" SG_ 1339 RS_Obj27_MeasFlag 1;
BA_ "GenSigStartValue" SG_ 1339 RS_Obj27_YPos 8193.36337566571;
BA_ "GenSigStartValue" SG_ 1339 RS_Obj27_XPos 8193.36337566571;
BA_ "CustomizedSignalType" SG_ 1339 RS_Obj27_Msg01_AliveCounter 2;
BA_ "CustomizedSignalType" SG_ 1339 RS_Obj27_Msg01_CheckSum 1;
BA_ "GenSigStartValue" SG_ 1339 RS_Obj27_ID 8191;
BA_ "GenSigStartValue" SG_ 1338 RS_Obj26_MeasFlag 1;
BA_ "GenSigStartValue" SG_ 1338 RS_Obj26_YPos 8193.36337566571;
BA_ "GenSigStartValue" SG_ 1338 RS_Obj26_XPos 8193.36337566571;
BA_ "CustomizedSignalType" SG_ 1338 RS_Obj26_Msg01_AliveCounter 2;
BA_ "CustomizedSignalType" SG_ 1338 RS_Obj26_Msg01_CheckSum 1;
BA_ "GenSigStartValue" SG_ 1338 RS_Obj26_ID 8191;
BA_ "GenSigStartValue" SG_ 1337 RS_Obj25_MeasFlag 1;
BA_ "GenSigStartValue" SG_ 1337 RS_Obj25_YPos 8193.36337566571;
BA_ "GenSigStartValue" SG_ 1337 RS_Obj25_XPos 8193.36337566571;
BA_ "CustomizedSignalType" SG_ 1337 RS_Obj25_Msg01_AliveCounter 2;
BA_ "CustomizedSignalType" SG_ 1337 RS_Obj25_Msg01_CheckSum 1;
BA_ "GenSigStartValue" SG_ 1337 RS_Obj25_ID 8191;
BA_ "GenSigStartValue" SG_ 1336 RS_Obj24_MeasFlag 1;
BA_ "GenSigStartValue" SG_ 1336 RS_Obj24_YPos 8193.36337566571;
BA_ "GenSigStartValue" SG_ 1336 RS_Obj24_XPos 8193.36337566571;
BA_ "CustomizedSignalType" SG_ 1336 RS_Obj24_Msg01_AliveCounter 2;
BA_ "CustomizedSignalType" SG_ 1336 RS_Obj24_Msg01_CheckSum 1;
BA_ "GenSigStartValue" SG_ 1336 RS_Obj24_ID 8191;
BA_ "GenSigStartValue" SG_ 1335 RS_Obj23_MeasFlag 1;
BA_ "GenSigStartValue" SG_ 1335 RS_Obj23_YPos 8193.36337566571;
BA_ "GenSigStartValue" SG_ 1335 RS_Obj23_XPos 8193.36337566571;
BA_ "CustomizedSignalType" SG_ 1335 RS_Obj23_Msg01_AliveCounter 2;
BA_ "CustomizedSignalType" SG_ 1335 RS_Obj23_Msg01_CheckSum 1;
BA_ "GenSigStartValue" SG_ 1335 RS_Obj23_ID 8191;
BA_ "GenSigStartValue" SG_ 1334 RS_Obj22_MeasFlag 1;
BA_ "GenSigStartValue" SG_ 1334 RS_Obj22_YPos 8193.36337566571;
BA_ "GenSigStartValue" SG_ 1334 RS_Obj22_XPos 8193.36337566571;
BA_ "CustomizedSignalType" SG_ 1334 RS_Obj22_Msg01_AliveCounter 2;
BA_ "CustomizedSignalType" SG_ 1334 RS_Obj22_Msg01_CheckSum 1;
BA_ "GenSigStartValue" SG_ 1334 RS_Obj22_ID 8191;
BA_ "GenSigStartValue" SG_ 1333 RS_Obj21_MeasFlag 1;
BA_ "GenSigStartValue" SG_ 1333 RS_Obj21_YPos 8193.36337566571;
BA_ "GenSigStartValue" SG_ 1333 RS_Obj21_XPos 8193.36337566571;
BA_ "CustomizedSignalType" SG_ 1333 RS_Obj21_Msg01_AliveCounter 2;
BA_ "CustomizedSignalType" SG_ 1333 RS_Obj21_Msg01_CheckSum 1;
BA_ "GenSigStartValue" SG_ 1333 RS_Obj21_ID 8191;
BA_ "GenSigStartValue" SG_ 1332 RS_Obj20_MeasFlag 1;
BA_ "GenSigStartValue" SG_ 1332 RS_Obj20_YPos 8193.36337566571;
BA_ "GenSigStartValue" SG_ 1332 RS_Obj20_XPos 8193.36337566571;
BA_ "CustomizedSignalType" SG_ 1332 RS_Obj20_Msg01_AliveCounter 2;
BA_ "CustomizedSignalType" SG_ 1332 RS_Obj20_Msg01_CheckSum 1;
BA_ "GenSigStartValue" SG_ 1332 RS_Obj20_ID 8191;
BA_ "GenSigStartValue" SG_ 1331 RS_Obj19_MeasFlag 1;
BA_ "GenSigStartValue" SG_ 1331 RS_Obj19_YPos 8193.36337566571;
BA_ "GenSigStartValue" SG_ 1331 RS_Obj19_XPos 8193.36337566571;
BA_ "CustomizedSignalType" SG_ 1331 RS_Obj19_Msg01_AliveCounter 2;
BA_ "CustomizedSignalType" SG_ 1331 RS_Obj19_Msg01_CheckSum 1;
BA_ "GenSigStartValue" SG_ 1331 RS_Obj19_ID 8191;
BA_ "GenSigStartValue" SG_ 1330 RS_Obj18_MeasFlag 1;
BA_ "GenSigStartValue" SG_ 1330 RS_Obj18_YPos 8193.36337566571;
BA_ "GenSigStartValue" SG_ 1330 RS_Obj18_XPos 8193.36337566571;
BA_ "CustomizedSignalType" SG_ 1330 RS_Obj18_Msg01_AliveCounter 2;
BA_ "CustomizedSignalType" SG_ 1330 RS_Obj18_Msg01_CheckSum 1;
BA_ "GenSigStartValue" SG_ 1330 RS_Obj18_ID 8191;
BA_ "GenSigStartValue" SG_ 1329 RS_Obj17_MeasFlag 1;
BA_ "GenSigStartValue" SG_ 1329 RS_Obj17_YPos 8193.36337566571;
BA_ "GenSigStartValue" SG_ 1329 RS_Obj17_XPos 8193.36337566571;
BA_ "CustomizedSignalType" SG_ 1329 RS_Obj17_Msg01_AliveCounter 2;
BA_ "CustomizedSignalType" SG_ 1329 RS_Obj17_Msg01_CheckSum 1;
BA_ "GenSigStartValue" SG_ 1329 RS_Obj17_ID 8191;
BA_ "GenSigStartValue" SG_ 1328 RS_Obj16_MeasFlag 1;
BA_ "GenSigStartValue" SG_ 1328 RS_Obj16_YPos 8193.36337566571;
BA_ "GenSigStartValue" SG_ 1328 RS_Obj16_XPos 8193.36337566571;
BA_ "CustomizedSignalType" SG_ 1328 RS_Obj16_Msg01_AliveCounter 2;
BA_ "CustomizedSignalType" SG_ 1328 RS_Obj16_Msg01_CheckSum 1;
BA_ "GenSigStartValue" SG_ 1328 RS_Obj16_ID 8191;
BA_ "GenSigStartValue" SG_ 1327 RS_Obj15_MeasFlag 1;
BA_ "GenSigStartValue" SG_ 1327 RS_Obj15_YPos 8193.36337566571;
BA_ "GenSigStartValue" SG_ 1327 RS_Obj15_XPos 8193.36337566571;
BA_ "CustomizedSignalType" SG_ 1327 RS_Obj15_Msg01_AliveCounter 2;
BA_ "CustomizedSignalType" SG_ 1327 RS_Obj15_Msg01_CheckSum 1;
BA_ "GenSigStartValue" SG_ 1327 RS_Obj15_ID 8191;
BA_ "GenSigStartValue" SG_ 1326 RS_Obj14_MeasFlag 1;
BA_ "GenSigStartValue" SG_ 1326 RS_Obj14_YPos 8193.36337566571;
BA_ "GenSigStartValue" SG_ 1326 RS_Obj14_XPos 8193.36337566571;
BA_ "CustomizedSignalType" SG_ 1326 RS_Obj14_Msg01_AliveCounter 2;
BA_ "CustomizedSignalType" SG_ 1326 RS_Obj14_Msg01_CheckSum 1;
BA_ "GenSigStartValue" SG_ 1326 RS_Obj14_ID 8191;
BA_ "GenSigStartValue" SG_ 1325 RS_Obj13_MeasFlag 1;
BA_ "GenSigStartValue" SG_ 1325 RS_Obj13_YPos 8193.36337566571;
BA_ "GenSigStartValue" SG_ 1325 RS_Obj13_XPos 8193.36337566571;
BA_ "CustomizedSignalType" SG_ 1325 RS_Obj13_Msg01_AliveCounter 2;
BA_ "CustomizedSignalType" SG_ 1325 RS_Obj13_Msg01_CheckSum 1;
BA_ "GenSigStartValue" SG_ 1325 RS_Obj13_ID 8191;
BA_ "GenSigStartValue" SG_ 1324 RS_Obj12_MeasFlag 1;
BA_ "GenSigStartValue" SG_ 1324 RS_Obj12_YPos 8193.36337566571;
BA_ "GenSigStartValue" SG_ 1324 RS_Obj12_XPos 8193.36337566571;
BA_ "CustomizedSignalType" SG_ 1324 RS_Obj12_Msg01_AliveCounter 2;
BA_ "CustomizedSignalType" SG_ 1324 RS_Obj12_Msg01_CheckSum 1;
BA_ "GenSigStartValue" SG_ 1324 RS_Obj12_ID 8191;
BA_ "GenSigStartValue" SG_ 1323 RS_Obj11_MeasFlag 1;
BA_ "GenSigStartValue" SG_ 1323 RS_Obj11_YPos 8193.36337566571;
BA_ "GenSigStartValue" SG_ 1323 RS_Obj11_XPos 8193.36337566571;
BA_ "CustomizedSignalType" SG_ 1323 RS_Obj11_Msg01_AliveCounter 2;
BA_ "CustomizedSignalType" SG_ 1323 RS_Obj11_Msg01_CheckSum 1;
BA_ "GenSigStartValue" SG_ 1323 RS_Obj11_ID 8191;
BA_ "GenSigStartValue" SG_ 1322 RS_Obj10_MeasFlag 1;
BA_ "GenSigStartValue" SG_ 1322 RS_Obj10_YPos 8193.36337566571;
BA_ "GenSigStartValue" SG_ 1322 RS_Obj10_XPos 8193.36337566571;
BA_ "CustomizedSignalType" SG_ 1322 RS_Obj10_Msg01_AliveCounter 2;
BA_ "CustomizedSignalType" SG_ 1322 RS_Obj10_Msg01_CheckSum 1;
BA_ "GenSigStartValue" SG_ 1322 RS_Obj10_ID 8191;
BA_ "GenSigStartValue" SG_ 1321 RS_Obj09_MeasFlag 1;
BA_ "GenSigStartValue" SG_ 1321 RS_Obj09_YPos 8193.36337566571;
BA_ "GenSigStartValue" SG_ 1321 RS_Obj09_XPos 8193.36337566571;
BA_ "CustomizedSignalType" SG_ 1321 RS_Obj09_Msg01_AliveCounter 2;
BA_ "CustomizedSignalType" SG_ 1321 RS_Obj09_Msg01_CheckSum 1;
BA_ "GenSigStartValue" SG_ 1321 RS_Obj09_ID 8191;
BA_ "GenSigStartValue" SG_ 1320 RS_Obj08_MeasFlag 1;
BA_ "GenSigStartValue" SG_ 1320 RS_Obj08_YPos 8193.36337566571;
BA_ "GenSigStartValue" SG_ 1320 RS_Obj08_XPos 8193.36337566571;
BA_ "CustomizedSignalType" SG_ 1320 RS_Obj08_Msg01_AliveCounter 2;
BA_ "CustomizedSignalType" SG_ 1320 RS_Obj08_Msg01_CheckSum 1;
BA_ "GenSigStartValue" SG_ 1320 RS_Obj08_ID 8191;
BA_ "GenSigStartValue" SG_ 1319 RS_Obj07_MeasFlag 1;
BA_ "GenSigStartValue" SG_ 1319 RS_Obj07_YPos 8193.36337566571;
BA_ "GenSigStartValue" SG_ 1319 RS_Obj07_XPos 8193.36337566571;
BA_ "CustomizedSignalType" SG_ 1319 RS_Obj07_Msg01_AliveCounter 2;
BA_ "CustomizedSignalType" SG_ 1319 RS_Obj07_Msg01_CheckSum 1;
BA_ "GenSigStartValue" SG_ 1319 RS_Obj07_ID 8191;
BA_ "GenSigStartValue" SG_ 1318 RS_Obj06_MeasFlag 1;
BA_ "GenSigStartValue" SG_ 1318 RS_Obj06_YPos 8193.36337566571;
BA_ "GenSigStartValue" SG_ 1318 RS_Obj06_XPos 8193.36337566571;
BA_ "CustomizedSignalType" SG_ 1318 RS_Obj06_Msg01_AliveCounter 2;
BA_ "CustomizedSignalType" SG_ 1318 RS_Obj06_Msg01_CheckSum 1;
BA_ "GenSigStartValue" SG_ 1318 RS_Obj06_ID 8191;
BA_ "GenSigStartValue" SG_ 1317 RS_Obj05_MeasFlag 1;
BA_ "GenSigStartValue" SG_ 1317 RS_Obj05_YPos 8193.36337566571;
BA_ "GenSigStartValue" SG_ 1317 RS_Obj05_XPos 8193.36337566571;
BA_ "CustomizedSignalType" SG_ 1317 RS_Obj05_Msg01_AliveCounter 2;
BA_ "CustomizedSignalType" SG_ 1317 RS_Obj05_Msg01_CheckSum 1;
BA_ "GenSigStartValue" SG_ 1317 RS_Obj05_ID 8191;
BA_ "GenSigStartValue" SG_ 1316 RS_Obj04_MeasFlag 1;
BA_ "GenSigStartValue" SG_ 1316 RS_Obj04_YPos 8193.36337566571;
BA_ "GenSigStartValue" SG_ 1316 RS_Obj04_XPos 8193.36337566571;
BA_ "CustomizedSignalType" SG_ 1316 RS_Obj04_Msg01_AliveCounter 2;
BA_ "CustomizedSignalType" SG_ 1316 RS_Obj04_Msg01_CheckSum 1;
BA_ "GenSigStartValue" SG_ 1316 RS_Obj04_ID 8191;
BA_ "GenSigStartValue" SG_ 1315 RS_Obj03_MeasFlag 1;
BA_ "GenSigStartValue" SG_ 1315 RS_Obj03_YPos 8193.36337566571;
BA_ "GenSigStartValue" SG_ 1315 RS_Obj03_XPos 8193.36337566571;
BA_ "CustomizedSignalType" SG_ 1315 RS_Obj03_Msg01_AliveCounter 2;
BA_ "CustomizedSignalType" SG_ 1315 RS_Obj03_Msg01_CheckSum 1;
BA_ "GenSigStartValue" SG_ 1315 RS_Obj03_ID 8191;
BA_ "GenSigStartValue" SG_ 1314 RS_Obj02_MeasFlag 1;
BA_ "GenSigStartValue" SG_ 1314 RS_Obj02_YPos 8193.36337566571;
BA_ "GenSigStartValue" SG_ 1314 RS_Obj02_XPos 8193.36337566571;
BA_ "CustomizedSignalType" SG_ 1314 RS_Obj02_Msg01_AliveCounter 2;
BA_ "CustomizedSignalType" SG_ 1314 RS_Obj02_Msg01_CheckSum 1;
BA_ "GenSigStartValue" SG_ 1314 RS_Obj02_ID 8191;
BA_ "GenSigStartValue" SG_ 1313 RS_Obj01_MeasFlag 1;
BA_ "GenSigStartValue" SG_ 1313 RS_Obj01_YPos 8193.36337566571;
BA_ "GenSigStartValue" SG_ 1313 RS_Obj01_XPos 8193.36337566571;
BA_ "CustomizedSignalType" SG_ 1313 RS_Obj01_Msg01_AliveCounter 2;
BA_ "CustomizedSignalType" SG_ 1313 RS_Obj01_Msg01_CheckSum 1;
BA_ "GenSigStartValue" SG_ 1313 RS_Obj01_ID 8191;
BA_ "GenSigStartValue" SG_ 1360 RS_Obj00_heading -1;
BA_ "CustomizedSignalType" SG_ 1360 RS_Obj00_Msg02_CheckSum 1;
BA_ "CustomizedSignalType" SG_ 1360 RS_Obj00_Msg02_AliveCounter 2;
BA_ "GenSigStartValue" SG_ 1312 RS_Obj00_MeasFlag 1;
BA_ "GenSigStartValue" SG_ 1312 RS_Obj00_YPos 8193.36337566571;
BA_ "GenSigStartValue" SG_ 1312 RS_Obj00_XPos 8193.36337566571;
BA_ "CustomizedSignalType" SG_ 1312 RS_Obj00_Msg01_AliveCounter 2;
BA_ "CustomizedSignalType" SG_ 1312 RS_Obj00_Msg01_CheckSum 1;
BA_ "GenSigStartValue" SG_ 1312 RS_Obj00_ID 8191;
BA_ "CustomizedSignalType" SG_ 1472 RS_Msg_CheckSum 1;
BA_ "CustomizedSignalType" SG_ 1472 RS_Msg_AliveCounter 2;
BA_ "GenSigSendType" SG_ 2015 Func_DiagReq_Byte7 2;
BA_ "GenSigSendType" SG_ 2015 Func_DiagReq_Byte6 2;
BA_ "GenSigSendType" SG_ 2015 Func_DiagReq_Byte5 2;
BA_ "GenSigSendType" SG_ 2015 Func_DiagReq_Byte4 2;
BA_ "GenSigSendType" SG_ 2015 Func_DiagReq_Byte3 2;
BA_ "GenSigSendType" SG_ 2015 Func_DiagReq_Byte2 2;
BA_ "GenSigSendType" SG_ 2015 Func_DiagReq_Byte0 2;
BA_ "CustomizedSignalType" SG_ 357 VCU_ModeControl_CheckSum 1;
BA_ "CustomizedSignalType" SG_ 357 VCU_ModeControl_AliveCounter 2;
BA_ "GenSigStartValue" SG_ 357 VCU_CurrentGearPosition 15;
BA_ "GenSigInactiveValue" SG_ 357 VCU_CurrentGearPosition 15;
BA_ "GenSigStartValue" SG_ 304 YRS_LateralSensorState 3;
BA_ "CustomizedSignalType" SG_ 304 YRS1_CheckSum 1;
BA_ "CustomizedSignalType" SG_ 304 YRS1_AliveCounter 2;
BA_ "GenSigStartValue" SG_ 304 YRS_YawRateSensorState 3;
BA_ "GenSigStartValue" SG_ 305 YRS_LongitSensorState 3;
BA_ "CustomizedSignalType" SG_ 305 YRS2_CheckSum 1;
BA_ "CustomizedSignalType" SG_ 305 YRS2_AliveCounter 2;
BA_ "CustomizedSignalType" SG_ 224 SAS_Status_AliveCounter 2;
BA_ "CustomizedSignalType" SG_ 224 SAS_Status_CheckSum 1;
BA_ "GenSigInactiveValue" SG_ 224 SAS_SteerWheelAngle 32767;
BA_ "GenSigInactiveValue" SG_ 293 ESC_VehicleSpeedInvalid 1;
BA_ "CustomizedSignalType" SG_ 293 ESC_Status_AliveCounter 2;
BA_ "CustomizedSignalType" SG_ 293 ESC_Status_CheckSum 1;
BA_ "CustomizedSignalType" SG_ 133 EMS_EngineRPM_AliveCounter 2;
BA_ "CustomizedSignalType" SG_ 133 EMS_EngineRPM_CheckSum 1;
BA_ "CustomizedSignalType" SG_ 275 TCU_Status_AliveCounter 2;
BA_ "GenSigStartValue" SG_ 275 TCU_CurrentGearPosition 15;
BA_ "GenSigInactiveValue" SG_ 275 TCU_CurrentGearPosition 15;
BA_ "CustomizedSignalType" SG_ 275 TCU_Status_CheckSum 1;
VAL_ 482 PEPS_PowerModeValidity 3 "Reserved" 2 "Valid" 1 "Invalid" 0 "Not Available" ;
VAL_ 482 PEPS_PowerMode 4 "START" 3 "Reserved" 2 "ON" 1 "ACC" 0 "OFF" ;
VAL_ 644 BCM_ATWS_St 7 "Reserved" 6 "Reserved" 5 "Partially Armed" 4 "Alarm" 3 "Remind" 2 "Disarmed" 1 "Prearmed" 0 "Armed" ;
VAL_ 646 BCM_DoorLockStatusRR 3 "Error(Reserved)" 2 "Reserved" 1 "Locked" 0 "Unlocked" ;
VAL_ 646 BCM_DoorLockStatusPass 3 "Error(Reserved)" 2 "Reserved" 1 "Locked" 0 "Unlocked" ;
VAL_ 646 BCM_RearRightDoorAjarStatus 1 "Door Ajar" 0 "Door Closed" ;
VAL_ 646 BCM_FrontRightDoorAjarStatus 1 "Door Ajar" 0 "Door Closed" ;
VAL_ 645 BCM_DoorLockStatusRL 3 "Error(Reserved)" 2 "Reserved" 1 "Locked" 0 "Unlocked" ;
VAL_ 645 BCM_DoorLockStatusDrv 3 "Error(Reserved)" 2 "Reserved" 1 "Locked" 0 "Unlocked" ;
VAL_ 645 BCM_RearLeftDoorAjarStatus 1 "Door Ajar" 0 "Door Closed" ;
VAL_ 645 BCM_FrontLeftDoorAjarStatus 1 "Door Ajar" 0 "Door Closed" ;
VAL_ 496 BCM_TurnLeverSts 3 "Error Status" 2 "Turn Right" 1 "Turn left" 0 "Inactive" ;
VAL_ 1518 RS_Detn14_MotnSts 3 "MotionSts_Invalid" 2 "MotionSts_Staty" 1 "MotionSts_Movg" 0 "MotionSts_Ukwn" ;
VAL_ 1515 RS_Detn11_MotnSts 3 "MotionSts_Invalid" 2 "MotionSts_Staty" 1 "MotionSts_Movg" 0 "MotionSts_Ukwn" ;
VAL_ 1512 RS_Detn08_MotnSts 3 "MotionSts_Invalid" 2 "MotionSts_Staty" 1 "MotionSts_Movg" 0 "MotionSts_Ukwn" ;
VAL_ 1509 RS_Detn05_MotnSts 3 "MotionSts_Invalid" 2 "MotionSts_Staty" 1 "MotionSts_Movg" 0 "MotionSts_Ukwn" ;
VAL_ 1506 RS_Detn02_MotnSts 3 "MotionSts_Invalid" 2 "MotionSts_Staty" 1 "MotionSts_Movg" 0 "MotionSts_Ukwn" ;
VAL_ 1516 RS_Detn12_MotnSts 3 "MotionSts_Invalid" 2 "MotionSts_Staty" 1 "MotionSts_Movg" 0 "MotionSts_Ukwn" ;
VAL_ 1513 RS_Detn09_MotnSts 3 "MotionSts_Invalid" 2 "MotionSts_Staty" 1 "MotionSts_Movg" 0 "MotionSts_Ukwn" ;
VAL_ 1510 RS_Detn06_MotnSts 3 "MotionSts_Invalid" 2 "MotionSts_Staty" 1 "MotionSts_Movg" 0 "MotionSts_Ukwn" ;
VAL_ 1507 RS_Detn03_MotnSts 3 "MotionSts_Invalid" 2 "MotionSts_Staty" 1 "MotionSts_Movg" 0 "MotionSts_Ukwn" ;
VAL_ 1504 RS_Detn00_MotnSts 3 "MotionSts_Invalid" 2 "MotionSts_Staty" 1 "MotionSts_Movg" 0 "MotionSts_Ukwn" ;
VAL_ 1389 RS_Obj29_CtrkInd 1 "Cluster tracker" 0 "Stationary tracker" ;
VAL_ 1388 RS_Obj28_CtrkInd 1 "Cluster tracker" 0 "Stationary tracker" ;
VAL_ 1387 RS_Obj27_CtrkInd 1 "Cluster tracker" 0 "Stationary tracker" ;
VAL_ 1386 RS_Obj26_CtrkInd 1 "Cluster tracker" 0 "Stationary tracker" ;
VAL_ 1385 RS_Obj25_CtrkInd 1 "Cluster tracker" 0 "Stationary tracker" ;
VAL_ 1384 RS_Obj24_CtrkInd 1 "Cluster tracker" 0 "Stationary tracker" ;
VAL_ 1383 RS_Obj23_CtrkInd 1 "Cluster tracker" 0 "Stationary tracker" ;
VAL_ 1382 RS_Obj22_CtrkInd 1 "Cluster tracker" 0 "Stationary tracker" ;
VAL_ 1381 RS_Obj21_CtrkInd 1 "Cluster tracker" 0 "Stationary tracker" ;
VAL_ 1380 RS_Obj20_CtrkInd 1 "Cluster tracker" 0 "Stationary tracker" ;
VAL_ 1379 RS_Obj19_CtrkInd 1 "Cluster tracker" 0 "Stationary tracker" ;
VAL_ 1378 RS_Obj18_CtrkInd 1 "Cluster tracker" 0 "Stationary tracker" ;
VAL_ 1377 RS_Obj17_CtrkInd 1 "Cluster tracker" 0 "Stationary tracker" ;
VAL_ 1376 RS_Obj16_CtrkInd 1 "Cluster tracker" 0 "Stationary tracker" ;
VAL_ 1375 RS_Obj15_CtrkInd 1 "Cluster tracker" 0 "Stationary tracker" ;
VAL_ 1374 RS_Obj14_CtrkInd 1 "Cluster tracker" 0 "Stationary tracker" ;
VAL_ 1373 RS_Obj13_CtrkInd 1 "Cluster tracker" 0 "Stationary tracker" ;
VAL_ 1372 RS_Obj12_CtrkInd 1 "Cluster tracker" 0 "Stationary tracker" ;
VAL_ 1371 RS_Obj11_CtrkInd 1 "Cluster tracker" 0 "Stationary tracker" ;
VAL_ 1370 RS_Obj10_CtrkInd 1 "Cluster tracker" 0 "Stationary tracker" ;
VAL_ 1369 RS_Obj09_CtrkInd 1 "Cluster tracker" 0 "Stationary tracker" ;
VAL_ 1368 RS_Obj08_CtrkInd 1 "Cluster tracker" 0 "Stationary tracker" ;
VAL_ 1367 RS_Obj07_CtrkInd 1 "Cluster tracker" 0 "Stationary tracker" ;
VAL_ 1366 RS_Obj06_CtrkInd 1 "Cluster tracker" 0 "Stationary tracker" ;
VAL_ 1365 RS_Obj05_CtrkInd 1 "Cluster tracker" 0 "Stationary tracker" ;
VAL_ 1364 RS_Obj04_CtrkInd 1 "Cluster tracker" 0 "Stationary tracker" ;
VAL_ 1363 RS_Obj03_CtrkInd 1 "Cluster tracker" 0 "Stationary tracker" ;
VAL_ 1362 RS_Obj02_CtrkInd 1 "Cluster tracker" 0 "Stationary tracker" ;
VAL_ 1361 RS_Obj01_CtrkInd 1 "Cluster tracker" 0 "Stationary tracker" ;
VAL_ 1517 RS_Detn13_MotnSts 3 "MotionSts_Invalid" 2 "MotionSts_Staty" 1 "MotionSts_Movg" 0 "MotionSts_Ukwn" ;
VAL_ 1514 RS_Detn10_MotnSts 3 "MotionSts_Invalid" 2 "MotionSts_Staty" 1 "MotionSts_Movg" 0 "MotionSts_Ukwn" ;
VAL_ 1511 RS_Detn07_MotnSts 3 "MotionSts_Invalid" 2 "MotionSts_Staty" 1 "MotionSts_Movg" 0 "MotionSts_Ukwn" ;
VAL_ 1508 RS_Detn04_MotnSts 3 "MotionSts_Invalid" 2 "MotionSts_Staty" 1 "MotionSts_Movg" 0 "MotionSts_Ukwn" ;
VAL_ 1505 RS_Detn01_MotnSts 3 "MotionSts_Invalid" 2 "MotionSts_Staty" 1 "MotionSts_Movg" 0 "MotionSts_Ukwn" ;
VAL_ 1341 RS_Obj29_MeasFlag 1 "Obj extrapolated in this cycle" 0 "Object measured in this cycle" ;
VAL_ 1341 RS_Obj29_Type 3 "Pedestrian" 2 "2 wheeler" 1 "4 wheeler" 0 "Unknown" ;
VAL_ 1341 RS_Obj29_ElevConf 3 "High Quality" 2 "Medium Quality" 1 "Low Quality" 0 "No Quality" ;
VAL_ 1341 RS_Obj29_ElevClass 3 "Relevant" 2 "Overridable" 1 "Underrunnable" 0 "Unknow" ;
VAL_ 1341 RS_Obj29_MotionPattern 7 "Reserved" 6 "Reserved" 5 "Reserved" 4 "Crossing" 3 "Moving" 2 "Stopped" 1 "Stationary" 0 "Unknown" ;
VAL_ 1341 RS_Obj29_ValidFlag 1 "Object valid" 0 "Object invalid" ;
VAL_ 1341 RS_Obj29_ID 255 "Invalid" ;
VAL_ 1340 RS_Obj28_MeasFlag 1 "Obj extrapolated in this cycle" 0 "Object measured in this cycle" ;
VAL_ 1340 RS_Obj28_Type 3 "Pedestrian" 2 "2 wheeler" 1 "4 wheeler" 0 "Unknown" ;
VAL_ 1340 RS_Obj28_ElevConf 3 "High Quality" 2 "Medium Quality" 1 "Low Quality" 0 "No Quality" ;
VAL_ 1340 RS_Obj28_ElevClass 3 "Relevant" 2 "Overridable" 1 "Underrunnable" 0 "Unknow" ;
VAL_ 1340 RS_Obj28_MotionPattern 7 "Reserved" 6 "Reserved" 5 "Reserved" 4 "Crossing" 3 "Moving" 2 "Stopped" 1 "Stationary" 0 "Unknown" ;
VAL_ 1340 RS_Obj28_ValidFlag 1 "Object valid" 0 "Object invalid" ;
VAL_ 1340 RS_Obj28_ID 255 "Invalid" ;
VAL_ 1339 RS_Obj27_MeasFlag 1 "Obj extrapolated in this cycle" 0 "Object measured in this cycle" ;
VAL_ 1339 RS_Obj27_Type 3 "Pedestrian" 2 "2 wheeler" 1 "4 wheeler" 0 "Unknown" ;
VAL_ 1339 RS_Obj27_ElevConf 3 "High Quality" 2 "Medium Quality" 1 "Low Quality" 0 "No Quality" ;
VAL_ 1339 RS_Obj27_ElevClass 3 "Relevant" 2 "Overridable" 1 "Underrunnable" 0 "Unknow" ;
VAL_ 1339 RS_Obj27_MotionPattern 7 "Reserved" 6 "Reserved" 5 "Reserved" 4 "Crossing" 3 "Moving" 2 "Stopped" 1 "Stationary" 0 "Unknown" ;
VAL_ 1339 RS_Obj27_ValidFlag 1 "Object valid" 0 "Object invalid" ;
VAL_ 1339 RS_Obj27_ID 255 "Invalid" ;
VAL_ 1338 RS_Obj26_MeasFlag 1 "Obj extrapolated in this cycle" 0 "Object measured in this cycle" ;
VAL_ 1338 RS_Obj26_Type 3 "Pedestrian" 2 "2 wheeler" 1 "4 wheeler" 0 "Unknown" ;
VAL_ 1338 RS_Obj26_ElevConf 3 "High Quality" 2 "Medium Quality" 1 "Low Quality" 0 "No Quality" ;
VAL_ 1338 RS_Obj26_ElevClass 3 "Relevant" 2 "Overridable" 1 "Underrunnable" 0 "Unknow" ;
VAL_ 1338 RS_Obj26_MotionPattern 7 "Reserved" 6 "Reserved" 5 "Reserved" 4 "Crossing" 3 "Moving" 2 "Stopped" 1 "Stationary" 0 "Unknown" ;
VAL_ 1338 RS_Obj26_ValidFlag 1 "Object valid" 0 "Object invalid" ;
VAL_ 1338 RS_Obj26_ID 255 "Invalid" ;
VAL_ 1337 RS_Obj25_MeasFlag 1 "Obj extrapolated in this cycle" 0 "Object measured in this cycle" ;
VAL_ 1337 RS_Obj25_Type 3 "Pedestrian" 2 "2 wheeler" 1 "4 wheeler" 0 "Unknown" ;
VAL_ 1337 RS_Obj25_ElevConf 3 "High Quality" 2 "Medium Quality" 1 "Low Quality" 0 "No Quality" ;
VAL_ 1337 RS_Obj25_ElevClass 3 "Relevant" 2 "Overridable" 1 "Underrunnable" 0 "Unknow" ;
VAL_ 1337 RS_Obj25_MotionPattern 7 "Reserved" 6 "Reserved" 5 "Reserved" 4 "Crossing" 3 "Moving" 2 "Stopped" 1 "Stationary" 0 "Unknown" ;
VAL_ 1337 RS_Obj25_ValidFlag 1 "Object valid" 0 "Object invalid" ;
VAL_ 1337 RS_Obj25_ID 255 "Invalid" ;
VAL_ 1336 RS_Obj24_MeasFlag 1 "Obj extrapolated in this cycle" 0 "Object measured in this cycle" ;
VAL_ 1336 RS_Obj24_Type 3 "Pedestrian" 2 "2 wheeler" 1 "4 wheeler" 0 "Unknown" ;
VAL_ 1336 RS_Obj24_ElevConf 3 "High Quality" 2 "Medium Quality" 1 "Low Quality" 0 "No Quality" ;
VAL_ 1336 RS_Obj24_ElevClass 3 "Relevant" 2 "Overridable" 1 "Underrunnable" 0 "Unknow" ;
VAL_ 1336 RS_Obj24_MotionPattern 7 "Reserved" 6 "Reserved" 5 "Reserved" 4 "Crossing" 3 "Moving" 2 "Stopped" 1 "Stationary" 0 "Unknown" ;
VAL_ 1336 RS_Obj24_ValidFlag 1 "Object valid" 0 "Object invalid" ;
VAL_ 1336 RS_Obj24_ID 255 "Invalid" ;
VAL_ 1335 RS_Obj23_MeasFlag 1 "Obj extrapolated in this cycle" 0 "Object measured in this cycle" ;
VAL_ 1335 RS_Obj23_Type 3 "Pedestrian" 2 "2 wheeler" 1 "4 wheeler" 0 "Unknown" ;
VAL_ 1335 RS_Obj23_ElevConf 3 "High Quality" 2 "Medium Quality" 1 "Low Quality" 0 "No Quality" ;
VAL_ 1335 RS_Obj23_ElevClass 3 "Relevant" 2 "Overridable" 1 "Underrunnable" 0 "Unknow" ;
VAL_ 1335 RS_Obj23_MotionPattern 7 "Reserved" 6 "Reserved" 5 "Reserved" 4 "Crossing" 3 "Moving" 2 "Stopped" 1 "Stationary" 0 "Unknown" ;
VAL_ 1335 RS_Obj23_ValidFlag 1 "Object valid" 0 "Object invalid" ;
VAL_ 1335 RS_Obj23_ID 255 "Invalid" ;
VAL_ 1334 RS_Obj22_MeasFlag 1 "Obj extrapolated in this cycle" 0 "Object measured in this cycle" ;
VAL_ 1334 RS_Obj22_Type 3 "Pedestrian" 2 "2 wheeler" 1 "4 wheeler" 0 "Unknown" ;
VAL_ 1334 RS_Obj22_ElevConf 3 "High Quality" 2 "Medium Quality" 1 "Low Quality" 0 "No Quality" ;
VAL_ 1334 RS_Obj22_ElevClass 3 "Relevant" 2 "Overridable" 1 "Underrunnable" 0 "Unknow" ;
VAL_ 1334 RS_Obj22_MotionPattern 7 "Reserved" 6 "Reserved" 5 "Reserved" 4 "Crossing" 3 "Moving" 2 "Stopped" 1 "Stationary" 0 "Unknown" ;
VAL_ 1334 RS_Obj22_ValidFlag 1 "Object valid" 0 "Object invalid" ;
VAL_ 1334 RS_Obj22_ID 255 "Invalid" ;
VAL_ 1333 RS_Obj21_MeasFlag 1 "Obj extrapolated in this cycle" 0 "Object measured in this cycle" ;
VAL_ 1333 RS_Obj21_Type 3 "Pedestrian" 2 "2 wheeler" 1 "4 wheeler" 0 "Unknown" ;
VAL_ 1333 RS_Obj21_ElevConf 3 "High Quality" 2 "Medium Quality" 1 "Low Quality" 0 "No Quality" ;
VAL_ 1333 RS_Obj21_ElevClass 3 "Relevant" 2 "Overridable" 1 "Underrunnable" 0 "Unknow" ;
VAL_ 1333 RS_Obj21_MotionPattern 7 "Reserved" 6 "Reserved" 5 "Reserved" 4 "Crossing" 3 "Moving" 2 "Stopped" 1 "Stationary" 0 "Unknown" ;
VAL_ 1333 RS_Obj21_ValidFlag 1 "Object valid" 0 "Object invalid" ;
VAL_ 1333 RS_Obj21_ID 255 "Invalid" ;
VAL_ 1332 RS_Obj20_MeasFlag 1 "Obj extrapolated in this cycle" 0 "Object measured in this cycle" ;
VAL_ 1332 RS_Obj20_Type 3 "Pedestrian" 2 "2 wheeler" 1 "4 wheeler" 0 "Unknown" ;
VAL_ 1332 RS_Obj20_ElevConf 3 "High Quality" 2 "Medium Quality" 1 "Low Quality" 0 "No Quality" ;
VAL_ 1332 RS_Obj20_ElevClass 3 "Relevant" 2 "Overridable" 1 "Underrunnable" 0 "Unknow" ;
VAL_ 1332 RS_Obj20_MotionPattern 7 "Reserved" 6 "Reserved" 5 "Reserved" 4 "Crossing" 3 "Moving" 2 "Stopped" 1 "Stationary" 0 "Unknown" ;
VAL_ 1332 RS_Obj20_ValidFlag 1 "Object valid" 0 "Object invalid" ;
VAL_ 1332 RS_Obj20_ID 255 "Invalid" ;
VAL_ 1331 RS_Obj19_MeasFlag 1 "Obj extrapolated in this cycle" 0 "Object measured in this cycle" ;
VAL_ 1331 RS_Obj19_Type 3 "Pedestrian" 2 "2 wheeler" 1 "4 wheeler" 0 "Unknown" ;
VAL_ 1331 RS_Obj19_ElevConf 3 "High Quality" 2 "Medium Quality" 1 "Low Quality" 0 "No Quality" ;
VAL_ 1331 RS_Obj19_ElevClass 3 "Relevant" 2 "Overridable" 1 "Underrunnable" 0 "Unknow" ;
VAL_ 1331 RS_Obj19_MotionPattern 7 "Reserved" 6 "Reserved" 5 "Reserved" 4 "Crossing" 3 "Moving" 2 "Stopped" 1 "Stationary" 0 "Unknown" ;
VAL_ 1331 RS_Obj19_ValidFlag 1 "Object valid" 0 "Object invalid" ;
VAL_ 1331 RS_Obj19_ID 255 "Invalid" ;
VAL_ 1330 RS_Obj18_MeasFlag 1 "Obj extrapolated in this cycle" 0 "Object measured in this cycle" ;
VAL_ 1330 RS_Obj18_Type 3 "Pedestrian" 2 "2 wheeler" 1 "4 wheeler" 0 "Unknown" ;
VAL_ 1330 RS_Obj18_ElevConf 3 "High Quality" 2 "Medium Quality" 1 "Low Quality" 0 "No Quality" ;
VAL_ 1330 RS_Obj18_ElevClass 3 "Relevant" 2 "Overridable" 1 "Underrunnable" 0 "Unknow" ;
VAL_ 1330 RS_Obj18_MotionPattern 7 "Reserved" 6 "Reserved" 5 "Reserved" 4 "Crossing" 3 "Moving" 2 "Stopped" 1 "Stationary" 0 "Unknown" ;
VAL_ 1330 RS_Obj18_ValidFlag 1 "Object valid" 0 "Object invalid" ;
VAL_ 1330 RS_Obj18_ID 255 "Invalid" ;
VAL_ 1329 RS_Obj17_MeasFlag 1 "Obj extrapolated in this cycle" 0 "Object measured in this cycle" ;
VAL_ 1329 RS_Obj17_Type 3 "Pedestrian" 2 "2 wheeler" 1 "4 wheeler" 0 "Unknown" ;
VAL_ 1329 RS_Obj17_ElevConf 3 "High Quality" 2 "Medium Quality" 1 "Low Quality" 0 "No Quality" ;
VAL_ 1329 RS_Obj17_ElevClass 3 "Relevant" 2 "Overridable" 1 "Underrunnable" 0 "Unknow" ;
VAL_ 1329 RS_Obj17_MotionPattern 7 "Reserved" 6 "Reserved" 5 "Reserved" 4 "Crossing" 3 "Moving" 2 "Stopped" 1 "Stationary" 0 "Unknown" ;
VAL_ 1329 RS_Obj17_ValidFlag 1 "Object valid" 0 "Object invalid" ;
VAL_ 1329 RS_Obj17_ID 255 "Invalid" ;
VAL_ 1328 RS_Obj16_MeasFlag 1 "Obj extrapolated in this cycle" 0 "Object measured in this cycle" ;
VAL_ 1328 RS_Obj16_Type 3 "Pedestrian" 2 "2 wheeler" 1 "4 wheeler" 0 "Unknown" ;
VAL_ 1328 RS_Obj16_ElevConf 3 "High Quality" 2 "Medium Quality" 1 "Low Quality" 0 "No Quality" ;
VAL_ 1328 RS_Obj16_ElevClass 3 "Relevant" 2 "Overridable" 1 "Underrunnable" 0 "Unknow" ;
VAL_ 1328 RS_Obj16_MotionPattern 7 "Reserved" 6 "Reserved" 5 "Reserved" 4 "Crossing" 3 "Moving" 2 "Stopped" 1 "Stationary" 0 "Unknown" ;
VAL_ 1328 RS_Obj16_ValidFlag 1 "Object valid" 0 "Object invalid" ;
VAL_ 1328 RS_Obj16_ID 255 "Invalid" ;
VAL_ 1327 RS_Obj15_MeasFlag 1 "Obj extrapolated in this cycle" 0 "Object measured in this cycle" ;
VAL_ 1327 RS_Obj15_Type 3 "Pedestrian" 2 "2 wheeler" 1 "4 wheeler" 0 "Unknown" ;
VAL_ 1327 RS_Obj15_ElevConf 3 "High Quality" 2 "Medium Quality" 1 "Low Quality" 0 "No Quality" ;
VAL_ 1327 RS_Obj15_ElevClass 3 "Relevant" 2 "Overridable" 1 "Underrunnable" 0 "Unknow" ;
VAL_ 1327 RS_Obj15_MotionPattern 7 "Reserved" 6 "Reserved" 5 "Reserved" 4 "Crossing" 3 "Moving" 2 "Stopped" 1 "Stationary" 0 "Unknown" ;
VAL_ 1327 RS_Obj15_ValidFlag 1 "Object valid" 0 "Object invalid" ;
VAL_ 1327 RS_Obj15_ID 255 "Invalid" ;
VAL_ 1326 RS_Obj14_MeasFlag 1 "Obj extrapolated in this cycle" 0 "Object measured in this cycle" ;
VAL_ 1326 RS_Obj14_Type 3 "Pedestrian" 2 "2 wheeler" 1 "4 wheeler" 0 "Unknown" ;
VAL_ 1326 RS_Obj14_ElevConf 3 "High Quality" 2 "Medium Quality" 1 "Low Quality" 0 "No Quality" ;
VAL_ 1326 RS_Obj14_ElevClass 3 "Relevant" 2 "Overridable" 1 "Underrunnable" 0 "Unknow" ;
VAL_ 1326 RS_Obj14_MotionPattern 7 "Reserved" 6 "Reserved" 5 "Reserved" 4 "Crossing" 3 "Moving" 2 "Stopped" 1 "Stationary" 0 "Unknown" ;
VAL_ 1326 RS_Obj14_ValidFlag 1 "Object valid" 0 "Object invalid" ;
VAL_ 1326 RS_Obj14_ID 255 "Invalid" ;
VAL_ 1325 RS_Obj13_MeasFlag 1 "Obj extrapolated in this cycle" 0 "Object measured in this cycle" ;
VAL_ 1325 RS_Obj13_Type 3 "Pedestrian" 2 "2 wheeler" 1 "4 wheeler" 0 "Unknown" ;
VAL_ 1325 RS_Obj13_ElevConf 3 "High Quality" 2 "Medium Quality" 1 "Low Quality" 0 "No Quality" ;
VAL_ 1325 RS_Obj13_ElevClass 3 "Relevant" 2 "Overridable" 1 "Underrunnable" 0 "Unknow" ;
VAL_ 1325 RS_Obj13_MotionPattern 7 "Reserved" 6 "Reserved" 5 "Reserved" 4 "Crossing" 3 "Moving" 2 "Stopped" 1 "Stationary" 0 "Unknown" ;
VAL_ 1325 RS_Obj13_ValidFlag 1 "Object valid" 0 "Object invalid" ;
VAL_ 1325 RS_Obj13_ID 255 "Invalid" ;
VAL_ 1324 RS_Obj12_MeasFlag 1 "Obj extrapolated in this cycle" 0 "Object measured in this cycle" ;
VAL_ 1324 RS_Obj12_Type 3 "Pedestrian" 2 "2 wheeler" 1 "4 wheeler" 0 "Unknown" ;
VAL_ 1324 RS_Obj12_ElevConf 3 "High Quality" 2 "Medium Quality" 1 "Low Quality" 0 "No Quality" ;
VAL_ 1324 RS_Obj12_ElevClass 3 "Relevant" 2 "Overridable" 1 "Underrunnable" 0 "Unknow" ;
VAL_ 1324 RS_Obj12_MotionPattern 7 "Reserved" 6 "Reserved" 5 "Reserved" 4 "Crossing" 3 "Moving" 2 "Stopped" 1 "Stationary" 0 "Unknown" ;
VAL_ 1324 RS_Obj12_ValidFlag 1 "Object valid" 0 "Object invalid" ;
VAL_ 1324 RS_Obj12_ID 255 "Invalid" ;
VAL_ 1323 RS_Obj11_MeasFlag 1 "Obj extrapolated in this cycle" 0 "Object measured in this cycle" ;
VAL_ 1323 RS_Obj11_Type 3 "Pedestrian" 2 "2 wheeler" 1 "4 wheeler" 0 "Unknown" ;
VAL_ 1323 RS_Obj11_ElevConf 3 "High Quality" 2 "Medium Quality" 1 "Low Quality" 0 "No Quality" ;
VAL_ 1323 RS_Obj11_ElevClass 3 "Relevant" 2 "Overridable" 1 "Underrunnable" 0 "Unknow" ;
VAL_ 1323 RS_Obj11_MotionPattern 7 "Reserved" 6 "Reserved" 5 "Reserved" 4 "Crossing" 3 "Moving" 2 "Stopped" 1 "Stationary" 0 "Unknown" ;
VAL_ 1323 RS_Obj11_ValidFlag 1 "Object valid" 0 "Object invalid" ;
VAL_ 1323 RS_Obj11_ID 255 "Invalid" ;
VAL_ 1322 RS_Obj10_MeasFlag 1 "Obj extrapolated in this cycle" 0 "Object measured in this cycle" ;
VAL_ 1322 RS_Obj10_Type 3 "Pedestrian" 2 "2 wheeler" 1 "4 wheeler" 0 "Unknown" ;
VAL_ 1322 RS_Obj10_ElevConf 3 "High Quality" 2 "Medium Quality" 1 "Low Quality" 0 "No Quality" ;
VAL_ 1322 RS_Obj10_ElevClass 3 "Relevant" 2 "Overridable" 1 "Underrunnable" 0 "Unknow" ;
VAL_ 1322 RS_Obj10_MotionPattern 7 "Reserved" 6 "Reserved" 5 "Reserved" 4 "Crossing" 3 "Moving" 2 "Stopped" 1 "Stationary" 0 "Unknown" ;
VAL_ 1322 RS_Obj10_ValidFlag 1 "Object valid" 0 "Object invalid" ;
VAL_ 1322 RS_Obj10_ID 255 "Invalid" ;
VAL_ 1321 RS_Obj09_MeasFlag 1 "Obj extrapolated in this cycle" 0 "Object measured in this cycle" ;
VAL_ 1321 RS_Obj09_Type 3 "Pedestrian" 2 "2 wheeler" 1 "4 wheeler" 0 "Unknown" ;
VAL_ 1321 RS_Obj09_ElevConf 3 "High Quality" 2 "Medium Quality" 1 "Low Quality" 0 "No Quality" ;
VAL_ 1321 RS_Obj09_ElevClass 3 "Relevant" 2 "Overridable" 1 "Underrunnable" 0 "Unknow" ;
VAL_ 1321 RS_Obj09_MotionPattern 7 "Reserved" 6 "Reserved" 5 "Reserved" 4 "Crossing" 3 "Moving" 2 "Stopped" 1 "Stationary" 0 "Unknown" ;
VAL_ 1321 RS_Obj09_ValidFlag 1 "Object valid" 0 "Object invalid" ;
VAL_ 1321 RS_Obj09_ID 255 "Invalid" ;
VAL_ 1320 RS_Obj08_MeasFlag 1 "Obj extrapolated in this cycle" 0 "Object measured in this cycle" ;
VAL_ 1320 RS_Obj08_Type 3 "Pedestrian" 2 "2 wheeler" 1 "4 wheeler" 0 "Unknown" ;
VAL_ 1320 RS_Obj08_ElevConf 3 "High Quality" 2 "Medium Quality" 1 "Low Quality" 0 "No Quality" ;
VAL_ 1320 RS_Obj08_ElevClass 3 "Relevant" 2 "Overridable" 1 "Underrunnable" 0 "Unknow" ;
VAL_ 1320 RS_Obj08_MotionPattern 7 "Reserved" 6 "Reserved" 5 "Reserved" 4 "Crossing" 3 "Moving" 2 "Stopped" 1 "Stationary" 0 "Unknown" ;
VAL_ 1320 RS_Obj08_ValidFlag 1 "Object valid" 0 "Object invalid" ;
VAL_ 1320 RS_Obj08_ID 255 "Invalid" ;
VAL_ 1319 RS_Obj07_MeasFlag 1 "Obj extrapolated in this cycle" 0 "Object measured in this cycle" ;
VAL_ 1319 RS_Obj07_Type 3 "Pedestrian" 2 "2 wheeler" 1 "4 wheeler" 0 "Unknown" ;
VAL_ 1319 RS_Obj07_ElevConf 3 "High Quality" 2 "Medium Quality" 1 "Low Quality" 0 "No Quality" ;
VAL_ 1319 RS_Obj07_ElevClass 3 "Relevant" 2 "Overridable" 1 "Underrunnable" 0 "Unknow" ;
VAL_ 1319 RS_Obj07_MotionPattern 7 "Reserved" 6 "Reserved" 5 "Reserved" 4 "Crossing" 3 "Moving" 2 "Stopped" 1 "Stationary" 0 "Unknown" ;
VAL_ 1319 RS_Obj07_ValidFlag 1 "Object valid" 0 "Object invalid" ;
VAL_ 1319 RS_Obj07_ID 255 "Invalid" ;
VAL_ 1318 RS_Obj06_MeasFlag 1 "Obj extrapolated in this cycle" 0 "Object measured in this cycle" ;
VAL_ 1318 RS_Obj06_Type 3 "Pedestrian" 2 "2 wheeler" 1 "4 wheeler" 0 "Unknown" ;
VAL_ 1318 RS_Obj06_ElevConf 3 "High Quality" 2 "Medium Quality" 1 "Low Quality" 0 "No Quality" ;
VAL_ 1318 RS_Obj06_ElevClass 3 "Relevant" 2 "Overridable" 1 "Underrunnable" 0 "Unknow" ;
VAL_ 1318 RS_Obj06_MotionPattern 7 "Reserved" 6 "Reserved" 5 "Reserved" 4 "Crossing" 3 "Moving" 2 "Stopped" 1 "Stationary" 0 "Unknown" ;
VAL_ 1318 RS_Obj06_ValidFlag 1 "Object valid" 0 "Object invalid" ;
VAL_ 1318 RS_Obj06_ID 255 "Invalid" ;
VAL_ 1317 RS_Obj05_MeasFlag 1 "Obj extrapolated in this cycle" 0 "Object measured in this cycle" ;
VAL_ 1317 RS_Obj05_Type 3 "Pedestrian" 2 "2 wheeler" 1 "4 wheeler" 0 "Unknown" ;
VAL_ 1317 RS_Obj05_ElevConf 3 "High Quality" 2 "Medium Quality" 1 "Low Quality" 0 "No Quality" ;
VAL_ 1317 RS_Obj05_ElevClass 3 "Relevant" 2 "Overridable" 1 "Underrunnable" 0 "Unknow" ;
VAL_ 1317 RS_Obj05_MotionPattern 7 "Reserved" 6 "Reserved" 5 "Reserved" 4 "Crossing" 3 "Moving" 2 "Stopped" 1 "Stationary" 0 "Unknown" ;
VAL_ 1317 RS_Obj05_ValidFlag 1 "Object valid" 0 "Object invalid" ;
VAL_ 1317 RS_Obj05_ID 8191 "Invalid" ;
VAL_ 1316 RS_Obj04_MeasFlag 1 "Obj extrapolated in this cycle" 0 "Object measured in this cycle" ;
VAL_ 1316 RS_Obj04_Type 3 "Pedestrian" 2 "2 wheeler" 1 "4 wheeler" 0 "Unknown" ;
VAL_ 1316 RS_Obj04_ElevConf 3 "High Quality" 2 "Medium Quality" 1 "Low Quality" 0 "No Quality" ;
VAL_ 1316 RS_Obj04_ElevClass 3 "Relevant" 2 "Overridable" 1 "Underrunnable" 0 "Unknow" ;
VAL_ 1316 RS_Obj04_MotionPattern 7 "Reserved" 6 "Reserved" 5 "Reserved" 4 "Crossing" 3 "Moving" 2 "Stopped" 1 "Stationary" 0 "Unknown" ;
VAL_ 1316 RS_Obj04_ValidFlag 1 "Object valid" 0 "Object invalid" ;
VAL_ 1316 RS_Obj04_ID 8191 "Invalid" ;
VAL_ 1315 RS_Obj03_MeasFlag 1 "Obj extrapolated in this cycle" 0 "Object measured in this cycle" ;
VAL_ 1315 RS_Obj03_Type 3 "Pedestrian" 2 "2 wheeler" 1 "4 wheeler" 0 "Unknown" ;
VAL_ 1315 RS_Obj03_ElevConf 3 "High Quality" 2 "Medium Quality" 1 "Low Quality" 0 "No Quality" ;
VAL_ 1315 RS_Obj03_ElevClass 3 "Relevant" 2 "Overridable" 1 "Underrunnable" 0 "Unknow" ;
VAL_ 1315 RS_Obj03_MotionPattern 7 "Reserved" 6 "Reserved" 5 "Reserved" 4 "Crossing" 3 "Moving" 2 "Stopped" 1 "Stationary" 0 "Unknown" ;
VAL_ 1315 RS_Obj03_ValidFlag 1 "Object valid" 0 "Object invalid" ;
VAL_ 1315 RS_Obj03_ID 8191 "Invalid" ;
VAL_ 1314 RS_Obj02_MeasFlag 1 "Obj extrapolated in this cycle" 0 "Object measured in this cycle" ;
VAL_ 1314 RS_Obj02_Type 3 "Pedestrian" 2 "2 wheeler" 1 "4 wheeler" 0 "Unknown" ;
VAL_ 1314 RS_Obj02_ElevConf 3 "High Quality" 2 "Medium Quality" 1 "Low Quality" 0 "No Quality" ;
VAL_ 1314 RS_Obj02_ElevClass 3 "Relevant" 2 "Overridable" 1 "Underrunnable" 0 "Unknow" ;
VAL_ 1314 RS_Obj02_MotionPattern 7 "Reserved" 6 "Reserved" 5 "Reserved" 4 "Crossing" 3 "Moving" 2 "Stopped" 1 "Stationary" 0 "Unknown" ;
VAL_ 1314 RS_Obj02_ValidFlag 1 "Object valid" 0 "Object invalid" ;
VAL_ 1314 RS_Obj02_ID 8191 "Invalid" ;
VAL_ 1313 RS_Obj01_MeasFlag 1 "Obj extrapolated in this cycle" 0 "Object measured in this cycle" ;
VAL_ 1313 RS_Obj01_Type 3 "Pedestrian" 2 "2 wheeler" 1 "4 wheeler" 0 "Unknown" ;
VAL_ 1313 RS_Obj01_ElevConf 3 "High Quality" 2 "Medium Quality" 1 "Low Quality" 0 "No Quality" ;
VAL_ 1313 RS_Obj01_ElevClass 3 "Relevant" 2 "Overridable" 1 "Underrunnable" 0 "Unknow" ;
VAL_ 1313 RS_Obj01_MotionPattern 7 "Reserved" 6 "Reserved" 5 "Reserved" 4 "Crossing" 3 "Moving" 2 "Stopped" 1 "Stationary" 0 "Unknown" ;
VAL_ 1313 RS_Obj01_ValidFlag 1 "Object valid" 0 "Object invalid" ;
VAL_ 1313 RS_Obj01_ID 8191 "Invalid" ;
VAL_ 1360 RS_Obj00_CtrkInd 1 "Cluster tracker" 0 "Stationary tracker" ;
VAL_ 1312 RS_Obj00_MeasFlag 1 "Obj extrapolated in this cycle" 0 "Object measured in this cycle" ;
VAL_ 1312 RS_Obj00_Type 3 "Pedestrian" 2 "2 wheeler" 1 "4 wheeler" 0 "Unknown" ;
VAL_ 1312 RS_Obj00_ElevConf 3 "High Quality" 2 "Medium Quality" 1 "Low Quality" 0 "No Quality" ;
VAL_ 1312 RS_Obj00_ElevClass 3 "Relevant" 2 "Overridable" 1 "Underrunnable" 0 "Unknow" ;
VAL_ 1312 RS_Obj00_MotionPattern 7 "Reserved" 6 "Reserved" 5 "Reserved" 4 "Reserved" 3 "Moving" 2 "Stopped" 1 "Stationary" 0 "Unknown" ;
VAL_ 1312 RS_Obj00_ValidFlag 1 "Object valid" 0 "Object invalid" ;
VAL_ 1312 RS_Obj00_ID 8191 "Invalid" ;
VAL_ 1472 RS_Warn_RCW 2 "Warning Level 2" 1 "Warning Level 1" 0 "No Warning" ;
VAL_ 1472 RS_Warn_SDO 2 "Warning Level 2" 1 "Warning Level 1" 0 "No Warning" ;
VAL_ 1472 RS_Warn_RCTA 2 "Warning Level 2" 1 "Warning Level 1" 0 "No Warning" ;
VAL_ 1472 RS_Warn_LCA 2 "Warning Level 2" 1 "Warning Level 1" 0 "No Warning" ;
VAL_ 1472 RS_Warn_BSD 2 "Warning Level 2" 1 "Warning Level 1" 0 "No Warning" ;
VAL_ 1472 RS_Sts_Interference 1 "RS is interfered" 0 "RS is not interfered" ;
VAL_ 1472 RS_Sts_Blkg 1 "RS is blocked" 0 "RS is NOT blocked" ;
VAL_ 1472 RS_Sts_MisAlign 5 "reserved" 4 "reserved" 3 "Sensor Misalignment Detected" 2 "Sensor Calibrated" 1 "Sensor Not Calibrated" 0 "Sensor In Default Condition" ;
VAL_ 1472 RS_Sts_Failure 1 "Sensor Failure Occurred" 0 "No Sensor Failure Occured" ;
VAL_ 1074 RS_AWB 1 "Active Wakeup" 0 "Passive wakeup" ;
VAL_ 1074 RS_RMR 1 "Repeat Msg State requested" 0 "Repeat Msg State not requested" ;
VAL_ 1074 RS_NMSts 1 "Normal Operation State" 0 "Repeat Message State" ;
VAL_ 1074 RS_Wakeup_reasons 6 "Description for the value '0x6'" 5 "Description for the value '0x5'" 4 "Description for the value '0x4'" 3 "Description for the value '0x3'" 2 "NM PDU Received" 1 "Description for the value '0x1'" 0 "Default" ;
VAL_ 357 VCU_CurrentGearPosition 15 "Invalid" 12 "Current gear D" 11 "Current gear Reverse" 10 "Park" 0 "Current gear N" ;
VAL_ 304 YRS_LateralSensorState 3 "Initializing" 2 "Reserved" 1 "Invalid" 0 "Valid" ;
VAL_ 304 YRS_LateralAcce 65535 "Invalid" ;
VAL_ 304 YRS_YawRate 65535 "Invalid" ;
VAL_ 304 YRS_YawRateSensorState 3 "Initializing" 2 "Reserved" 1 "Invalid" 0 "Valid" ;
VAL_ 305 YRS_LongitSensorState 3 "Initializing" 2 "Reserved" 1 "Invalid" 0 "Valid" ;
VAL_ 305 YRS_LongitAcce 65535 "Invalid" ;
VAL_ 224 SAS_FailureSts 1 "Valid" 0 "Invalid" ;
VAL_ 224 SAS_SteerWheelAngle 32767 "Invalid" ;
VAL_ 293 ESC_VehicleSpeedInvalid 1 "Invalid" 0 "Valid" ;
VAL_ 293 ESC_VehicleSpeed 8190 "Abnormal" 8191 "Invalid value" ;
VAL_ 133 EMS_EngStatus 7 "Invalid" 6 "Abnormal" 5 "Reserved" 4 "Reserved" 3 "Running" 2 "Stopping" 1 "Cranking" 0 "Engine Stop" ;
VAL_ 275 TCU_CurrentGearPosition 15 "Invalid" 11 "Current gear Reverse" 10 "Park" 7 "Current gear 7(6AT Reserved)" 6 "Current gear 6" 5 "Current gear 5" 4 "Current gear 4" 3 "Current gear 3" 2 "Current gear 2" 1 "Current gear 1" 0 "Current gear N" ;
VAL_ 1009 IPK_IPKTotalOdometer 16777214 "Abnormal" 16777215 "Invalid" ;
SIG_GROUP_ 482 PowerMode_Grp 1 : PEPS_Message_Sts_AliveCounter PEPS_Message_Sts_Checksum PEPS_PowerModeValidity PEPS_PowerMode;
SIG_GROUP_ 646 RDoorSts_Grp 1 : BCM_DoorLockStatusRR BCM_DoorLockStatusPass BCM_RearRightDoorAjarStatus BCM_FrontRightDoorAjarStatus;
SIG_GROUP_ 645 LDoorSts_Grp 1 : BCM_DoorLockStatusRL BCM_DoorLockStatusDrv BCM_RearLeftDoorAjarStatus BCM_FrontLeftDoorAjarStatus;
SIG_GROUP_ 496 TurnLever_Grp 1 : BCM_LightChimeReq_CheckSum BCM_LightChimeReq_AliveCounter BCM_TurnLeverSts;
SIG_GROUP_ 1518 Detn14Part02_Grp 1 : RS_Detn14_Elev RS_Detn14_YVelRel RS_Detn14_XVelRel RS_Detn14_Msg02_AliveCounter RS_Detn14_Msg02_CheckSum RS_Detn14_MotnSts RS_Detn14_Qly;
SIG_GROUP_ 1501 Detn13Part01_Grp 1 : RS_Detn13_Magn RS_Detn13_Msg01_AliveCounter RS_Detn13_Msg01_CheckSum RS_Detn13_PosY RS_Detn13_ID RS_Detn13_PosX;
SIG_GROUP_ 1515 Detn11Part02_Grp 1 : RS_Detn11_Elev RS_Detn11_YVelRel RS_Detn11_XVelRel RS_Detn11_Msg02_CheckSum RS_Detn11_Msg02_AliveCounter RS_Detn11_MotnSts RS_Detn11_Qly;
SIG_GROUP_ 1498 Detn10Part01_Grp 1 : RS_Detn10_Magn RS_Detn10_Msg01_AliveCounter RS_Detn10_Msg01_CheckSum RS_Detn10_PosX RS_Detn10_ID RS_Detn10_PosY;
SIG_GROUP_ 1512 Detn08Part02_Grp 1 : RS_Detn08_Elev RS_Detn08_YVelRel RS_Detn08_XVelRel RS_Detn08_Msg02_CheckSum RS_Detn08_Msg02_AliveCounter RS_Detn08_MotnSts RS_Detn08_Qly;
SIG_GROUP_ 1495 Detn07Part01_Grp 1 : RS_Detn07_Magn RS_Detn07_Msg01_CheckSum RS_Detn07_Msg01_AliveCounter RS_Detn07_PosY RS_Detn07_ID RS_Detn07_PosX;
SIG_GROUP_ 1509 Detn05Part02_Grp 1 : RS_Detn05_Elev RS_Detn05_XVelRel RS_Detn05_YVelRel RS_Detn05_Msg02_CheckSum RS_Detn05_Msg02_AliveCounter RS_Detn05_MotnSts RS_Detn05_Qly;
SIG_GROUP_ 1492 Detn04Part01_Grp 1 : RS_Detn04_Magn RS_Detn04_Msg01_CheckSum RS_Detn04_Msg01_AliveCounter RS_Detn04_PosY RS_Detn04_ID RS_Detn04_PosX;
SIG_GROUP_ 1506 Detn02Part02_Grp 1 : RS_Detn02_Elev RS_Detn02_YVelRel RS_Detn02_XVelRel RS_Detn02_Msg02_AliveCounter RS_Detn02_Msg02_CheckSum RS_Detn02_Qly RS_Detn02_MotnSts;
SIG_GROUP_ 1489 Detn01Part01_Grp 1 : RS_Detn01_Magn RS_Detn01_Msg01_CheckSum RS_Detn01_Msg01_AliveCounter RS_Detn01_PosY RS_Detn01_ID RS_Detn01_PosX;
SIG_GROUP_ 1453 Obj29Part03_Grp 1 : RS_Obj29_Msg03_CheckSum RS_Obj29_Msg03_AliveCounter RS_Obj29_XPos_Stdev RS_Obj29_YPos_Stdev RS_Obj29_XVelRel_Stdev RS_Obj29_YVelRel_Stdev RS_Obj29_XAccRel_Stdev RS_Obj29_YAccRel_Stdev RS_Obj29_ExstProb;
SIG_GROUP_ 1452 Obj28Part03_Grp 1 : RS_Obj28_Msg03_CheckSum RS_Obj28_Msg03_AliveCounter RS_Obj28_XPos_Stdev RS_Obj28_YPos_Stdev RS_Obj28_XVelRel_Stdev RS_Obj28_YVelRel_Stdev RS_Obj28_XAccRel_Stdev RS_Obj28_YAccRel_Stdev RS_Obj28_ExstProb;
SIG_GROUP_ 1451 Obj27Part03_Grp 1 : RS_Obj27_Msg03_CheckSum RS_Obj27_Msg03_AliveCounter RS_Obj27_XPos_Stdev RS_Obj27_YPos_Stdev RS_Obj27_XVelRel_Stdev RS_Obj27_YVelRel_Stdev RS_Obj27_XAccRel_Stdev RS_Obj27_YAccRel_Stdev RS_Obj27_ExstProb;
SIG_GROUP_ 1450 Obj26Part03_Grp 1 : RS_Obj26_Msg03_CheckSum RS_Obj26_Msg03_AliveCounter RS_Obj26_XPos_Stdev RS_Obj26_YPos_Stdev RS_Obj26_XVelRel_Stdev RS_Obj26_YVelRel_Stdev RS_Obj26_XAccRel_Stdev RS_Obj26_YAccRel_Stdev RS_Obj26_ExstProb;
SIG_GROUP_ 1449 Obj25Part03_Grp 1 : RS_Obj25_Msg03_CheckSum RS_Obj25_Msg03_AliveCounter RS_Obj25_XPos_Stdev RS_Obj25_YPos_Stdev RS_Obj25_XVelRel_Stdev RS_Obj25_YVelRel_Stdev RS_Obj25_XAccRel_Stdev RS_Obj25_YAccRel_Stdev RS_Obj25_ExstProb;
SIG_GROUP_ 1448 Obj24Part03_Grp 1 : RS_Obj24_Msg03_CheckSum RS_Obj24_Msg03_AliveCounter RS_Obj24_XPos_Stdev RS_Obj24_YPos_Stdev RS_Obj24_XVelRel_Stdev RS_Obj24_YVelRel_Stdev RS_Obj24_XAccRel_Stdev RS_Obj24_YAccRel_Stdev RS_Obj24_ExstProb;
SIG_GROUP_ 1447 Obj23Part03_Grp 1 : RS_Obj23_Msg03_CheckSum RS_Obj23_Msg03_AliveCounter RS_Obj23_XPos_Stdev RS_Obj23_YPos_Stdev RS_Obj23_XVelRel_Stdev RS_Obj23_YVelRel_Stdev RS_Obj23_XAccRel_Stdev RS_Obj23_YAccRel_Stdev RS_Obj23_ExstProb;
SIG_GROUP_ 1446 Obj22Part03_Grp 1 : RS_Obj22_Msg03_CheckSum RS_Obj22_Msg03_AliveCounter RS_Obj22_XPos_Stdev RS_Obj22_YPos_Stdev RS_Obj22_XVelRel_Stdev RS_Obj22_YVelRel_Stdev RS_Obj22_XAccRel_Stdev RS_Obj22_YAccRel_Stdev RS_Obj22_ExstProb;
SIG_GROUP_ 1445 Obj21Part03_Grp 1 : RS_Obj21_Msg03_CheckSum RS_Obj21_Msg03_AliveCounter RS_Obj21_XPos_Stdev RS_Obj21_YPos_Stdev RS_Obj21_XVelRel_Stdev RS_Obj21_YVelRel_Stdev RS_Obj21_XAccRel_Stdev RS_Obj21_YAccRel_Stdev RS_Obj21_ExstProb;
SIG_GROUP_ 1444 Obj20Part03_Grp 1 : RS_Obj20_Msg03_CheckSum RS_Obj20_Msg03_AliveCounter RS_Obj20_XPos_Stdev RS_Obj20_YPos_Stdev RS_Obj20_XVelRel_Stdev RS_Obj20_YVelRel_Stdev RS_Obj20_XAccRel_Stdev RS_Obj20_YAccRel_Stdev RS_Obj20_ExstProb;
SIG_GROUP_ 1443 Obj19Part03_Grp 1 : RS_Obj19_Msg03_CheckSum RS_Obj19_Msg03_AliveCounter RS_Obj19_XPos_Stdev RS_Obj19_YPos_Stdev RS_Obj19_XVelRel_Stdev RS_Obj19_YVelRel_Stdev RS_Obj19_XAccRel_Stdev RS_Obj19_YAccRel_Stdev RS_Obj19_ExstProb;
SIG_GROUP_ 1442 Obj18Part03_Grp 1 : RS_Obj18_Msg03_CheckSum RS_Obj18_Msg03_AliveCounter RS_Obj18_XPos_Stdev RS_Obj18_YPos_Stdev RS_Obj18_XVelRel_Stdev RS_Obj18_YVelRel_Stdev RS_Obj18_XAccRel_Stdev RS_Obj18_YAccRel_Stdev RS_Obj18_ExstProb;
SIG_GROUP_ 1441 Obj17Part03_Grp 1 : RS_Obj17_Msg03_CheckSum RS_Obj17_Msg03_AliveCounter RS_Obj17_XPos_Stdev RS_Obj17_YPos_Stdev RS_Obj17_XVelRel_Stdev RS_Obj17_YVelRel_Stdev RS_Obj17_XAccRel_Stdev RS_Obj17_YAccRel_Stdev RS_Obj17_ExstProb;
SIG_GROUP_ 1440 Obj16Part03_Grp 1 : RS_Obj16_Msg03_CheckSum RS_Obj16_Msg03_AliveCounter RS_Obj16_XPos_Stdev RS_Obj16_YPos_Stdev RS_Obj16_XVelRel_Stdev RS_Obj16_YVelRel_Stdev RS_Obj16_XAccRel_Stdev RS_Obj16_YAccRel_Stdev RS_Obj16_ExstProb;
SIG_GROUP_ 1439 Obj15Part03_Grp 1 : RS_Obj15_Msg03_CheckSum RS_Obj15_Msg03_AliveCounter RS_Obj15_XPos_Stdev RS_Obj15_YPos_Stdev RS_Obj15_XVelRel_Stdev RS_Obj15_YVelRel_Stdev RS_Obj15_XAccRel_Stdev RS_Obj15_YAccRel_Stdev RS_Obj15_ExstProb;
SIG_GROUP_ 1438 Obj14Part03_Grp 1 : RS_Obj14_Msg03_CheckSum RS_Obj14_Msg03_AliveCounter RS_Obj14_XPos_Stdev RS_Obj14_YPos_Stdev RS_Obj14_XVelRel_Stdev RS_Obj14_YVelRel_Stdev RS_Obj14_XAccRel_Stdev RS_Obj14_YAccRel_Stdev RS_Obj14_ExstProb;
SIG_GROUP_ 1437 Obj13Part03_Grp 1 : RS_Obj13_Msg03_CheckSum RS_Obj13_Msg03_AliveCounter RS_Obj13_XPos_Stdev RS_Obj13_YPos_Stdev RS_Obj13_XVelRel_Stdev RS_Obj13_YVelRel_Stdev RS_Obj13_XAccRel_Stdev RS_Obj13_YAccRel_Stdev RS_Obj13_ExstProb;
SIG_GROUP_ 1436 Obj12Part03_Grp 1 : RS_Obj12_Msg03_CheckSum RS_Obj12_Msg03_AliveCounter RS_Obj12_XPos_Stdev RS_Obj12_YPos_Stdev RS_Obj12_XVelRel_Stdev RS_Obj12_YVelRel_Stdev RS_Obj12_XAccRel_Stdev RS_Obj12_YAccRel_Stdev RS_Obj12_ExstProb;
SIG_GROUP_ 1435 Obj11Part03_Grp 1 : RS_Obj11_Msg03_CheckSum RS_Obj11_Msg03_AliveCounter RS_Obj11_XPos_Stdev RS_Obj11_YPos_Stdev RS_Obj11_XVelRel_Stdev RS_Obj11_YVelRel_Stdev RS_Obj11_XAccRel_Stdev RS_Obj11_YAccRel_Stdev RS_Obj11_ExstProb;
SIG_GROUP_ 1434 Obj10Part03_Grp 1 : RS_Obj10_Msg03_CheckSum RS_Obj10_Msg03_AliveCounter RS_Obj10_XPos_Stdev RS_Obj10_YPos_Stdev RS_Obj10_XVelRel_Stdev RS_Obj10_YVelRel_Stdev RS_Obj10_XAccRel_Stdev RS_Obj10_YAccRel_Stdev RS_Obj10_ExstProb;
SIG_GROUP_ 1433 Obj09Part03_Grp 1 : RS_Obj09_Msg03_CheckSum RS_Obj09_Msg03_AliveCounter RS_Obj09_XPos_Stdev RS_Obj09_YPos_Stdev RS_Obj09_XVelRel_Stdev RS_Obj09_YVelRel_Stdev RS_Obj09_XAccRel_Stdev RS_Obj09_YAccRel_Stdev RS_Obj09_ExstProb;
SIG_GROUP_ 1432 Obj08Part03_Grp 1 : RS_Obj08_Msg03_CheckSum RS_Obj08_Msg03_AliveCounter RS_Obj08_XPos_Stdev RS_Obj08_YPos_Stdev RS_Obj08_XVelRel_Stdev RS_Obj08_YVelRel_Stdev RS_Obj08_XAccRel_Stdev RS_Obj08_YAccRel_Stdev RS_Obj08_ExstProb;
SIG_GROUP_ 1431 Obj07Part03_Grp 1 : RS_Obj07_Msg03_CheckSum RS_Obj07_Msg03_AliveCounter RS_Obj07_XPos_Stdev RS_Obj07_YPos_Stdev RS_Obj07_XVelRel_Stdev RS_Obj07_YVelRel_Stdev RS_Obj07_XAccRel_Stdev RS_Obj07_YAccRel_Stdev RS_Obj07_ExstProb;
SIG_GROUP_ 1430 Obj06Part03_Grp 1 : RS_Obj06_Msg03_CheckSum RS_Obj06_Msg03_AliveCounter RS_Obj06_XPos_Stdev RS_Obj06_YPos_Stdev RS_Obj06_XVelRel_Stdev RS_Obj06_YVelRel_Stdev RS_Obj06_XAccRel_Stdev RS_Obj06_YAccRel_Stdev RS_Obj06_ExstProb;
SIG_GROUP_ 1429 Obj05Part03_Grp 1 : RS_Obj05_Msg03_CheckSum RS_Obj05_Msg03_AliveCounter RS_Obj05_XPos_Stdev RS_Obj05_YPos_Stdev RS_Obj05_XVelRel_Stdev RS_Obj05_YVelRel_Stdev RS_Obj05_XAccRel_Stdev RS_Obj05_YAccRel_Stdev RS_Obj05_ExstProb;
SIG_GROUP_ 1428 Obj04Part03_Grp 1 : RS_Obj04_Msg03_CheckSum RS_Obj04_Msg03_AliveCounter RS_Obj04_XPos_Stdev RS_Obj04_YPos_Stdev RS_Obj04_XVelRel_Stdev RS_Obj04_YVelRel_Stdev RS_Obj04_XAccRel_Stdev RS_Obj04_YAccRel_Stdev RS_Obj04_ExstProb;
SIG_GROUP_ 1427 Obj03Part03_Grp 1 : RS_Obj03_Msg03_CheckSum RS_Obj03_Msg03_AliveCounter RS_Obj03_XPos_Stdev RS_Obj03_YPos_Stdev RS_Obj03_XVelRel_Stdev RS_Obj03_YVelRel_Stdev RS_Obj03_XAccRel_Stdev RS_Obj03_YAccRel_Stdev RS_Obj03_ExstProb;
SIG_GROUP_ 1426 Obj02Part03_Grp 1 : RS_Obj02_Msg03_CheckSum RS_Obj02_Msg03_AliveCounter RS_Obj02_XPos_Stdev RS_Obj02_YPos_Stdev RS_Obj02_XVelRel_Stdev RS_Obj02_YVelRel_Stdev RS_Obj02_XAccRel_Stdev RS_Obj02_YAccRel_Stdev RS_Obj02_ExstProb;
SIG_GROUP_ 1425 Obj01Part03_Grp 1 : RS_Obj01_Msg03_CheckSum RS_Obj01_Msg03_AliveCounter RS_Obj01_XPos_Stdev RS_Obj01_YPos_Stdev RS_Obj01_XVelRel_Stdev RS_Obj01_YVelRel_Stdev RS_Obj01_XAccRel_Stdev RS_Obj01_YAccRel_Stdev RS_Obj01_ExstProb;
SIG_GROUP_ 1424 Obj00Part03_Grp 1 : RS_Obj00_Msg03_CheckSum RS_Obj00_Msg03_AliveCounter RS_Obj00_XPos_Stdev RS_Obj00_YPos_Stdev RS_Obj00_XVelRel_Stdev RS_Obj00_YVelRel_Stdev RS_Obj00_XAccRel_Stdev RS_Obj00_YAccRel_Stdev RS_Obj00_ExstProb;
SIG_GROUP_ 1502 Detn14Part01_Grp 1 : RS_Detn14_Magn RS_Detn14_Msg01_CheckSum RS_Detn14_Msg01_AliveCounter RS_Detn14_PosY RS_Detn14_PosX RS_Detn14_ID;
SIG_GROUP_ 1516 Detn12Part02_Grp 1 : RS_Detn12_Elev RS_Detn12_YVelRel RS_Detn12_XVelRel RS_Detn12_Msg02_AliveCounter RS_Detn12_Msg02_CheckSum RS_Detn12_Qly RS_Detn12_MotnSts;
SIG_GROUP_ 1499 Detn11Part01_Grp 1 : RS_Detn11_Magn RS_Detn11_Msg01_CheckSum RS_Detn11_Msg01_AliveCounter RS_Detn11_PosX RS_Detn11_ID RS_Detn11_PosY;
SIG_GROUP_ 1513 Detn09Part02_Grp 1 : RS_Detn09_Elev RS_Detn09_YVelRel RS_Detn09_XVelRel RS_Detn09_Msg02_CheckSum RS_Detn09_Msg02_AliveCounter RS_Detn09_Qly RS_Detn09_MotnSts;
SIG_GROUP_ 1496 Detn08Part01_Grp 1 : RS_Detn08_Magn RS_Detn08_Msg01_CheckSum RS_Detn08_Msg01_AliveCounter RS_Detn08_PosX RS_Detn08_ID RS_Detn08_PosY;
SIG_GROUP_ 1510 Detn06Part02_Grp 1 : RS_Detn06_Elev RS_Detn06_YVelRel RS_Detn06_XVelRel RS_Detn06_Msg02_CheckSum RS_Detn06_Msg02_AliveCounter RS_Detn06_MotnSts RS_Detn06_Qly;
SIG_GROUP_ 1493 Detn05Part01_Grp 1 : RS_Detn05_Magn RS_Detn05_Msg01_AliveCounter RS_Detn05_Msg01_CheckSum RS_Detn05_PosY RS_Detn05_ID RS_Detn05_PosX;
SIG_GROUP_ 1507 Detn03Part02_Grp 1 : RS_Detn03_Elev RS_Detn03_YVelRel RS_Detn03_XVelRel RS_Detn03_Msg02_AliveCounter RS_Detn03_Msg02_CheckSum RS_Detn03_Qly RS_Detn03_MotnSts;
SIG_GROUP_ 1490 Detn02Part01_Grp 1 : RS_Detn02_Magn RS_Detn02_Msg01_AliveCounter RS_Detn02_Msg01_CheckSum RS_Detn02_PosY RS_Detn02_ID RS_Detn02_PosX;
SIG_GROUP_ 1504 Detn00Part02_Grp 1 : RS_Detn00_Elev RS_Detn00_YVelRel RS_Detn00_XVelRel RS_Detn00_MotnSts RS_Detn00_Msg02_CheckSum RS_Detn00_Msg02_AliveCounter RS_Detn00_Qly;
SIG_GROUP_ 1389 Obj29Part02_Grp 1 : RS_Obj29_Msg02_CheckSum RS_Obj29_Msg02_AliveCounter RS_Obj29_XAccAbsolute RS_Obj29_YAccAbsolute RS_Obj29_Classconf RS_Obj29_heading RS_Obj29_XVelAbsolute RS_Obj29_YVelAbsolute RS_Obj29_CtrkInd;
SIG_GROUP_ 1388 Obj28Part02_Grp 1 : RS_Obj28_Msg02_CheckSum RS_Obj28_Msg02_AliveCounter RS_Obj28_XAccAbsolute RS_Obj28_YAccAbsolute RS_Obj28_Classconf RS_Obj28_heading RS_Obj28_XVelAbsolute RS_Obj28_YVelAbsolute RS_Obj28_CtrkInd;
SIG_GROUP_ 1387 Obj27Part02_Grp 1 : RS_Obj27_Msg02_CheckSum RS_Obj27_Msg02_AliveCounter RS_Obj27_XAccAbsolute RS_Obj27_YAccAbsolute RS_Obj27_Classconf RS_Obj27_heading RS_Obj27_XVelAbsolute RS_Obj27_YVelAbsolute RS_Obj27_CtrkInd;
SIG_GROUP_ 1386 Obj26Part02_Grp 1 : RS_Obj26_Msg02_CheckSum RS_Obj26_Msg02_AliveCounter RS_Obj26_XAccAbsolute RS_Obj26_YAccAbsolute RS_Obj26_Classconf RS_Obj26_heading RS_Obj26_XVelAbsolute RS_Obj26_YVelAbsolute RS_Obj26_CtrkInd;
SIG_GROUP_ 1385 Obj25Part02_Grp 1 : RS_Obj25_Msg02_CheckSum RS_Obj25_Msg02_AliveCounter RS_Obj25_XAccAbsolute RS_Obj25_YAccAbsolute RS_Obj25_Classconf RS_Obj25_heading RS_Obj25_XVelAbsolute RS_Obj25_YVelAbsolute RS_Obj25_CtrkInd;
SIG_GROUP_ 1384 Obj24Part02_Grp 1 : RS_Obj24_Msg02_CheckSum RS_Obj24_Msg02_AliveCounter RS_Obj24_XAccAbsolute RS_Obj24_YAccAbsolute RS_Obj24_Classconf RS_Obj24_heading RS_Obj24_XVelAbsolute RS_Obj24_YVelAbsolute RS_Obj24_CtrkInd;
SIG_GROUP_ 1383 Obj23Part02_Grp 1 : RS_Obj23_Msg02_CheckSum RS_Obj23_Msg02_AliveCounter RS_Obj23_XAccAbsolute RS_Obj23_YAccAbsolute RS_Obj23_Classconf RS_Obj23_heading RS_Obj23_XVelAbsolute RS_Obj23_YVelAbsolute RS_Obj23_CtrkInd;
SIG_GROUP_ 1382 Obj22Part02_Grp 1 : RS_Obj22_Msg02_CheckSum RS_Obj22_Msg02_AliveCounter RS_Obj22_XAccAbsolute RS_Obj22_YAccAbsolute RS_Obj22_Classconf RS_Obj22_heading RS_Obj22_XVelAbsolute RS_Obj22_YVelAbsolute RS_Obj22_CtrkInd;
SIG_GROUP_ 1381 Obj21Part02_Grp 1 : RS_Obj21_Msg02_CheckSum RS_Obj21_Msg02_AliveCounter RS_Obj21_XAccAbsolute RS_Obj21_YAccAbsolute RS_Obj21_Classconf RS_Obj21_heading RS_Obj21_XVelAbsolute RS_Obj21_YVelAbsolute RS_Obj21_CtrkInd;
SIG_GROUP_ 1380 Obj20Part02_Grp 1 : RS_Obj20_Msg02_CheckSum RS_Obj20_Msg02_AliveCounter RS_Obj20_XAccAbsolute RS_Obj20_YAccAbsolute RS_Obj20_Classconf RS_Obj20_heading RS_Obj20_XVelAbsolute RS_Obj20_YVelAbsolute RS_Obj20_CtrkInd;
SIG_GROUP_ 1379 Obj19Part02_Grp 1 : RS_Obj19_Msg02_CheckSum RS_Obj19_Msg02_AliveCounter RS_Obj19_XAccAbsolute RS_Obj19_YAccAbsolute RS_Obj19_Classconf RS_Obj19_heading RS_Obj19_XVelAbsolute RS_Obj19_YVelAbsolute RS_Obj19_CtrkInd;
SIG_GROUP_ 1378 Obj18Part02_Grp 1 : RS_Obj18_Msg02_CheckSum RS_Obj18_Msg02_AliveCounter RS_Obj18_XAccAbsolute RS_Obj18_YAccAbsolute RS_Obj18_Classconf RS_Obj18_heading RS_Obj18_XVelAbsolute RS_Obj18_YVelAbsolute RS_Obj18_CtrkInd;
SIG_GROUP_ 1377 Obj17Part02_Grp 1 : RS_Obj17_Msg02_CheckSum RS_Obj17_Msg02_AliveCounter RS_Obj17_XAccAbsolute RS_Obj17_YAccAbsolute RS_Obj17_Classconf RS_Obj17_heading RS_Obj17_XVelAbsolute RS_Obj17_YVelAbsolute RS_Obj17_CtrkInd;
SIG_GROUP_ 1376 Obj16Part02_Grp 1 : RS_Obj16_Msg02_CheckSum RS_Obj16_Msg02_AliveCounter RS_Obj16_XAccAbsolute RS_Obj16_YAccAbsolute RS_Obj16_Classconf RS_Obj16_heading RS_Obj16_XVelAbsolute RS_Obj16_YVelAbsolute RS_Obj16_CtrkInd;
SIG_GROUP_ 1375 Obj15Part02_Grp 1 : RS_Obj15_Msg02_CheckSum RS_Obj15_Msg02_AliveCounter RS_Obj15_XAccAbsolute RS_Obj15_YAccAbsolute RS_Obj15_Classconf RS_Obj15_heading RS_Obj15_XVelAbsolute RS_Obj15_YVelAbsolute RS_Obj15_CtrkInd;
SIG_GROUP_ 1374 Obj14Part02_Grp 1 : RS_Obj14_Msg02_CheckSum RS_Obj14_Msg02_AliveCounter RS_Obj14_XAccAbsolute RS_Obj14_YAccAbsolute RS_Obj14_Classconf RS_Obj14_heading RS_Obj14_XVelAbsolute RS_Obj14_YVelAbsolute RS_Obj14_CtrkInd;
SIG_GROUP_ 1373 Obj13Part02_Grp 1 : RS_Obj13_Msg02_CheckSum RS_Obj13_Msg02_AliveCounter RS_Obj13_XAccAbsolute RS_Obj13_YAccAbsolute RS_Obj13_Classconf RS_Obj13_heading RS_Obj13_XVelAbsolute RS_Obj13_YVelAbsolute RS_Obj13_CtrkInd;
SIG_GROUP_ 1372 Obj12Part02_Grp 1 : RS_Obj12_Msg02_CheckSum RS_Obj12_Msg02_AliveCounter RS_Obj12_XAccAbsolute RS_Obj12_YAccAbsolute RS_Obj12_Classconf RS_Obj12_heading RS_Obj12_XVelAbsolute RS_Obj12_YVelAbsolute RS_Obj12_CtrkInd;
SIG_GROUP_ 1371 Obj11Part02_Grp 1 : RS_Obj11_Msg02_CheckSum RS_Obj11_Msg02_AliveCounter RS_Obj11_XAccAbsolute RS_Obj11_YAccAbsolute RS_Obj11_Classconf RS_Obj11_heading RS_Obj11_XVelAbsolute RS_Obj11_YVelAbsolute RS_Obj11_CtrkInd;
SIG_GROUP_ 1370 Obj10Part02_Grp 1 : RS_Obj10_Msg02_CheckSum RS_Obj10_Msg02_AliveCounter RS_Obj10_XAccAbsolute RS_Obj10_YAccAbsolute RS_Obj10_Classconf RS_Obj10_heading RS_Obj10_XVelAbsolute RS_Obj10_YVelAbsolute RS_Obj10_CtrkInd;
SIG_GROUP_ 1369 Obj09Part02_Grp 1 : RS_Obj09_Msg02_CheckSum RS_Obj09_Msg02_AliveCounter RS_Obj09_XAccAbsolute RS_Obj09_YAccAbsolute RS_Obj09_Classconf RS_Obj09_heading RS_Obj09_XVelAbsolute RS_Obj09_YVelAbsolute RS_Obj09_CtrkInd;
SIG_GROUP_ 1368 Obj08Part02_Grp 1 : RS_Obj08_Msg02_CheckSum RS_Obj08_Msg02_AliveCounter RS_Obj08_XAccAbsolute RS_Obj08_YAccAbsolute RS_Obj08_Classconf RS_Obj08_heading RS_Obj08_XVelAbsolute RS_Obj08_YVelAbsolute RS_Obj08_CtrkInd;
SIG_GROUP_ 1367 Obj07Part02_Grp 1 : RS_Obj07_Msg02_CheckSum RS_Obj07_Msg02_AliveCounter RS_Obj07_XAccAbsolute RS_Obj07_YAccAbsolute RS_Obj07_Classconf RS_Obj07_heading RS_Obj07_XVelAbsolute RS_Obj07_YVelAbsolute RS_Obj07_CtrkInd;
SIG_GROUP_ 1366 Obj06Part02_Grp 1 : RS_Obj06_Msg02_CheckSum RS_Obj06_Msg02_AliveCounter RS_Obj06_XAccAbsolute RS_Obj06_YAccAbsolute RS_Obj06_Classconf RS_Obj06_heading RS_Obj06_XVelAbsolute RS_Obj06_YVelAbsolute RS_Obj06_CtrkInd;
SIG_GROUP_ 1365 Obj05Part02_Grp 1 : RS_Obj05_Msg02_CheckSum RS_Obj05_Msg02_AliveCounter RS_Obj05_XAccAbsolute RS_Obj05_YAccAbsolute RS_Obj05_Classconf RS_Obj05_heading RS_Obj05_XVelAbsolute RS_Obj05_YVelAbsolute RS_Obj05_CtrkInd;
SIG_GROUP_ 1364 Obj04Part02_Grp 1 : RS_Obj04_Msg02_CheckSum RS_Obj04_Msg02_AliveCounter RS_Obj04_XAccAbsolute RS_Obj04_YAccAbsolute RS_Obj04_Classconf RS_Obj04_heading RS_Obj04_XVelAbsolute RS_Obj04_YVelAbsolute RS_Obj04_CtrkInd;
SIG_GROUP_ 1363 Obj03Part02_Grp 1 : RS_Obj03_Msg02_CheckSum RS_Obj03_Msg02_AliveCounter RS_Obj03_XAccAbsolute RS_Obj03_YAccAbsolute RS_Obj03_Classconf RS_Obj03_heading RS_Obj03_XVelAbsolute RS_Obj03_YVelAbsolute RS_Obj03_CtrkInd;
SIG_GROUP_ 1362 Obj02Part02_Grp 1 : RS_Obj02_Msg02_CheckSum RS_Obj02_Msg02_AliveCounter RS_Obj02_XAccAbsolute RS_Obj02_YAccAbsolute RS_Obj02_Classconf RS_Obj02_heading RS_Obj02_XVelAbsolute RS_Obj02_YVelAbsolute RS_Obj02_CtrkInd;
SIG_GROUP_ 1361 Obj01Part02_Grp 1 : RS_Obj01_Msg02_CheckSum RS_Obj01_Msg02_AliveCounter RS_Obj01_XAccAbsolute RS_Obj01_YAccAbsolute RS_Obj01_Classconf RS_Obj01_heading RS_Obj01_XVelAbsolute RS_Obj01_YVelAbsolute RS_Obj01_CtrkInd;
SIG_GROUP_ 1517 Detn13Part02_Grp 1 : RS_Detn13_Elev RS_Detn13_YVelRel RS_Detn13_XVelRel RS_Detn13_Msg02_CheckSum RS_Detn13_Msg02_AliveCounter RS_Detn13_MotnSts RS_Detn13_Qly;
SIG_GROUP_ 1500 Detn12Part01_Grp 1 : RS_Detn12_Magn RS_Detn12_Msg01_CheckSum RS_Detn12_Msg01_AliveCounter RS_Detn12_PosY RS_Detn12_ID RS_Detn12_PosX;
SIG_GROUP_ 1514 Detn10Part02_Grp 1 : RS_Detn10_Elev RS_Detn10_YVelRel RS_Detn10_XVelRel RS_Detn10_Msg02_AliveCounter RS_Detn10_Msg02_CheckSum RS_Detn10_Qly RS_Detn10_MotnSts;
SIG_GROUP_ 1497 Detn09Part01_Grp 1 : RS_Detn09_Magn RS_Detn09_Msg01_CheckSum RS_Detn09_Msg01_AliveCounter RS_Detn09_PosX RS_Detn09_ID RS_Detn09_PosY;
SIG_GROUP_ 1511 Detn07Part02_Grp 1 : RS_Detn07_Elev RS_Detn07_XVelRel RS_Detn07_YVelRel RS_Detn07_Msg02_CheckSum RS_Detn07_Msg02_AliveCounter RS_Detn07_Qly RS_Detn07_MotnSts;
SIG_GROUP_ 1494 Detn06Part01_Grp 1 : RS_Detn06_Magn RS_Detn06_Msg01_CheckSum RS_Detn06_Msg01_AliveCounter RS_Detn06_PosX RS_Detn06_ID RS_Detn06_PosY;
SIG_GROUP_ 1508 Detn04Part02_Grp 1 : RS_Detn04_Elev RS_Detn04_YVelRel RS_Detn04_XVelRel RS_Detn04_Msg02_CheckSum RS_Detn04_Msg02_AliveCounter RS_Detn04_Qly RS_Detn04_MotnSts;
SIG_GROUP_ 1491 Detn03Part01_Grp 1 : RS_Detn03_Magn RS_Detn03_Msg01_CheckSum RS_Detn03_Msg01_AliveCounter RS_Detn03_PosY RS_Detn03_ID RS_Detn03_PosX;
SIG_GROUP_ 1505 Detn01Part02_Grp 1 : RS_Detn01_Elev RS_Detn01_YVelRel RS_Detn01_XVelRel RS_Detn01_Msg02_AliveCounter RS_Detn01_Msg02_CheckSum RS_Detn01_Qly RS_Detn01_MotnSts;
SIG_GROUP_ 1488 Detn00Part01_Grp 1 : RS_Detn00_Magn RS_Detn00_Msg01_CheckSum RS_Detn00_Msg01_AliveCounter RS_Detn00_PosY RS_Detn00_ID RS_Detn00_PosX;
SIG_GROUP_ 1341 Obj29Part01_Grp 1 : RS_Obj29_Msg01_CheckSum RS_Obj29_Msg01_AliveCounter RS_Obj29_ElevClass RS_Obj29_ElevConf RS_Obj29_ID RS_Obj29_MeasFlag RS_Obj29_Type RS_Obj29_ValidFlag RS_Obj29_XPos RS_Obj29_YPos RS_Obj29_MotionPattern;
SIG_GROUP_ 1340 Obj28Part01_Grp 1 : RS_Obj28_Msg01_AliveCounter RS_Obj28_Msg01_CheckSum RS_Obj28_Type RS_Obj28_MeasFlag RS_Obj28_YPos RS_Obj28_XPos RS_Obj28_ElevConf RS_Obj28_ElevClass RS_Obj28_MotionPattern RS_Obj28_ValidFlag RS_Obj28_ID;
SIG_GROUP_ 1339 Obj27Part01_Grp 1 : RS_Obj27_Msg01_AliveCounter RS_Obj27_Msg01_CheckSum RS_Obj27_Type RS_Obj27_MeasFlag RS_Obj27_YPos RS_Obj27_XPos RS_Obj27_ElevConf RS_Obj27_ElevClass RS_Obj27_MotionPattern RS_Obj27_ValidFlag RS_Obj27_ID;
SIG_GROUP_ 1338 Obj26Part01_Grp 1 : RS_Obj26_Msg01_AliveCounter RS_Obj26_Msg01_CheckSum RS_Obj26_Type RS_Obj26_MeasFlag RS_Obj26_YPos RS_Obj26_XPos RS_Obj26_ElevConf RS_Obj26_ElevClass RS_Obj26_MotionPattern RS_Obj26_ValidFlag RS_Obj26_ID;
SIG_GROUP_ 1337 Obj25Part01_Grp 1 : RS_Obj25_Msg01_AliveCounter RS_Obj25_Msg01_CheckSum RS_Obj25_Type RS_Obj25_MeasFlag RS_Obj25_YPos RS_Obj25_XPos RS_Obj25_ElevConf RS_Obj25_ElevClass RS_Obj25_MotionPattern RS_Obj25_ValidFlag RS_Obj25_ID;
SIG_GROUP_ 1336 Obj24Part01_Grp 1 : RS_Obj24_Msg01_AliveCounter RS_Obj24_Msg01_CheckSum RS_Obj24_Type RS_Obj24_MeasFlag RS_Obj24_YPos RS_Obj24_XPos RS_Obj24_ElevConf RS_Obj24_ElevClass RS_Obj24_MotionPattern RS_Obj24_ValidFlag RS_Obj24_ID;
SIG_GROUP_ 1335 Obj23Part01_Grp 1 : RS_Obj23_Msg01_AliveCounter RS_Obj23_Msg01_CheckSum RS_Obj23_Type RS_Obj23_MeasFlag RS_Obj23_YPos RS_Obj23_XPos RS_Obj23_ElevConf RS_Obj23_ElevClass RS_Obj23_MotionPattern RS_Obj23_ValidFlag RS_Obj23_ID;
SIG_GROUP_ 1334 Obj22Part01_Grp 1 : RS_Obj22_Msg01_AliveCounter RS_Obj22_Msg01_CheckSum RS_Obj22_Type RS_Obj22_MeasFlag RS_Obj22_YPos RS_Obj22_XPos RS_Obj22_ElevConf RS_Obj22_ElevClass RS_Obj22_MotionPattern RS_Obj22_ValidFlag RS_Obj22_ID;
SIG_GROUP_ 1333 Obj21Part01_Grp 1 : RS_Obj21_Msg01_AliveCounter RS_Obj21_Msg01_CheckSum RS_Obj21_Type RS_Obj21_MeasFlag RS_Obj21_YPos RS_Obj21_XPos RS_Obj21_ElevConf RS_Obj21_ElevClass RS_Obj21_MotionPattern RS_Obj21_ValidFlag RS_Obj21_ID;
SIG_GROUP_ 1332 Obj20Part01_Grp 1 : RS_Obj20_Msg01_AliveCounter RS_Obj20_Msg01_CheckSum RS_Obj20_Type RS_Obj20_MeasFlag RS_Obj20_YPos RS_Obj20_XPos RS_Obj20_ElevConf RS_Obj20_ElevClass RS_Obj20_MotionPattern RS_Obj20_ValidFlag RS_Obj20_ID;
SIG_GROUP_ 1331 Obj19Part01_Grp 1 : RS_Obj19_Msg01_AliveCounter RS_Obj19_Msg01_CheckSum RS_Obj19_Type RS_Obj19_MeasFlag RS_Obj19_YPos RS_Obj19_XPos RS_Obj19_ElevConf RS_Obj19_ElevClass RS_Obj19_MotionPattern RS_Obj19_ValidFlag RS_Obj19_ID;
SIG_GROUP_ 1330 Obj18Part01_Grp 1 : RS_Obj18_Msg01_AliveCounter RS_Obj18_Msg01_CheckSum RS_Obj18_Type RS_Obj18_MeasFlag RS_Obj18_YPos RS_Obj18_XPos RS_Obj18_ElevConf RS_Obj18_ElevClass RS_Obj18_MotionPattern RS_Obj18_ValidFlag RS_Obj18_ID;
SIG_GROUP_ 1329 Obj17Part01_Grp 1 : RS_Obj17_Msg01_AliveCounter RS_Obj17_Msg01_CheckSum RS_Obj17_Type RS_Obj17_MeasFlag RS_Obj17_YPos RS_Obj17_XPos RS_Obj17_ElevConf RS_Obj17_ElevClass RS_Obj17_MotionPattern RS_Obj17_ValidFlag RS_Obj17_ID;
SIG_GROUP_ 1328 Obj16Part01_Grp 1 : RS_Obj16_Msg01_AliveCounter RS_Obj16_Msg01_CheckSum RS_Obj16_Type RS_Obj16_MeasFlag RS_Obj16_YPos RS_Obj16_XPos RS_Obj16_ElevConf RS_Obj16_ElevClass RS_Obj16_MotionPattern RS_Obj16_ValidFlag RS_Obj16_ID;
SIG_GROUP_ 1327 Obj15Part01_Grp 1 : RS_Obj15_Msg01_AliveCounter RS_Obj15_Msg01_CheckSum RS_Obj15_Type RS_Obj15_MeasFlag RS_Obj15_YPos RS_Obj15_XPos RS_Obj15_ElevConf RS_Obj15_ElevClass RS_Obj15_MotionPattern RS_Obj15_ValidFlag RS_Obj15_ID;
SIG_GROUP_ 1326 Obj14Part01_Grp 1 : RS_Obj14_Msg01_AliveCounter RS_Obj14_Msg01_CheckSum RS_Obj14_Type RS_Obj14_MeasFlag RS_Obj14_YPos RS_Obj14_XPos RS_Obj14_ElevConf RS_Obj14_ElevClass RS_Obj14_MotionPattern RS_Obj14_ValidFlag RS_Obj14_ID;
SIG_GROUP_ 1325 Obj13Part01_Grp 1 : RS_Obj13_Msg01_AliveCounter RS_Obj13_Msg01_CheckSum RS_Obj13_Type RS_Obj13_MeasFlag RS_Obj13_YPos RS_Obj13_XPos RS_Obj13_ElevConf RS_Obj13_ElevClass RS_Obj13_MotionPattern RS_Obj13_ValidFlag RS_Obj13_ID;
SIG_GROUP_ 1324 Obj12Part01_Grp 1 : RS_Obj12_Msg01_AliveCounter RS_Obj12_Msg01_CheckSum RS_Obj12_Type RS_Obj12_MeasFlag RS_Obj12_YPos RS_Obj12_XPos RS_Obj12_ElevConf RS_Obj12_ElevClass RS_Obj12_MotionPattern RS_Obj12_ValidFlag RS_Obj12_ID;
SIG_GROUP_ 1323 Obj11Part01_Grp 1 : RS_Obj11_Msg01_AliveCounter RS_Obj11_Msg01_CheckSum RS_Obj11_Type RS_Obj11_MeasFlag RS_Obj11_YPos RS_Obj11_XPos RS_Obj11_ElevConf RS_Obj11_ElevClass RS_Obj11_MotionPattern RS_Obj11_ValidFlag RS_Obj11_ID;
SIG_GROUP_ 1322 Obj10Part01_Grp 1 : RS_Obj10_Msg01_AliveCounter RS_Obj10_Msg01_CheckSum RS_Obj10_Type RS_Obj10_MeasFlag RS_Obj10_YPos RS_Obj10_XPos RS_Obj10_ElevConf RS_Obj10_ElevClass RS_Obj10_MotionPattern RS_Obj10_ValidFlag RS_Obj10_ID;
SIG_GROUP_ 1321 Obj09Part01_Grp 1 : RS_Obj09_Msg01_AliveCounter RS_Obj09_Msg01_CheckSum RS_Obj09_Type RS_Obj09_MeasFlag RS_Obj09_YPos RS_Obj09_XPos RS_Obj09_ElevConf RS_Obj09_ElevClass RS_Obj09_MotionPattern RS_Obj09_ValidFlag RS_Obj09_ID;
SIG_GROUP_ 1320 Obj08Part01_Grp 1 : RS_Obj08_Msg01_AliveCounter RS_Obj08_Msg01_CheckSum RS_Obj08_Type RS_Obj08_MeasFlag RS_Obj08_YPos RS_Obj08_XPos RS_Obj08_ElevConf RS_Obj08_ElevClass RS_Obj08_MotionPattern RS_Obj08_ValidFlag RS_Obj08_ID;
SIG_GROUP_ 1319 Obj07Part01_Grp 1 : RS_Obj07_Msg01_AliveCounter RS_Obj07_Msg01_CheckSum RS_Obj07_Type RS_Obj07_MeasFlag RS_Obj07_YPos RS_Obj07_XPos RS_Obj07_ElevConf RS_Obj07_ElevClass RS_Obj07_MotionPattern RS_Obj07_ValidFlag RS_Obj07_ID;
SIG_GROUP_ 1318 Obj06Part01_Grp 1 : RS_Obj06_Msg01_AliveCounter RS_Obj06_Msg01_CheckSum RS_Obj06_Type RS_Obj06_MeasFlag RS_Obj06_YPos RS_Obj06_XPos RS_Obj06_ElevConf RS_Obj06_ElevClass RS_Obj06_MotionPattern RS_Obj06_ValidFlag RS_Obj06_ID;
SIG_GROUP_ 1317 Obj05Part01_Grp 1 : RS_Obj05_Msg01_AliveCounter RS_Obj05_Msg01_CheckSum RS_Obj05_Type RS_Obj05_MeasFlag RS_Obj05_YPos RS_Obj05_XPos RS_Obj05_ElevConf RS_Obj05_ElevClass RS_Obj05_MotionPattern RS_Obj05_ValidFlag RS_Obj05_ID;
SIG_GROUP_ 1316 Obj04Part01_Grp 1 : RS_Obj04_Msg01_AliveCounter RS_Obj04_Msg01_CheckSum RS_Obj04_Type RS_Obj04_MeasFlag RS_Obj04_YPos RS_Obj04_XPos RS_Obj04_ElevConf RS_Obj04_ElevClass RS_Obj04_MotionPattern RS_Obj04_ValidFlag RS_Obj04_ID;
SIG_GROUP_ 1315 Obj03Part01_Grp 1 : RS_Obj03_Msg01_AliveCounter RS_Obj03_Msg01_CheckSum RS_Obj03_Type RS_Obj03_MeasFlag RS_Obj03_YPos RS_Obj03_XPos RS_Obj03_ElevConf RS_Obj03_ElevClass RS_Obj03_MotionPattern RS_Obj03_ValidFlag RS_Obj03_ID;
SIG_GROUP_ 1314 Obj02Part01_Grp 1 : RS_Obj02_Msg01_AliveCounter RS_Obj02_Msg01_CheckSum RS_Obj02_Type RS_Obj02_MeasFlag RS_Obj02_YPos RS_Obj02_XPos RS_Obj02_ElevConf RS_Obj02_ElevClass RS_Obj02_MotionPattern RS_Obj02_ValidFlag RS_Obj02_ID;
SIG_GROUP_ 1313 Obj01Part01_Grp 1 : RS_Obj01_Msg01_AliveCounter RS_Obj01_Msg01_CheckSum RS_Obj01_Type RS_Obj01_MeasFlag RS_Obj01_YPos RS_Obj01_XPos RS_Obj01_ElevConf RS_Obj01_ElevClass RS_Obj01_MotionPattern RS_Obj01_ValidFlag RS_Obj01_ID;
SIG_GROUP_ 1360 Obj00Part02_Grp 1 : RS_Obj00_Msg02_CheckSum RS_Obj00_Msg02_AliveCounter RS_Obj00_XAccAbsolute RS_Obj00_YAccAbsolute RS_Obj00_Classconf RS_Obj00_heading RS_Obj00_XVelAbsolute RS_Obj00_YVelAbsolute RS_Obj00_CtrkInd;
SIG_GROUP_ 1312 Obj00Part01_Grp 1 : RS_Obj00_Msg01_AliveCounter RS_Obj00_Msg01_CheckSum RS_Obj00_Type RS_Obj00_MeasFlag RS_Obj00_YPos RS_Obj00_XPos RS_Obj00_ElevConf RS_Obj00_ElevClass RS_Obj00_MotionPattern RS_Obj00_ValidFlag RS_Obj00_ID;
SIG_GROUP_ 1472 RSStatus_Grp 1 : RS_Latency RS_Warn_RCW RS_Warn_SDO RS_Warn_RCTA RS_Warn_LCA RS_Warn_BSD RS_Sts_Interference RS_Sts_Blkg RS_Sts_MisAlign RS_Sts_Failure RS_Msg_CheckSum RS_Msg_AliveCounter;
SIG_GROUP_ 357 GearPosition_Grp 1 : VCU_ModeControl_AliveCounter VCU_ModeControl_CheckSum VCU_CurrentGearPosition;
SIG_GROUP_ 304 YawRate_Grp 1 : YRS_LateralSensorState YRS1_CheckSum YRS_LateralAcce YRS_YawRate YRS1_AliveCounter YRS_YawRateSensorState;
SIG_GROUP_ 305 LongitAcce_Grp 1 : YRS_LongitSensorState YRS2_CheckSum YRS_LongitAcce YRS2_AliveCounter;
SIG_GROUP_ 224 SteerWheelAngle_Grp 1 : SAS_FailureSts SAS_Status_AliveCounter SAS_Status_CheckSum SAS_SteerWheelAngle;
SIG_GROUP_ 293 VehicleSpeed_Grp 1 : ESC_VehicleSpeedInvalid ESC_VehicleSpeed ESC_Status_AliveCounter ESC_Status_CheckSum;
SIG_GROUP_ 133 EngStatus_Grp 1 : EMS_EngineRPM_AliveCounter EMS_EngineRPM_CheckSum EMS_EngStatus;
SIG_GROUP_ 275 GearPosition_Grp 1 : TCU_Status_AliveCounter TCU_CurrentGearPosition TCU_Status_CheckSum;
